VERSION ""

NS_ :

BS_:

BU_: SBZA_R_LS SBZA_L_LS VIS2_LS SDM_LS PEPS_LS UPA_LS PTM_LS MSM_LS HFP_LS EOCM_F_LS ECC_LS DCAC_LS CGM_LS BSM_LS BCM_LS AOS_LS

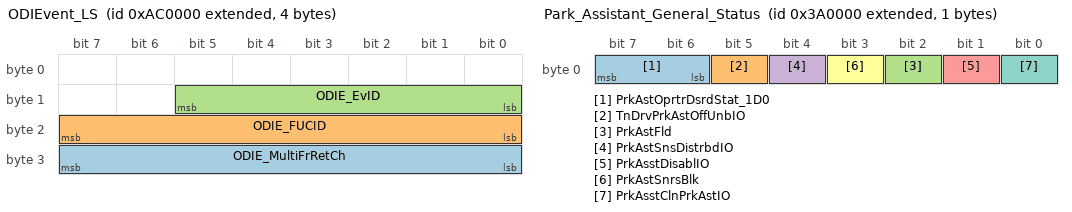
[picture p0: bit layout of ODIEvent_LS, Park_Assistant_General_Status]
BO_ 2158755840 ODIEvent_LS: 4 BCM_LS
 SG_ ODIE_MultiFrRetCh : 31|8@0+ (1,0) [0|255] ""  CGM_LS
 SG_ ODIE_FUCID : 23|8@0+ (1,0) [0|255] ""  CGM_LS
 SG_ ODIE_EvID : 13|6@0+ (1,0) [0|63] ""  CGM_LS

BO_ 2151284736 Park_Assistant_General_Status: 1 EOCM_F_LS
 SG_ PrkAstOprtrDsrdStat_1D0 : 7|2@0+ (1,0) [0|3] ""  SBZA_R_LS,SBZA_L_LS,CGM_LS
 SG_ TnDrvPrkAstOffUnbIO : 5|1@0+ (1,0) [0|1] ""  CGM_LS
 SG_ PrkAstFld : 2|1@0+ (1,0) [0|1] ""  CGM_LS
 SG_ PrkAstSnsDistrbdIO : 4|1@0+ (1,0) [0|1] ""  CGM_LS
 SG_ PrkAsstDisablIO : 1|1@0+ (1,0) [0|1] ""  CGM_LS
 SG_ PrkAstSnrsBlk : 3|1@0+ (1,0) [0|1] ""  CGM_LS
 SG_ PrkAsstClnPrkAstIO : 0|1@0+ (1,0) [0|1] ""  CGM_LS

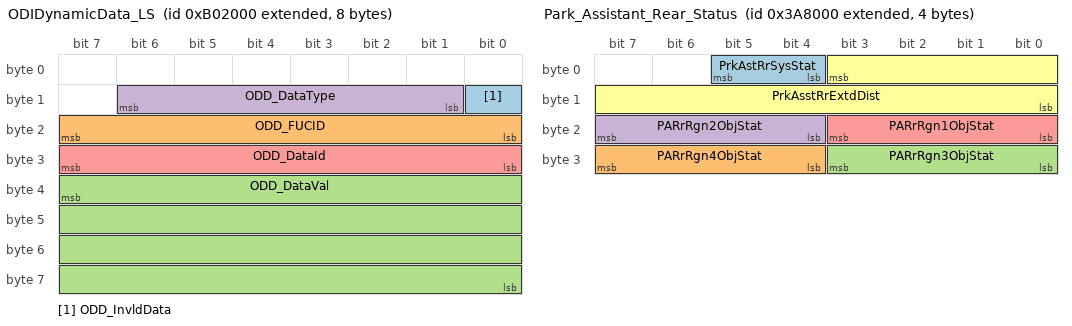
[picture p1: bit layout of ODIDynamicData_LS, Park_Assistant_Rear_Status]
BO_ 2159026176 ODIDynamicData_LS: 8 BCM_LS
 SG_ ODD_InvldData : 8|1@0+ (1,0) [0|1] ""  CGM_LS
 SG_ ODD_FUCID : 23|8@0+ (1,0) [0|255] ""  CGM_LS
 SG_ ODD_DataVal : 39|32@0+ (1,0) [0|4294967295] ""  CGM_LS
 SG_ ODD_DataType : 14|6@0+ (1,0) [0|63] ""  CGM_LS
 SG_ ODD_DataId : 31|8@0+ (1,0) [0|255] ""  CGM_LS

BO_ 2158936064 ODIEnumDynamicData_LS: 8 BCM_LS
 SG_ ODIEDD_Data18Value : 50|3@0+ (1,0) [0|7] ""  CGM_LS
 SG_ ODIEDD_Data17Value : 53|3@0+ (1,0) [0|7] ""  CGM_LS
 SG_ ODIEDD_Data16Value : 40|3@0+ (1,0) [0|7] ""  CGM_LS
 SG_ ODIEDD_Data15Value : 43|3@0+ (1,0) [0|7] ""  CGM_LS
 SG_ ODIEDD_Data14Value : 46|3@0+ (1,0) [0|7] ""  CGM_LS
 SG_ ODIEDD_Data13Value : 33|3@0+ (1,0) [0|7] ""  CGM_LS
 SG_ ODIEDD_Data12Value : 36|3@0+ (1,0) [0|7] ""  CGM_LS
 SG_ ODIEDD_Data11Value : 39|3@0+ (1,0) [0|7] ""  CGM_LS
 SG_ ODIEDD_Data10Value : 26|3@0+ (1,0) [0|7] ""  CGM_LS
 SG_ ODIEDD_Data9Value : 29|3@0+ (1,0) [0|7] ""  CGM_LS
 SG_ ODIEDD_Data8Value : 16|3@0+ (1,0) [0|7] ""  CGM_LS
 SG_ ODIEDD_Data7Value : 19|3@0+ (1,0) [0|7] ""  CGM_LS
 SG_ ODIEDD_Data6Value : 22|3@0+ (1,0) [0|7] ""  CGM_LS
 SG_ ODIEDD_Data5Value : 9|3@0+ (1,0) [0|7] ""  CGM_LS
 SG_ ODIEDD_Data4Value : 12|3@0+ (1,0) [0|7] ""  CGM_LS
 SG_ ODIEDD_Data3Value : 15|3@0+ (1,0) [0|7] ""  CGM_LS
 SG_ ODIEDD_Data2Value : 2|3@0+ (1,0) [0|7] ""  CGM_LS
 SG_ ODIEDD_Data1Value : 5|3@0+ (1,0) [0|7] ""  CGM_LS
 SG_ ODIEDD_FUCID : 63|8@0+ (1,0) [0|255] ""  CGM_LS

BO_ 2151317504 Park_Assistant_Rear_Status: 4 EOCM_F_LS
 SG_ PrkAstRrSysStat : 5|2@0+ (1,0) [0|3] ""  SBZA_R_LS,SBZA_L_LS,CGM_LS
 SG_ PARrRgn4ObjStat : 31|4@0+ (1,0) [0|15] ""  SBZA_R_LS,SBZA_L_LS,CGM_LS
 SG_ PARrRgn3ObjStat : 27|4@0+ (1,0) [0|15] ""  SBZA_R_LS,SBZA_L_LS,CGM_LS
 SG_ PARrRgn2ObjStat : 23|4@0+ (1,0) [0|15] ""  SBZA_R_LS,SBZA_L_LS,CGM_LS
 SG_ PARrRgn1ObjStat : 19|4@0+ (1,0) [0|15] ""  SBZA_R_LS,SBZA_L_LS,CGM_LS
 SG_ PrkAsstRrExtdDist : 3|12@0+ (0.01,0) [0|40.95] "m"  SBZA_R_LS,SBZA_L_LS,CGM_LS

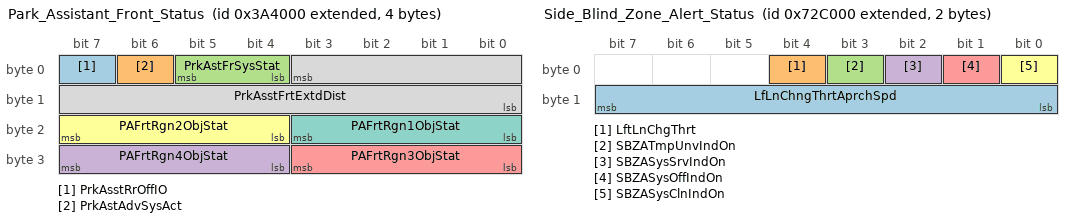
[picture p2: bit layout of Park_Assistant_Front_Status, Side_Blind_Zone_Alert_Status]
BO_ 2151301120 Park_Assistant_Front_Status: 4 UPA_LS
 SG_ PrkAsstRrOffIO : 7|1@0+ (1,0) [0|1] ""  CGM_LS
 SG_ PrkAstAdvSysAct : 6|1@0+ (1,0) [0|1] ""  EOCM_F_LS,CGM_LS,BCM_LS
 SG_ PrkAstFrSysStat : 5|2@0+ (1,0) [0|3] ""  CGM_LS
 SG_ PAFrtRgn4ObjStat : 31|4@0+ (1,0) [0|15] ""  CGM_LS
 SG_ PAFrtRgn3ObjStat : 27|4@0+ (1,0) [0|15] ""  CGM_LS
 SG_ PAFrtRgn2ObjStat : 23|4@0+ (1,0) [0|15] ""  CGM_LS
 SG_ PAFrtRgn1ObjStat : 19|4@0+ (1,0) [0|15] ""  CGM_LS
 SG_ PrkAsstFrtExtdDist : 3|12@0+ (0.01,0) [0|40.95] "m"  CGM_LS

BO_ 2155003904 Side_Blind_Zone_Alert_Status: 2 UPA_LS
 SG_ LfLnChngThrtAprchSpd : 15|8@0- (1,0) [-128|127] "km/h"  CGM_LS,BCM_LS
 SG_ LftLnChgThrt : 4|1@0+ (1,0) [0|1] ""  VIS2_LS,EOCM_F_LS,CGM_LS,BCM_LS
 SG_ SBZATmpUnvIndOn : 3|1@0+ (1,0) [0|1] ""  SBZA_R_LS,CGM_LS
 SG_ SBZASysSrvIndOn : 2|1@0+ (1,0) [0|1] ""  SBZA_R_LS,CGM_LS
 SG_ SBZASysOffIndOn : 1|1@0+ (1,0) [0|1] ""  SBZA_R_LS,CGM_LS
 SG_ SBZASysClnIndOn : 0|1@0+ (1,0) [0|1] ""  SBZA_R_LS,CGM_LS

BO_ 1369 UUDT_Resp_From_UPA_APA_LS: 8 UPA_LS
 SG_ DgnInf_LS559 : 7|64@0+ (1,0) [0|1.84467440737096E+019] ""  CGM_LS

BO_ 1625 USDT_Resp_From_UPA_APA_LS: 8 UPA_LS
 SG_ DgnInf : 7|64@0+ (1,0) [0|1.84467440737096E+019] ""  CGM_LS

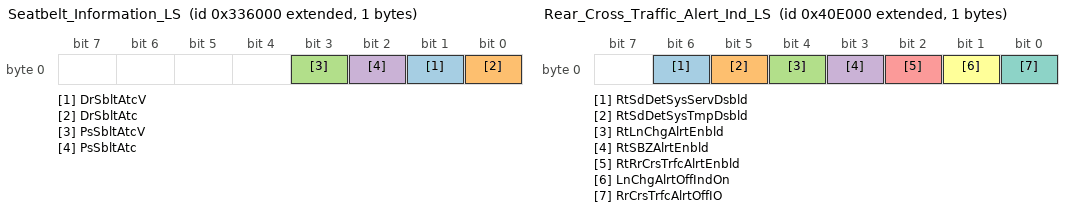
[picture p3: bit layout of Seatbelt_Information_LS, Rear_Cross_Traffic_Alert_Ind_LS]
BO_ 2150850560 Seatbelt_Information_LS: 1 SDM_LS
 SG_ DrSbltAtcV : 1|1@0+ (1,0) [0|1] ""  EOCM_F_LS,CGM_LS,BCM_LS
 SG_ DrSbltAtc : 0|1@0+ (1,0) [0|1] ""  EOCM_F_LS,CGM_LS,BCM_LS
 SG_ PsSbltAtcV : 3|1@0+ (1,0) [0|1] ""  ECC_LS,CGM_LS,BCM_LS,AOS_LS
 SG_ PsSbltAtc : 2|1@0+ (1,0) [0|1] ""  ECC_LS,CGM_LS,BCM_LS,AOS_LS

BO_ 2151735296 Rear_Cross_Traffic_Alert_Ind_LS: 1 SBZA_L_LS
 SG_ RtSdDetSysServDsbld : 6|1@0+ (1,0) [0|1] ""  SBZA_R_LS
 SG_ RtSdDetSysTmpDsbld : 5|1@0+ (1,0) [0|1] ""  SBZA_R_LS
 SG_ RtLnChgAlrtEnbld : 4|1@0+ (1,0) [0|1] ""  SBZA_R_LS
 SG_ RtSBZAlrtEnbld : 3|1@0+ (1,0) [0|1] ""  SBZA_R_LS
 SG_ RtRrCrsTrfcAlrtEnbld : 2|1@0+ (1,0) [0|1] ""  SBZA_R_LS
 SG_ LnChgAlrtOffIndOn : 1|1@0+ (1,0) [0|1] ""  SBZA_R_LS
 SG_ RrCrsTrfcAlrtOffIO : 0|1@0+ (1,0) [0|1] ""  SBZA_R_LS

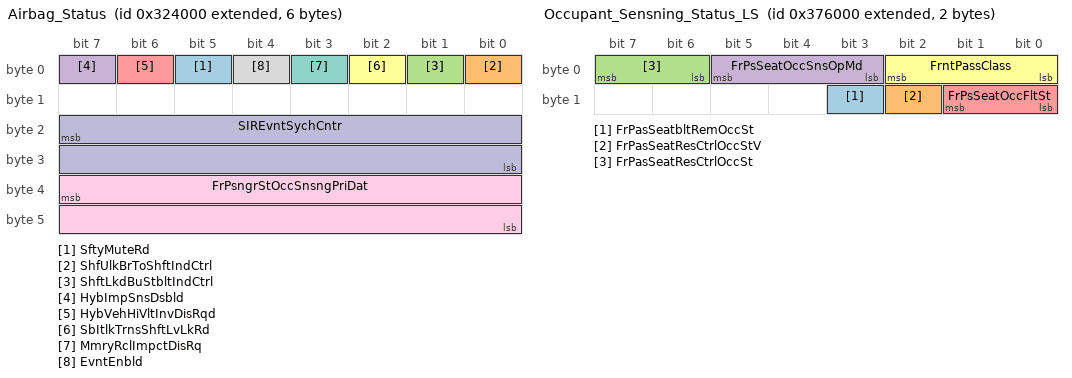
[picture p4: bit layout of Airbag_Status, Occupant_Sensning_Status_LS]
BO_ 2150776832 Airbag_Status: 6 SDM_LS
 SG_ SftyMuteRd : 5|1@0+ (1,0) [0|1] ""  CGM_LS
 SG_ ShfUlkBrToShftIndCtrl : 0|1@0+ (1,0) [0|1] ""  CGM_LS
 SG_ ShftLkdBuStbltIndCtrl : 1|1@0+ (1,0) [0|1] ""  CGM_LS
 SG_ HybImpSnsDsbld : 7|1@0+ (1,0) [0|1] ""  CGM_LS,BSM_LS,BCM_LS
 SG_ HybVehHiVltInvDisRqd : 6|1@0+ (1,0) [0|1] ""  CGM_LS,BSM_LS,BCM_LS
 SG_ SbItlkTrnsShftLvLkRd : 2|1@0+ (1,0) [0|1] ""  CGM_LS,BCM_LS
 SG_ MmryRclImpctDisRq : 3|1@0+ (1,0) [0|1] ""  PTM_LS,MSM_LS,CGM_LS,BSM_LS,BCM_LS
 SG_ EvntEnbld : 4|1@0+ (1,0) [0|1] ""  CGM_LS,AOS_LS
 SG_ FrPsngrStOccSnsngPriDat : 39|16@0+ (1,0) [0|39321] ""  CGM_LS,AOS_LS
 SG_ SIREvntSychCntr : 23|16@0+ (1,0) [0|65535] ""  EOCM_F_LS,CGM_LS,AOS_LS

BO_ 2150760448 Airbag_Impact_Data: 8 SDM_LS
 SG_ NotSndRwRtSeatStat : 13|2@0+ (1,0) [0|3] ""  CGM_LS
 SG_ NotSndRwMdlSeatStat : 11|2@0+ (1,0) [0|3] ""  CGM_LS
 SG_ NotSndRwLtSeatStat : 15|2@0+ (1,0) [0|3] ""  CGM_LS
 SG_ NotPsSeatStat : 5|2@0+ (1,0) [0|3] ""  CGM_LS
 SG_ NotDrvSeatStat : 7|2@0+ (1,0) [0|3] ""  CGM_LS
 SG_ NotSecRowRtSeaOccStat : 9|2@0+ (1,0) [0|3] ""  CGM_LS
 SG_ NotSecRowLeSeaOccStat : 25|2@0+ (1,0) [0|3] ""  CGM_LS
 SG_ NotSecRowCtSeaOccStat : 27|2@0+ (1,0) [0|3] ""  CGM_LS
 SG_ NotiFrntPasSeatOccSta : 34|3@0+ (1,0) [0|7] ""  CGM_LS
 SG_ NEDLSRtSdArbgDld : 41|1@0+ (1,0) [0|1] ""  CGM_LS
 SG_ NEDLSLtSdArbgDld : 42|1@0+ (1,0) [0|1] ""  CGM_LS
 SG_ NEDLSSdCrtnArbgDpld : 40|1@0+ (1,0) [0|1] ""  CGM_LS
 SG_ NEDLSPaFrSt2De : 43|1@0+ (1,0) [0|1] ""  CGM_LS
 SG_ NEDLSPaFrSt1De : 44|1@0+ (1,0) [0|1] ""  CGM_LS
 SG_ NEDLSDrFrSt2De : 45|1@0+ (1,0) [0|1] ""  CGM_LS
 SG_ NEDLSDrFrSt1De : 46|1@0+ (1,0) [0|1] ""  CGM_LS
 SG_ NotEventStat : 17|2@0+ (1,0) [0|3] ""  EOCM_F_LS,ECC_LS,CGM_LS,BCM_LS
 SG_ SIRDpl : 1|1@0+ (1,0) [0|1] ""  PTM_LS,PEPS_LS,VIS2_LS,EOCM_F_LS,ECC_LS,CGM_LS,BSM_LS,BCM_LS
 SG_ NotiEventCount : 63|8@0+ (1,0) [0|255] ""  EOCM_F_LS,CGM_LS,AOS_LS
 SG_ NESSRoSevSt : 48|1@0+ (1,0) [0|1] ""  EOCM_F_LS,ECC_LS,CGM_LS,BSM_LS,BCM_LS,AOS_LS
 SG_ NESSRiSiSevSt : 49|1@0+ (1,0) [0|1] ""  EOCM_F_LS,ECC_LS,CGM_LS,BSM_LS,BCM_LS,AOS_LS
 SG_ NESSReImpSevSt : 50|1@0+ (1,0) [0|1] ""  EOCM_F_LS,ECC_LS,CGM_LS,BSM_LS,BCM_LS,AOS_LS
 SG_ NESSLeSiSevSt : 51|1@0+ (1,0) [0|1] ""  EOCM_F_LS,ECC_LS,CGM_LS,BSM_LS,BCM_LS,AOS_LS
 SG_ NESSFrImpSt2SevSt : 52|1@0+ (1,0) [0|1] ""  EOCM_F_LS,ECC_LS,CGM_LS,BSM_LS,BCM_LS,AOS_LS
 SG_ NESSFrImpSt1SevSt : 53|1@0+ (1,0) [0|1] ""  EOCM_F_LS,ECC_LS,CGM_LS,BSM_LS,BCM_LS,AOS_LS
 SG_ NESSFrImpPreSevSt : 54|1@0+ (1,0) [0|1] ""  EOCM_F_LS,ECC_LS,CGM_LS,BSM_LS,BCM_LS,AOS_LS

BO_ 581 USDT_Req_to_AOS_LS: 8 CGM_LS
 SG_ DgnInf : 7|64@0+ (1,0) [0|1.84467440737096E+019] ""  AOS_LS

BO_ 2151112704 Occupant_Sensning_Status_LS: 2 AOS_LS
 SG_ FrPasSeatbltRemOccSt : 11|1@0+ (1,0) [0|1] ""  SDM_LS,CGM_LS,BCM_LS
 SG_ FrPasSeatResCtrlOccStV : 10|1@0+ (1,0) [0|1] ""  SDM_LS,ECC_LS,CGM_LS
 SG_ FrPasSeatResCtrlOccSt : 7|2@0+ (1,0) [0|3] ""  SDM_LS,ECC_LS,CGM_LS
 SG_ FrPsSeatOccSnsOpMd : 5|3@0+ (1,0) [0|7] "N/A"  SDM_LS,CGM_LS
 SG_ FrPsSeatOccFltSt : 9|2@0+ (1,0) [0|3] "N/A"  SDM_LS,MSM_LS,CGM_LS
 SG_ FrntPassClass : 2|3@0+ (1,0) [0|7] ""  SDM_LS,MSM_LS,CGM_LS

BO_ 1349 UUDT_Resp_From_AOS_LS: 8 AOS_LS
 SG_ DgnInf_LS545 : 7|64@0+ (1,0) [0|1.84467440737096E+019] ""  CGM_LS

BO_ 1605 USDT_Resp_From_AOS_LS: 8 AOS_LS
 SG_ DgnInf : 7|64@0+ (1,0) [0|1.84467440737096E+019] ""  CGM_LS

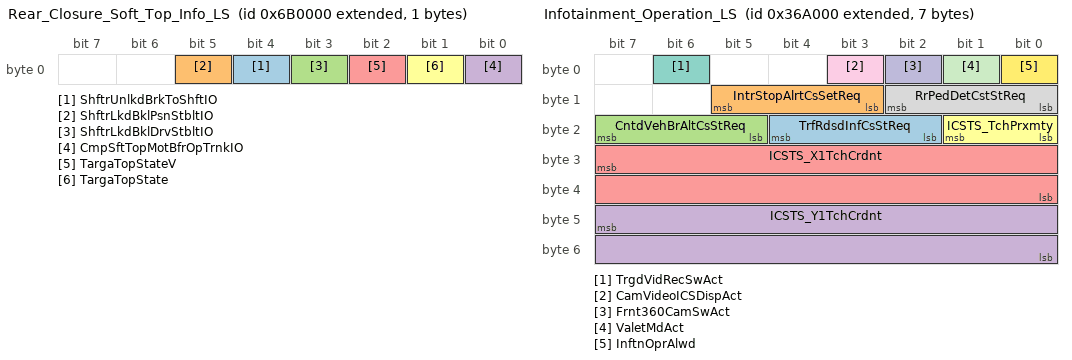
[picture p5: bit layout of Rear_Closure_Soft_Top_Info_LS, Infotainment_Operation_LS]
BO_ 2154496000 Rear_Closure_Soft_Top_Info_LS: 1 BCM_LS
 SG_ ShftrUnlkdBrkToShftIO : 4|1@0+ (1,0) [0|1] ""  CGM_LS
 SG_ ShftrLkdBklPsnStbltIO : 5|1@0+ (1,0) [0|1] ""  CGM_LS
 SG_ ShftrLkdBklDrvStbltIO : 3|1@0+ (1,0) [0|1] ""  CGM_LS
 SG_ CmpSftTopMotBfrOpTrnkIO : 0|1@0+ (1,0) [0|1] ""  CGM_LS
 SG_ TargaTopStateV : 2|1@0+ (1,0) [0|1] ""  CGM_LS
 SG_ TargaTopState : 1|1@0+ (1,0) [0|1] ""  CGM_LS

BO_ 2154471424 Rear_Closure_Ajar_Switch_Status: 1 BCM_LS
 SG_ RrClsrSnwLdIO : 1|1@0+ (1,0) [0|1] ""  CGM_LS
 SG_ RrClosAjarSwAct : 0|1@0+ (1,0) [0|1] ""  PEPS_LS,ECC_LS,CGM_LS,BCM_LS

BO_ 2151063552 Infotainment_Operation_LS: 7 CGM_LS
 SG_ TrfRdsdInfCsStReq : 20|3@0+ (1,0) [0|7] "" Vector__XXX
 SG_ IntrStopAlrtCsSetReq : 13|3@0+ (1,0) [0|7] "" Vector__XXX
 SG_ CntdVehBrAltCsStReq : 23|3@0+ (1,0) [0|7] "" Vector__XXX
 SG_ ICSTS_Y1TchCrdnt : 47|16@0+ (0.001526,0) [0|100] "" Vector__XXX
 SG_ ICSTS_X1TchCrdnt : 31|16@0+ (0.001526,0) [0|100] "" Vector__XXX
 SG_ ICSTS_TchPrxmty : 17|2@0+ (1,0) [0|3] "" Vector__XXX
 SG_ TrgdVidRecSwAct : 6|1@0+ (1,0) [0|1] "" Vector__XXX
 SG_ RrPedDetCstStReq : 10|3@0+ (1,0) [0|7] "" Vector__XXX
 SG_ CamVideoICSDispAct : 3|1@0+ (1,0) [0|1] "" Vector__XXX
 SG_ Frnt360CamSwAct : 2|1@0+ (1,0) [0|1] "" Vector__XXX
 SG_ ValetMdAct : 1|1@0+ (1,0) [0|1] ""  PTM_LS,BCM_LS
 SG_ InftnOprAlwd : 0|1@0+ (1,0) [0|1] ""  PTM_LS,BCM_LS

BO_ 1574 VNMF_LS_626_ICS: 8 CGM_LS
 SG_ VectraSpcNWMgtD : 7|64@0+ (1,0) [0|1.84467440737096E+019] ""  SBZA_R_LS,SBZA_L_LS,UPA_LS,PTM_LS,VIS2_LS,PEPS_LS,SDM_LS,MSM_LS,HFP_LS,EOCM_F_LS,ECC_LS,DCAC_LS,CGM_LS,BSM_LS,BCM_LS,AOS_LS

BO_ 1571 VNMF_LS_623_AGC: 8 DCAC_LS
 SG_ VectraSpcNWMgtD : 7|64@0+ (1,0) [0|1.84467440737096E+019] ""  SBZA_R_LS,SBZA_L_LS,UPA_LS,PTM_LS,VIS2_LS,PEPS_LS,SDM_LS,MSM_LS,HFP_LS,EOCM_F_LS,ECC_LS,CGM_LS,BSM_LS,BCM_LS,AOS_LS

BO_ 2155167744 Power_Mode_Info_LS: 3 BCM_LS
 SG_ ClsEngCmprtmtToStrtVehIO : 23|1@0+ (1,0) [0|1] ""  CGM_LS
 SG_ PrsCltchPrsStrtAgnIO : 22|1@0+ (1,0) [0|1] ""  CGM_LS
 SG_ PrsStrtAgnIO : 21|1@0+ (1,0) [0|1] ""  CGM_LS
 SG_ AutoShtdwnDsblIO : 11|1@0+ (1,0) [0|1] ""  CGM_LS
 SG_ ShftToNtrlIO : 1|1@0+ (1,0) [0|1] ""  CGM_LS
 SG_ AppPrkBrkIO : 12|1@0+ (1,0) [0|1] ""  CGM_LS
 SG_ NRmtDtctdRstrtAllwd : 20|1@0+ (1,0) [0|1] ""  CGM_LS
 SG_ NRmtDtdPsCluRstIO : 13|1@0+ (1,0) [0|1] ""  CGM_LS
 SG_ SecPwrMdPshBtnAtv : 3|1@0+ (1,0) [0|1] ""  PEPS_LS,CGM_LS
 SG_ TSLgMdPwrCtOWAtv : 19|1@0+ (1,0) [0|1] ""  CGM_LS
 SG_ PrsBtnAgnTTrnEngOffIO : 18|1@0+ (1,0) [0|1] ""  CGM_LS
 SG_ NRmtDtdPsBrkRstIO : 17|1@0+ (1,0) [0|1] ""  CGM_LS
 SG_ NoReDetInOn : 16|1@0+ (1,0) [0|1] ""  CGM_LS
 SG_ ApplyCltPdlIO : 15|1@0+ (1,0) [0|1] ""  CGM_LS
 SG_ TransModInactIO : 5|1@0+ (1,0) [0|1] ""  CGM_LS
 SG_ TransModActIO : 4|1@0+ (1,0) [0|1] ""  CGM_LS
 SG_ ApplyBrkPdlIO : 14|1@0+ (1,0) [0|1] ""  CGM_LS
 SG_ Ky_IdDevPr : 2|1@0+ (1,0) [0|1] ""  MSM_LS,CGM_LS
 SG_ KylsStrtUseTxPckIO : 6|1@0+ (1,0) [0|1] ""  CGM_LS
 SG_ ShftPrkIO : 0|1@0+ (1,0) [0|1] ""  CGM_LS
 SG_ VehMovState : 10|3@0+ (1,0) [0|7] ""  SBZA_R_LS,SBZA_L_LS,UPA_LS,VIS2_LS,PEPS_LS,MSM_LS,EOCM_F_LS,CGM_LS
 SG_ TrStLgMdAtv : 7|1@0+ (1,0) [0|1] ""  SBZA_R_LS,SBZA_L_LS,UPA_LS,PTM_LS,VIS2_LS,PEPS_LS,SDM_LS,MSM_LS,HFP_LS,ECC_LS,DCAC_LS,CGM_LS,AOS_LS

BO_ 1568 VNMF_LS_620_VICM: 8 BSM_LS
 SG_ VectraSpcNWMgtD : 7|64@0+ (1,0) [0|1.84467440737096E+019] ""  SBZA_R_LS,SBZA_L_LS,UPA_LS,PTM_LS,VIS2_LS,PEPS_LS,SDM_LS,MSM_LS,HFP_LS,EOCM_F_LS,DCAC_LS,ECC_LS,CGM_LS,BCM_LS,AOS_LS

BO_ 1570 VNMF_LS_622_PEPS_PBSM: 8 PEPS_LS
 SG_ VectraSpcNWMgtD : 7|64@0+ (1,0) [0|1.84467440737096E+019] ""  SBZA_R_LS,SBZA_L_LS,UPA_LS,PTM_LS,VIS2_LS,SDM_LS,MSM_LS,HFP_LS,EOCM_F_LS,DCAC_LS,ECC_LS,BSM_LS,CGM_LS,BCM_LS,AOS_LS

BO_ 1579 VNMF_LS_62B_FCM: 8 EOCM_F_LS
 SG_ VectraSpcNWMgtD : 7|64@0+ (1,0) [0|1.84467440737096E+019] ""  SBZA_R_LS,SBZA_L_LS,UPA_LS,PTM_LS,VIS2_LS,PEPS_LS,SDM_LS,MSM_LS,HFP_LS,DCAC_LS,ECC_LS,BSM_LS,CGM_LS,BCM_LS,AOS_LS

BO_ 1599 VNMF_LS_63F_HBSM: 8 CGM_LS
 SG_ VectraSpcNWMgtD : 7|64@0+ (1,0) [0|1.84467440737096E+019] ""  SBZA_R_LS,SBZA_L_LS,UPA_LS,PTM_LS,VIS2_LS,PEPS_LS,SDM_LS,MSM_LS,HFP_LS,EOCM_F_LS,DCAC_LS,ECC_LS,BSM_LS,CGM_LS,BCM_LS,AOS_LS

BO_ 1585 VNMF_LS_631_ECC_HVAC: 8 ECC_LS
 SG_ VectraSpcNWMgtD : 7|64@0+ (1,0) [0|1.84467440737096E+019] ""  SBZA_R_LS,SBZA_L_LS,UPA_LS,PTM_LS,VIS2_LS,PEPS_LS,SDM_LS,MSM_LS,HFP_LS,EOCM_F_LS,DCAC_LS,BSM_LS,CGM_LS,BCM_LS,AOS_LS

BO_ 1572 VNMF_LS_624_RadioHead_CHM: 8 CGM_LS
 SG_ VectraSpcNWMgtD : 7|64@0+ (1,0) [0|1.84467440737096E+019] ""  SBZA_R_LS,SBZA_L_LS,UPA_LS,PTM_LS,VIS2_LS,PEPS_LS,SDM_LS,MSM_LS,HFP_LS,EOCM_F_LS,DCAC_LS,ECC_LS,BSM_LS,CGM_LS,BCM_LS,AOS_LS

BO_ 1597 VNMF_LS_63D_DSM_HVSM_F: 8 MSM_LS
 SG_ VectraSpcNWMgtD : 7|64@0+ (1,0) [0|1.84467440737096E+019] ""  SBZA_R_LS,SBZA_L_LS,UPA_LS,PTM_LS,VIS2_LS,PEPS_LS,SDM_LS,HFP_LS,EOCM_F_LS,DCAC_LS,ECC_LS,BSM_LS,CGM_LS,BCM_LS,AOS_LS

BO_ 1576 VNMF_LS_628_PDIM: 8 CGM_LS
 SG_ VectraSpcNWMgtD : 7|64@0+ (1,0) [0|1.84467440737096E+019] ""  SBZA_R_LS,SBZA_L_LS,UPA_LS,PTM_LS,VIS2_LS,PEPS_LS,SDM_LS,MSM_LS,EOCM_F_LS,DCAC_LS,ECC_LS,BSM_LS,CGM_LS,BCM_LS,AOS_LS

BO_ 1593 VNMF_LS_639_APA_UPA: 8 UPA_LS
 SG_ VectraSpcNWMgtD : 7|64@0+ (1,0) [0|1.84467440737096E+019] ""  SBZA_R_LS,SBZA_L_LS,PTM_LS,VIS2_LS,PEPS_LS,SDM_LS,MSM_LS,HFP_LS,EOCM_F_LS,DCAC_LS,ECC_LS,BSM_LS,CGM_LS,BCM_LS,AOS_LS

BO_ 1589 VNMF_LS_635_VIS2: 8 VIS2_LS
 SG_ VectraSpcNWMgtD : 7|64@0+ (1,0) [0|1.84467440737096E+019] ""  SBZA_R_LS,SBZA_L_LS,UPA_LS,PTM_LS,PEPS_LS,SDM_LS,MSM_LS,HFP_LS,EOCM_F_LS,DCAC_LS,ECC_LS,BSM_LS,CGM_LS,BCM_LS,AOS_LS

BO_ 257 USDT_Req_to_All_LS_ECUs: 8 CGM_LS
 SG_ DgnInf : 7|64@0+ (1,0) [0|1.84467440737096E+019] ""  SBZA_R_LS,SBZA_L_LS,UPA_LS,PTM_LS,VIS2_LS,PEPS_LS,SDM_LS,MSM_LS,HFP_LS,EOCM_F_LS,DCAC_LS,ECC_LS,BSM_LS,BCM_LS,AOS_LS

BO_ 1587 VNMF_LS_633_TIM: 8 CGM_LS
 SG_ VectraSpcNWMgtD : 7|64@0+ (1,0) [0|1.84467440737096E+019] ""  SBZA_R_LS,SBZA_L_LS,UPA_LS,PTM_LS,VIS2_LS,PEPS_LS,SDM_LS,MSM_LS,HFP_LS,EOCM_F_LS,DCAC_LS,ECC_LS,BSM_LS,CGM_LS,BCM_LS,AOS_LS

BO_ 1575 VNMF_LS_627_SDM: 8 SDM_LS
 SG_ VectraSpcNWMgtD : 7|64@0+ (1,0) [0|1.84467440737096E+019] ""  SBZA_R_LS,SBZA_L_LS,UPA_LS,PTM_LS,VIS2_LS,PEPS_LS,MSM_LS,HFP_LS,EOCM_F_LS,DCAC_LS,ECC_LS,CGM_LS,BSM_LS,BCM_LS,AOS_LS

BO_ 1581 VNMF_LS_62D_UHP_ONS: 8 CGM_LS
 SG_ VectraSpcNWMgtD : 7|64@0+ (1,0) [0|1.84467440737096E+019] ""  SBZA_R_LS,SBZA_L_LS,UPA_LS,PTM_LS,VIS2_LS,PEPS_LS,SDM_LS,MSM_LS,HFP_LS,EOCM_F_LS,DCAC_LS,ECC_LS,CGM_LS,BSM_LS,BCM_LS,AOS_LS

BO_ 1580 VNMF_LS_62C_IPC: 8 CGM_LS
 SG_ VectraSpcNWMgtD : 7|64@0+ (1,0) [0|1.84467440737096E+019] ""  SBZA_R_LS,SBZA_L_LS,UPA_LS,PTM_LS,VIS2_LS,PEPS_LS,SDM_LS,MSM_LS,HFP_LS,EOCM_F_LS,DCAC_LS,ECC_LS,CGM_LS,BSM_LS,BCM_LS,AOS_LS

BO_ 1584 VNMF_LS_630_HUD: 8 CGM_LS
 SG_ VectraSpcNWMgtD : 7|64@0+ (1,0) [0|1.84467440737096E+019] ""  SBZA_R_LS,SBZA_L_LS,UPA_LS,PTM_LS,PEPS_LS,VIS2_LS,SDM_LS,MSM_LS,HFP_LS,EOCM_F_LS,DCAC_LS,ECC_LS,CGM_LS,BSM_LS,BCM_LS,AOS_LS

BO_ 1569 VNMF_LS_621_BCM: 8 BCM_LS
 SG_ VectraSpcNWMgtD : 7|64@0+ (1,0) [0|1.84467440737096E+019] ""  SBZA_R_LS,SBZA_L_LS,UPA_LS,PTM_LS,PEPS_LS,VIS2_LS,SDM_LS,MSM_LS,HFP_LS,EOCM_F_LS,DCAC_LS,ECC_LS,CGM_LS,BSM_LS,AOS_LS

BO_ 1573 VNMF_LS_625_AOS: 8 AOS_LS
 SG_ VectraSpcNWMgtD : 7|64@0+ (1,0) [0|1.84467440737096E+019] ""  SBZA_R_LS,SBZA_L_LS,UPA_LS,PTM_LS,PEPS_LS,VIS2_LS,SDM_LS,MSM_LS,HFP_LS,EOCM_F_LS,DCAC_LS,ECC_LS,CGM_LS,BSM_LS,BCM_LS

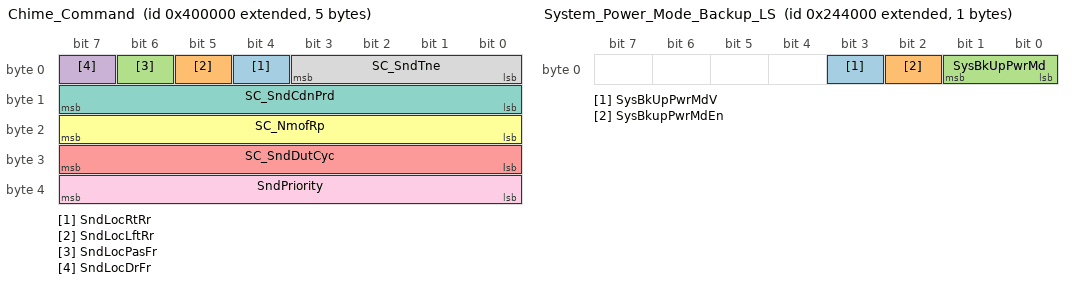
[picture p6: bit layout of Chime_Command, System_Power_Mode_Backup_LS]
BO_ 2151677952 Chime_Command: 5 SBZA_L_LS
 SG_ SndLocRtRr : 4|1@0+ (1,0) [0|1] ""  CGM_LS
 SG_ SndLocLftRr : 5|1@0+ (1,0) [0|1] ""  CGM_LS
 SG_ SndLocPasFr : 6|1@0+ (1,0) [0|1] ""  CGM_LS
 SG_ SndLocDrFr : 7|1@0+ (1,0) [0|1] ""  CGM_LS
 SG_ SC_SndDutCyc : 31|8@0+ (0.392157,0) [0|100.000035] "%"  CGM_LS
 SG_ SC_NmofRp : 23|8@0+ (1,0) [0|255] "reps"  CGM_LS
 SG_ SC_SndCdnPrd : 15|8@0+ (10,0) [0|2550] "ms"  CGM_LS
 SG_ SC_SndTne : 3|4@0+ (1,0) [0|15] ""  CGM_LS
 SG_ SndPriority : 39|8@0+ (1,0) [0|255] ""  CGM_LS

BO_ 2149859328 System_Power_Mode_Backup_LS: 1 CGM_LS
 SG_ SysBkUpPwrMdV : 3|1@0+ (1,0) [0|1] ""  SBZA_R_LS,SBZA_L_LS,UPA_LS,PTM_LS,PEPS_LS,VIS2_LS,SDM_LS,MSM_LS,HFP_LS,DCAC_LS,ECC_LS,BSM_LS,BCM_LS,AOS_LS
 SG_ SysBkupPwrMdEn : 2|1@0+ (1,0) [0|1] ""  SBZA_R_LS,UPA_LS,PTM_LS,PEPS_LS,VIS2_LS,SDM_LS,MSM_LS,HFP_LS,SBZA_L_LS,DCAC_LS,ECC_LS,BSM_LS,BCM_LS,AOS_LS
 SG_ SysBkUpPwrMd : 1|2@0+ (1,0) [0|3] ""  SBZA_R_LS,UPA_LS,PTM_LS,PEPS_LS,VIS2_LS,SDM_LS,MSM_LS,HFP_LS,SBZA_L_LS,DCAC_LS,ECC_LS,BSM_LS,BCM_LS,AOS_LS

BO_ 2150604800 Right_Rear_Door_Status: 1 BCM_LS
 SG_ RRDoorAjarSwAct : 0|1@0+ (1,0) [0|1] ""  PTM_LS,PEPS_LS,SDM_LS,ECC_LS,CGM_LS,BCM_LS

BO_ 2150588416 Passenger_Door_Status_LS: 1 BCM_LS
 SG_ PDAjrSwAtv : 0|1@0+ (1,0) [0|1] ""  PTM_LS,PEPS_LS,SDM_LS,ECC_LS,CGM_LS,AOS_LS

BO_ 2150596608 Left_Rear_Door_Status: 1 BCM_LS
 SG_ RLDoorAjarSwAct : 0|1@0+ (1,0) [0|1] ""  PEPS_LS,SDM_LS,ECC_LS,CGM_LS,BCM_LS,PTM_LS

BO_ 2150416384 Engine_Information_2_LS: 8 BCM_LS
 SG_ PTWrmgWtToShftIO : 5|1@0+ (1,0) [0|1] ""  CGM_LS
 SG_ EngTrqActExtRngV : 21|1@0+ (1,0) [0|1] ""  SDM_LS,CGM_LS
 SG_ VehTopSpdLmtMdAct : 13|1@0+ (1,0) [0|1] ""  CGM_LS
 SG_ EngTrqActExtRng : 51|12@0+ (0.5,-848) [-848|1199.5] "Nm"  SDM_LS,CGM_LS
 SG_ EngIdlAtv : 11|1@0+ (1,0) [0|1] ""  CGM_LS
 SG_ EngSpdStat : 53|2@0+ (1,0) [0|3] ""  SDM_LS,CGM_LS
 SG_ VaccBoostFailure : 2|1@0+ (1,0) [0|1] ""  CGM_LS
 SG_ RmVhStrtEngRng : 54|1@0+ (1,0) [0|1] ""  ECC_LS,CGM_LS
 SG_ EngCoolFanSpd : 31|8@0+ (0.392157,0) [0|100.000035] "%"  ECC_LS,CGM_LS
 SG_ GenFld : 3|1@0+ (1,0) [0|1] ""  CGM_LS
 SG_ EngSpdLmtnMdAct : 4|1@0+ (1,0) [0|1] ""  CGM_LS
 SG_ EngNEmsnsRelMalfAct : 6|1@0+ (1,0) [0|1] ""  CGM_LS
 SG_ EngCstFlCutAct : 7|1@0+ (1,0) [0|1] ""  ECC_LS,CGM_LS
 SG_ EngBstPrsIndV : 0|1@0+ (1,0) [0|1] ""  CGM_LS
 SG_ EngBstPrsInd : 39|8@0+ (0.392157,0) [0|100.000035] "%"  CGM_LS
 SG_ TrnCrpMdAtv : 55|1@0+ (1,0) [0|1] ""  CGM_LS
 SG_ VehTopSpdLmtArbVal : 47|8@0+ (2,0) [0|510] "km / h"  CGM_LS
 SG_ TrnsVDA : 23|1@0+ (1,0) [0|1] ""  SBZA_R_LS,UPA_LS,PEPS_LS,SDM_LS,ECC_LS,SBZA_L_LS,CGM_LS,PTM_LS
 SG_ TransEstGear : 19|4@0+ (1,0) [0|15] ""  UPA_LS,SDM_LS,CGM_LS,PTM_LS
 SG_ TransEstGearV : 20|1@0+ (1,0) [0|1] ""  UPA_LS,SDM_LS,CGM_LS,PTM_LS
 SG_ EngVDA : 22|1@0+ (1,0) [0|1] ""  SBZA_R_LS,UPA_LS,SDM_LS,PEPS_LS,ECC_LS,SBZA_L_LS,CGM_LS,PTM_LS
 SG_ EngRunAtv : 8|1@0+ (1,0) [0|1] ""  SBZA_R_LS,UPA_LS,SDM_LS,MSM_LS,VIS2_LS,HFP_LS,DCAC_LS,ECC_LS,SBZA_L_LS,CGM_LS,AOS_LS
 SG_ EngCylDeactMd : 15|2@0+ (1,0) [0|3] ""  CGM_LS

BO_ 2150408192 Engine_Information_1_LS: 8 BCM_LS
 SG_ ElcRngSelDrvAct : 5|1@0+ (1,0) [0|1] ""  CGM_LS
 SG_ TmpDrvrShftCtlAct : 6|1@0+ (1,0) [0|1] ""  CGM_LS
 SG_ AdptPsngrSeatStng : 63|3@0+ (1,0) [0|7] ""  CGM_LS
 SG_ EngRunng : 14|1@0+ (1,0) [0|1] ""  DCAC_LS,ECC_LS,CGM_LS
 SG_ Eng12vStrtrMtrCmmdOn : 13|1@0+ (1,0) [0|1] ""  DCAC_LS,CGM_LS
 SG_ AccPdlOvrrdAtv : 7|1@0+ (1,0) [0|1] ""  CGM_LS
 SG_ TopTrvlCltchSwActV : 60|1@0+ (1,0) [0|1] ""  CGM_LS
 SG_ TopTrvlCltchSwAct : 59|1@0+ (1,0) [0|1] ""  CGM_LS
 SG_ CltStartSwAtvV : 58|1@0+ (1,0) [0|1] ""  CGM_LS
 SG_ CltStartSwAtv : 57|1@0+ (1,0) [0|1] ""  CGM_LS
 SG_ CrsCntEnbld : 56|1@0+ (1,0) [0|1] ""  VIS2_LS,CGM_LS
 SG_ AccActPosV : 4|1@0+ (1,0) [0|1] ""  SDM_LS,CGM_LS
 SG_ TrnsSftMdStat : 2|3@0+ (1,0) [0|7] ""  CGM_LS
 SG_ AutoTransComndGear : 55|4@0+ (1,0) [0|15] ""  CGM_LS
 SG_ TrnShftPtrnActStat : 10|3@0+ (1,0) [0|7] ""  CGM_LS
 SG_ AccActPos : 47|8@0+ (0.392157,0) [0|100.000035] "%"  SDM_LS,CGM_LS
 SG_ ThrPosV : 3|1@0+ (1,0) [0|1] ""  SDM_LS,CGM_LS
 SG_ TransTUDMdStat : 12|2@0+ (1,0) [0|3] ""  CGM_LS
 SG_ ThrPos : 39|8@0+ (0.392157,0) [0|100.000035] "%"  SDM_LS,CGM_LS
 SG_ TrnsShftLvrPosV : 15|1@0+ (1,0) [0|1] ""  SBZA_R_LS,UPA_LS,SDM_LS,SBZA_L_LS,CGM_LS,PTM_LS
 SG_ TrnsShftLvrPos : 51|4@0+ (1,0) [0|15] ""  SBZA_R_LS,UPA_LS,SDM_LS,CGM_LS,SBZA_L_LS,PTM_LS
 SG_ EngSpd : 23|16@0+ (0.25,0) [0|16383.75] "rpm"  SDM_LS,DCAC_LS,ECC_LS,CGM_LS

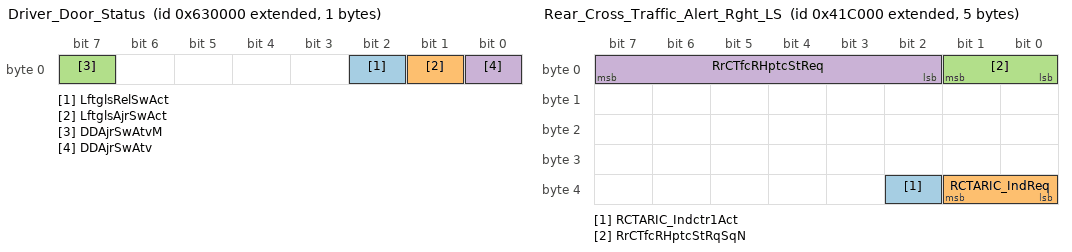
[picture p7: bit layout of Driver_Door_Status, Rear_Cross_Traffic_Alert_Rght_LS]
BO_ 2153971712 Driver_Door_Status: 1 BCM_LS
 SG_ LftglsRelSwAct : 2|1@0+ (1,0) [0|1] ""  PEPS_LS,CGM_LS
 SG_ LftglsAjrSwAct : 1|1@0+ (1,0) [0|1] ""  CGM_LS,PTM_LS
 SG_ DDAjrSwAtvM : 7|1@0+ (1,0) [0|1] ""  MSM_LS,VIS2_LS,CGM_LS,PTM_LS
 SG_ DDAjrSwAtv : 0|1@0+ (1,0) [0|1] ""  SDM_LS,PEPS_LS,MSM_LS,VIS2_LS,EOCM_F_LS,ECC_LS,CGM_LS,BSM_LS,PTM_LS

BO_ 2151792640 Rear_Cross_Traffic_Alert_Rght_LS: 5 SBZA_L_LS
 SG_ RCTARIC_Indctr1Act : 34|1@0+ (1,0) [0|1] ""  CGM_LS
 SG_ RCTARIC_IndReq : 33|2@0+ (1,0) [0|3] ""  CGM_LS
 SG_ RrCTfcRHptcStRqSqN : 1|2@0+ (1,0) [0|3] ""  CGM_LS,MSM_LS
 SG_ RrCTfcRHptcStReq : 7|6@0+ (1,0) [0|63] ""  CGM_LS,MSM_LS

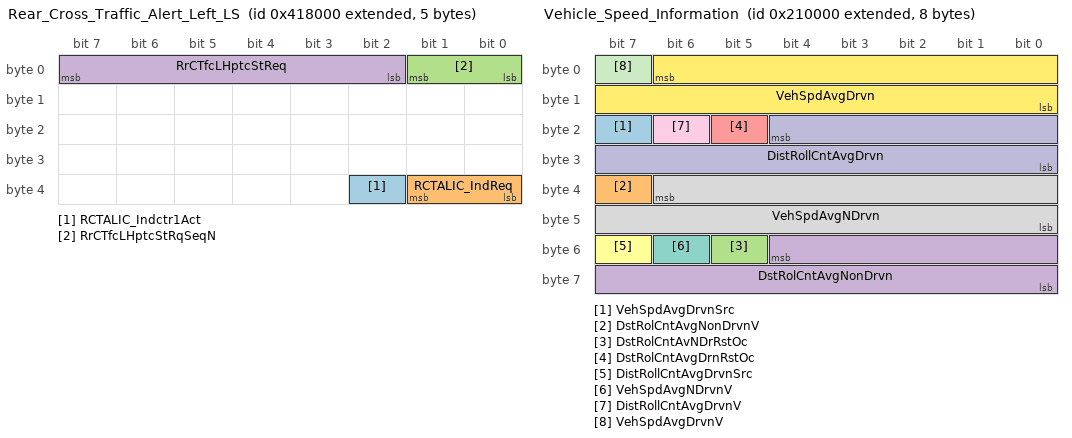
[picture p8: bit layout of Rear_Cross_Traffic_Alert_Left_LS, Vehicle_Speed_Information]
BO_ 2151776256 Rear_Cross_Traffic_Alert_Left_LS: 5 SBZA_L_LS
 SG_ RCTALIC_Indctr1Act : 34|1@0+ (1,0) [0|1] ""  CGM_LS
 SG_ RCTALIC_IndReq : 33|2@0+ (1,0) [0|3] ""  CGM_LS
 SG_ RrCTfcLHptcStRqSeqN : 1|2@0+ (1,0) [0|3] ""  CGM_LS,MSM_LS
 SG_ RrCTfcLHptcStReq : 7|6@0+ (1,0) [0|63] ""  CGM_LS,MSM_LS

BO_ 2149646336 Vehicle_Speed_Information: 8 BCM_LS
 SG_ VehSpdAvgDrvnSrc : 23|1@0+ (1,0) [0|1] ""  CGM_LS
 SG_ DstRolCntAvgNonDrvnV : 39|1@0+ (1,0) [0|1] ""  CGM_LS
 SG_ DstRolCntAvNDrRstOc : 53|1@0+ (1,0) [0|1] ""  CGM_LS
 SG_ DstRolCntAvgNonDrvn : 52|13@0+ (0.125,0) [0|1023.875] "m"  CGM_LS
 SG_ DstRolCntAvgDrnRstOc : 21|1@0+ (1,0) [0|1] ""  CGM_LS
 SG_ DistRollCntAvgDrvnSrc : 55|1@0+ (1,0) [0|1] ""  CGM_LS
 SG_ VehSpdAvgNDrvnV : 54|1@0+ (1,0) [0|1] ""  UPA_LS,SDM_LS,EOCM_F_LS,ECC_LS,CGM_LS
 SG_ VehSpdAvgNDrvn : 38|15@0+ (0.015625,0) [0|511.984375] "km / h"  SBZA_R_LS,UPA_LS,SDM_LS,EOCM_F_LS,ECC_LS,CGM_LS,SBZA_L_LS
 SG_ DistRollCntAvgDrvnV : 22|1@0+ (1,0) [0|1] ""  SBZA_R_LS,SDM_LS,CGM_LS,SBZA_L_LS
 SG_ DistRollCntAvgDrvn : 20|13@0+ (0.125,0) [0|1023.875] "m"  SBZA_R_LS,SDM_LS,CGM_LS,SBZA_L_LS
 SG_ VehSpdAvgDrvnV : 7|1@0+ (1,0) [0|1] ""  SBZA_R_LS,UPA_LS,SDM_LS,PEPS_LS,MSM_LS,EOCM_F_LS,ECC_LS,CGM_LS,SBZA_L_LS,VIS2_LS,AOS_LS,PTM_LS
 SG_ VehSpdAvgDrvn : 6|15@0+ (0.015625,0) [0|511.984375] "km / h"  SBZA_R_LS,UPA_LS,SDM_LS,PEPS_LS,MSM_LS,HFP_LS,EOCM_F_LS,ECC_LS,CGM_LS,SBZA_L_LS,BSM_LS,VIS2_LS,AOS_LS,PTM_LS

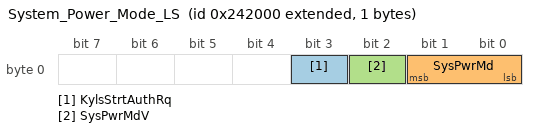
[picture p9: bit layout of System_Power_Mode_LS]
BO_ 2149851136 System_Power_Mode_LS: 1 BCM_LS
 SG_ KylsStrtAuthRq : 3|1@0+ (1,0) [0|1] ""  PEPS_LS,CGM_LS
 SG_ SysPwrMd : 1|2@0+ (1,0) [0|3] ""  SBZA_R_LS,UPA_LS,SDM_LS,PEPS_LS,MSM_LS,HFP_LS,ECC_LS,DCAC_LS,CGM_LS,SBZA_L_LS,VIS2_LS,AOS_LS,PTM_LS
 SG_ SysPwrMdV : 2|1@0+ (1,0) [0|1] ""  SBZA_R_LS,UPA_LS,SDM_LS,PEPS_LS,MSM_LS,HFP_LS,ECC_LS,DCAC_LS,CGM_LS,SBZA_L_LS,AOS_LS,VIS2_LS,PTM_LS

BO_ 2151718912 Chime_Active: 1 CGM_LS
 SG_ ChmVolSt : 2|2@0+ (1,0) [0|3] "" Vector__XXX
 SG_ ChmAct : 0|1@0+ (1,0) [0|1] ""  UPA_LS,PTM_LS,SDM_LS,EOCM_F_LS,BSM_LS,BCM_LS

BO_ 2153775104 DTC_Triggered: 7 AOS_LS
 SG_ DTCI_DTCFaultType : 55|8@0+ (1,0) [0|255] ""  CGM_LS
 SG_ DTCI_CodeSupported : 40|1@0+ (1,0) [0|1] ""  CGM_LS
 SG_ DTCI_CurrentStatus : 41|1@0+ (1,0) [0|1] ""  CGM_LS
 SG_ DTCI_TstNPsdCdClrdSt : 42|1@0+ (1,0) [0|1] ""  CGM_LS
 SG_ DTCI_TstFldCdClrdStat : 43|1@0+ (1,0) [0|1] ""  CGM_LS
 SG_ DTCI_HistStat : 44|1@0+ (1,0) [0|1] ""  CGM_LS
 SG_ DTCI_TstNPsdPwrUpSt : 45|1@0+ (1,0) [0|1] ""  CGM_LS
 SG_ DTCI_TstFldPwrUpSt : 46|1@0+ (1,0) [0|1] ""  CGM_LS
 SG_ DTCI_WrnIndRqdSt : 47|1@0+ (1,0) [0|1] ""  CGM_LS
 SG_ DTCI_DTCFailType : 39|8@0+ (1,0) [0|255] ""  CGM_LS
 SG_ DTCI_DTCNumber : 23|16@0+ (1,0) [0|65535] ""  CGM_LS
 SG_ DTCI_DTCSource : 15|8@0+ (1,0) [0|255] ""  CGM_LS
 SG_ DTCI_DTCTriggered : 0|1@0+ (1,0) [0|1] ""  CGM_LS
 SG_ DTCIUnused7 : 7|1@0+ (1,0) [0|1] ""  CGM_LS
 SG_ DTCIUnused6 : 6|1@0+ (1,0) [0|1] ""  CGM_LS
 SG_ DTCIUnused5 : 5|1@0+ (1,0) [0|1] ""  CGM_LS
 SG_ DTCIUnused4 : 4|1@0+ (1,0) [0|1] ""  CGM_LS
 SG_ DTCIUnused3 : 3|1@0+ (1,0) [0|1] ""  CGM_LS
 SG_ DTCIUnused2 : 2|1@0+ (1,0) [0|1] ""  CGM_LS
 SG_ DTCIUnused1 : 1|1@0+ (1,0) [0|1] ""  CGM_LS

BO_ 1364 UUDT_Resp_From_AMP_LS: 8 CGM_LS
 SG_ DgnInf_LS554 : 7|64@0+ (1,0) [0|1.84467440737096E+019] ""  CGM_LS

BO_ 1588 VNMF_LS_634_AMP: 8 CGM_LS
 SG_ VectraSpcNWMgtD : 7|64@0+ (1,0) [0|1.84467440737096E+019] ""  SBZA_R_LS,SBZA_L_LS,UPA_LS,PTM_LS,PEPS_LS,VIS2_LS,SDM_LS,MSM_LS,HFP_LS,EOCM_F_LS,DCAC_LS,ECC_LS,CGM_LS,BSM_LS,BCM_LS,AOS_LS

BO_ 1594 VNMF_LS_63A_SBZA_L: 8 SBZA_L_LS
 SG_ VectraSpcNWMgtD : 7|64@0+ (1,0) [0|1.84467440737096E+019] ""  SBZA_R_LS

BO_ 1370 UUDT_Resp_From_SBZA_L_LS: 8 SBZA_L_LS
 SG_ DgnInf_LS55A : 7|64@0+ (1,0) [0|1.84467440737096E+019] ""  CGM_LS

BO_ 872 Temp_Diag_CAN_Resp_LS_368: 8 Vector__XXX
 SG_ DgnInf : 7|64@0+ (1,0) [0|1.84467440737096E+019] ""  CGM_LS

BO_ 1626 USDT_Resp_From_SBZA_L_LS: 8 SBZA_L_LS
 SG_ DgnInf : 7|64@0+ (1,0) [0|1.84467440737096E+019] ""  CGM_LS

BO_ 1583 VNMF_LS_62F_PTM_STC: 8 PTM_LS
 SG_ VectraSpcNWMgtD : 7|64@0+ (1,0) [0|1.84467440737096E+019] ""  SBZA_R_LS,SBZA_L_LS,UPA_LS

BO_ 1615 USDT_Resp_From_PTM_STC_LS: 8 PTM_LS
 SG_ DgnInf : 7|64@0+ (1,0) [0|1.84467440737096E+019] ""  CGM_LS

BO_ 1359 UUDT_Resp_From_PTM_STC_LS: 8 PTM_LS
 SG_ DgnInf_LS54F : 7|64@0+ (1,0) [0|1.84467440737096E+019] ""  CGM_LS

BO_TX_BU_ 2158755840 : VIS2_LS,ECC_LS,BCM_LS;
BO_TX_BU_ 2151284736 : UPA_LS,EOCM_F_LS;
BO_TX_BU_ 2159026176 : VIS2_LS,ECC_LS,BCM_LS;
BO_TX_BU_ 2158936064 : SBZA_L_LS,UPA_LS,MSM_LS,EOCM_F_LS,ECC_LS,BCM_LS;
BO_TX_BU_ 2151317504 : UPA_LS,EOCM_F_LS;
BO_TX_BU_ 2155003904 : SBZA_L_LS,UPA_LS;
BO_TX_BU_ 2154471424 : PTM_LS,BCM_LS;
BO_TX_BU_ 1576 : HFP_LS,CGM_LS;
BO_TX_BU_ 2151677952 : SBZA_R_LS,UPA_LS,PTM_LS,VIS2_LS,SDM_LS,MSM_LS,EOCM_F_LS,BSM_LS,BCM_LS,SBZA_L_LS;
BO_TX_BU_ 2151792640 : SBZA_R_LS,SBZA_L_LS;
BO_TX_BU_ 2153775104 : SBZA_R_LS,SBZA_L_LS,UPA_LS,PTM_LS,VIS2_LS,SDM_LS,PEPS_LS,MSM_LS,HFP_LS,ECC_LS,DCAC_LS,BCM_LS,AOS_LS;
CM_ SG_ 2158755840 ODIE_FUCID "ODI - Primary ID of Functional Unit in FU Database";
CM_ SG_ 2158755840 ODIE_EvID "EventID within FUClass";
CM_ SG_ 2151284736 PrkAstSnsDistrbdIO "This signal turns on a warning that tells the driver that the Parking Assist is receiving ultrasonic input that essentially makes it blind.  The system is still enabled, there is no failure in the system, but it can't perform the function.";
CM_ SG_ 2159026176 ODD_InvldData "ODI";
CM_ SG_ 2159026176 ODD_FUCID "ODI - Primary ID of Functional Unit in FU Database";
CM_ SG_ 2159026176 ODD_DataVal "ODI";
CM_ SG_ 2159026176 ODD_DataType "ODI";
CM_ SG_ 2159026176 ODD_DataId "ODI-Data Id for the dynamic list";
CM_ SG_ 2158936064 ODIEDD_Data18Value "ODI";
CM_ SG_ 2158936064 ODIEDD_Data17Value "ODI";
CM_ SG_ 2158936064 ODIEDD_Data16Value "ODI";
CM_ SG_ 2158936064 ODIEDD_Data15Value "ODI";
CM_ SG_ 2158936064 ODIEDD_Data14Value "ODI";
CM_ SG_ 2158936064 ODIEDD_Data13Value "ODI";
CM_ SG_ 2158936064 ODIEDD_Data12Value "ODI";
CM_ SG_ 2158936064 ODIEDD_Data11Value "ODI";
CM_ SG_ 2158936064 ODIEDD_Data10Value "ODI";
CM_ SG_ 2158936064 ODIEDD_Data9Value "ODI";
CM_ SG_ 2158936064 ODIEDD_Data8Value "ODI";
CM_ SG_ 2158936064 ODIEDD_Data7Value "ODI";
CM_ SG_ 2158936064 ODIEDD_Data6Value "ODI";
CM_ SG_ 2158936064 ODIEDD_Data5Value "ODI";
CM_ SG_ 2158936064 ODIEDD_Data4Value "ODI";
CM_ SG_ 2158936064 ODIEDD_Data3Value "ODI";
CM_ SG_ 2158936064 ODIEDD_Data2Value "ODI";
CM_ SG_ 2158936064 ODIEDD_Data1Value "ODI";
CM_ SG_ 2158936064 ODIEDD_FUCID "ODI - Primary ID of Functional Unit in FU Database";
CM_ SG_ 2151317504 PARrRgn4ObjStat "Regions are segments across the width of the vehicle (X coordinate).  Zones are distances from the vehicle (Y coordinate).";
CM_ SG_ 2151317504 PARrRgn3ObjStat "Regions are segments across the width of the vehicle (X coordinate).  Zones are distances from the vehicle (Y coordinate).";
CM_ SG_ 2151317504 PARrRgn2ObjStat "Regions are segments across the width of the vehicle (X coordinate).  Zones are distances from the vehicle (Y coordinate).";
CM_ SG_ 2151317504 PARrRgn1ObjStat "Regions are segments across the width of the vehicle (X coordinate).  Zones are distances from the vehicle (Y coordinate).";
CM_ SG_ 2151301120 PAFrtRgn4ObjStat "Regions are segments across the width of the vehicle (X coordinate).  Zones are distances from the vehicle (Y coordinate).";
CM_ SG_ 2151301120 PAFrtRgn3ObjStat "Regions are segments across the width of the vehicle (X coordinate).  Zones are distances from the vehicle (Y coordinate).";
CM_ SG_ 2151301120 PAFrtRgn2ObjStat "Regions are segments across the width of the vehicle (X coordinate).  Zones are distances from the vehicle (Y coordinate).";
CM_ SG_ 2151301120 PAFrtRgn1ObjStat "Regions are segments across the width of the vehicle (X coordinate).  Zones are distances from the vehicle (Y coordinate).";
CM_ SG_ 2151112704 FrPsSeatOccSnsOpMd "TBD";
CM_ SG_ 2151112704 FrPsSeatOccFltSt "TBD";
CM_ SG_ 2155167744 NRmtDtdPsBrkRstIO "Used to display notification to the driver that they do not have the fob in the vehicle when they pressed the off button.  Gives the driver a chance to obtain the fob before shutting off the car.";
CM_ SG_ 2150416384 EngRunAtv "Indication from powertrain that the engine is running (Has RPM > 0)";
CM_ SG_ 2150408192 TrnShftPtrnActStat "(PT = Powertrain)";
CM_ SG_ 2153775104 DTCI_DTCFaultType "Based on Powertrain definition.  Not expected to be supported by all devices.";
CM_ SG_ 2153775104 DTCI_DTCFailType "Assigned per GMW3110, Appendix E";
CM_ SG_ 2153775104 DTCI_DTCSource "This shall be equal to the Diagnostic Address of the transmittting device.";
BA_DEF_ SG_  "VNSigDiagnostic" ENUM  "No","Yes","DLCLS","DLCHS","DLCCE","DLCFO";
BA_DEF_ SG_  "VNSigUnused_4" ENUM  "No","Yes","DLCLS","DLCHS","DLCCE","DLCFO";
BA_DEF_ SG_  "VNSigIntermediate" ENUM  "No","Yes","DLCLS","DLCHS","DLCCE","DLCFO";
BA_DEF_ SG_  "VNSigParkedVehicle" ENUM  "No","Yes","DLCLS","DLCHS","DLCCE","DLCFO";
BA_DEF_ SG_  "VNSigRemoteDiagnostics" ENUM  "No","Yes","DLCLS","DLCHS","DLCCE","DLCFO";
BA_DEF_ SG_  "GenSigSendOnInit" ENUM  "Not Initialized","Application","Handler","DLCLS","DLCHS","DLCCE","DLCFO";
BA_DEF_ SG_  "GenSigSendType" ENUM  "not used","not used","not used","not used","not used","not used","not used","NoSigSendType","not used","not used","OnAnyChange","OnChangeIfActive","OnDelta","DLCLS","DLCHS","DLCCE","DLCFO";
BA_DEF_ SG_  "GenSigInactiveValue" INT 0 0;
BA_DEF_ SG_  "GenSigDeltaValue" INT 0 0;
BA_DEF_ SG_  "VNSigAllNodes" ENUM  "No","Yes","DLCLS","DLCHS","DLCCE","DLCFO";
BA_DEF_ SG_  "SignalType" STRING ;
BA_DEF_ SG_  "PacketOrder" INT 0 65535;
BA_DEF_ SG_  "SignalLongName" STRING ;
BA_DEF_ SG_  "GenSigStartValue" INT 0 65535;
BA_DEF_ SG_  "TxSignalSendOnInit" ENUM  "Not Initialized","Application","Handler";
BA_DEF_ BO_  "GenMsgILSupport" ENUM  "No","Yes","DLCLS","DLCHS","DLCCE","DLCFO";
BA_DEF_ BO_  "TpApplType" STRING ;
BA_DEF_ BO_  "Prio" INT 0 7;
BA_DEF_ BO_  "MessageSubnet" ENUM  "LS","MS","HS","CE","PE","HV","FO","S1","HE","LE","HE2","DLCLS","DLCHS","DLCCE","DLCFO","vector_leerstring";
BA_DEF_ BO_  "DiagState" ENUM  "No","Yes";
BA_DEF_ BO_  "GenMsgIlSupport" ENUM  "No","Yes";
BA_DEF_ BO_  "GenMsgStartDelayTime" INT 0 100000;
BA_DEF_ BO_  "GenMsgDelayTime" INT 0 100000;
BA_DEF_ BO_  "GenMsgCycleTime" INT 0 100000;
BA_DEF_ BO_  "GenMsgSendType" ENUM  "cyclicX","spontanX","cyclicIfActiveX","spontanWithDelay","cyclicAndSpontanX","cyclicAndSpontanWithDelay","spontanWithRepitition","cyclicIfActiveAndSpontanWD";
BA_DEF_ BO_  "DiagResponse" ENUM  "No","Yes";
BA_DEF_ BO_  "DiagRequest" ENUM  "No","Yes";
BA_DEF_ BO_  "NmMessage" ENUM  "No","Yes";
BA_DEF_REL_ BU_SG_REL_  "GenSigSuprvResp" ENUM  "None","Notify App","Substitute Default","DLCLS","DLCHS","DLCCE","DLCFO";
BA_DEF_REL_ BU_SG_REL_  "GenSigSuprvRespSubValue" INT 0 65535;
BA_DEF_REL_ BU_SG_REL_  "GenSigRxStartValue" STRING ;
BA_DEF_REL_ BU_SG_REL_  "GenSigVDAFailResp" ENUM  "No","Yes","DLCLS","DLCHS","DLCCE","DLCFO";
BA_DEF_REL_ BU_SG_REL_  "GenSigVDAFailComment" STRING ;
BA_DEF_REL_ BU_SG_REL_  "GenSigVBitRespComment" STRING ;
BA_DEF_REL_ BU_SG_REL_  "GenSigVBitResp" ENUM  "No","Yes","DLCLS","DLCHS","DLCCE","DLCFO";
BA_DEF_REL_ BU_SG_REL_  "GenSigSuprvRespComment" STRING ;
BA_DEF_REL_ BU_SG_REL_  "GenSigTimeoutTime" INT 0 5000;
BA_DEF_DEF_  "VNSigDiagnostic" "No";
BA_DEF_DEF_  "VNSigUnused_4" "No";
BA_DEF_DEF_  "VNSigIntermediate" "No";
BA_DEF_DEF_  "VNSigParkedVehicle" "No";
BA_DEF_DEF_  "VNSigRemoteDiagnostics" "No";
BA_DEF_DEF_  "GenSigSendOnInit" "Not Initialized";
BA_DEF_DEF_  "GenSigSendType" "NoSigSendType";
BA_DEF_DEF_  "GenSigInactiveValue" 0;
BA_DEF_DEF_  "GenSigDeltaValue" 0;
BA_DEF_DEF_  "VNSigAllNodes" "No";
BA_DEF_DEF_  "SignalType" "";
BA_DEF_DEF_  "PacketOrder" 0;
BA_DEF_DEF_  "SignalLongName" "";
BA_DEF_DEF_  "GenSigStartValue" 0;
BA_DEF_DEF_  "TxSignalSendOnInit" "Not Initialized";
BA_DEF_DEF_  "GenMsgILSupport" "Yes";
BA_DEF_DEF_  "TpApplType" "";
BA_DEF_DEF_  "Prio" 0;
BA_DEF_DEF_  "MessageSubnet" "LS";
BA_DEF_DEF_  "DiagState" "No";
BA_DEF_DEF_  "GenMsgIlSupport" "Yes";
BA_DEF_DEF_  "GenMsgStartDelayTime" 0;
BA_DEF_DEF_  "GenMsgDelayTime" 0;
BA_DEF_DEF_  "GenMsgCycleTime" 0;
BA_DEF_DEF_  "GenMsgSendType" "spontanX";
BA_DEF_DEF_  "DiagResponse" "No";
BA_DEF_DEF_  "DiagRequest" "No";
BA_DEF_DEF_  "NmMessage" "No";
BA_DEF_DEF_REL_ "GenSigSuprvResp" "None";
BA_DEF_DEF_REL_ "GenSigSuprvRespSubValue" 0;
BA_DEF_DEF_REL_ "GenSigRxStartValue" "";
BA_DEF_DEF_REL_ "GenSigVDAFailResp" "No";
BA_DEF_DEF_REL_ "GenSigVDAFailComment" "";
BA_DEF_DEF_REL_ "GenSigVBitRespComment" "";
BA_DEF_DEF_REL_ "GenSigVBitResp" "No";
BA_DEF_DEF_REL_ "GenSigSuprvRespComment" "";
BA_DEF_DEF_REL_ "GenSigTimeoutTime" 0;
BA_ "Prio" BO_ 2158755840 4;
BA_ "GenMsgDelayTime" BO_ 2158755840 100;
BA_ "Prio" BO_ 2151284736 4;
BA_ "GenMsgDelayTime" BO_ 2151284736 100;
BA_ "Prio" BO_ 2159026176 4;
BA_ "GenMsgDelayTime" BO_ 2159026176 10;
BA_ "Prio" BO_ 2158936064 4;
BA_ "GenMsgDelayTime" BO_ 2158936064 100;
BA_ "Prio" BO_ 2151317504 4;
BA_ "GenMsgDelayTime" BO_ 2151317504 100;
BA_ "Prio" BO_ 2151301120 4;
BA_ "GenMsgDelayTime" BO_ 2151301120 100;
BA_ "Prio" BO_ 2155003904 4;
BA_ "GenMsgDelayTime" BO_ 2155003904 100;
BA_ "GenMsgILSupport" BO_ 1369 0;
BA_ "TpApplType" BO_ 1369 "DiagUUDTResponse";
BA_ "DiagResponse" BO_ 1625 1;
BA_ "Prio" BO_ 2150850560 4;
BA_ "GenMsgDelayTime" BO_ 2150850560 100;
BA_ "Prio" BO_ 2151735296 4;
BA_ "GenMsgDelayTime" BO_ 2151735296 100;
BA_ "Prio" BO_ 2150776832 4;
BA_ "GenMsgDelayTime" BO_ 2150776832 10;
BA_ "GenMsgCycleTime" BO_ 2150776832 2000;
BA_ "GenMsgSendType" BO_ 2150776832 0;
BA_ "Prio" BO_ 2150760448 4;
BA_ "GenMsgDelayTime" BO_ 2150760448 10;
BA_ "DiagRequest" BO_ 581 1;
BA_ "Prio" BO_ 2151112704 4;
BA_ "GenMsgDelayTime" BO_ 2151112704 100;
BA_ "GenMsgILSupport" BO_ 1349 0;
BA_ "TpApplType" BO_ 1349 "DiagUUDTResponse";
BA_ "DiagResponse" BO_ 1605 1;
BA_ "Prio" BO_ 2154496000 4;
BA_ "GenMsgDelayTime" BO_ 2154496000 100;
BA_ "Prio" BO_ 2154471424 3;
BA_ "GenMsgDelayTime" BO_ 2154471424 100;
BA_ "Prio" BO_ 2151063552 4;
BA_ "GenMsgDelayTime" BO_ 2151063552 100;
BA_ "GenMsgCycleTime" BO_ 1574 3000;
BA_ "GenMsgSendType" BO_ 1574 0;
BA_ "NmMessage" BO_ 1574 1;
BA_ "GenMsgCycleTime" BO_ 1571 3000;
BA_ "GenMsgSendType" BO_ 1571 0;
BA_ "NmMessage" BO_ 1571 1;
BA_ "Prio" BO_ 2155167744 4;
BA_ "GenMsgDelayTime" BO_ 2155167744 100;
BA_ "GenMsgCycleTime" BO_ 1568 3000;
BA_ "GenMsgSendType" BO_ 1568 0;
BA_ "NmMessage" BO_ 1568 1;
BA_ "GenMsgCycleTime" BO_ 1570 3000;
BA_ "GenMsgSendType" BO_ 1570 0;
BA_ "NmMessage" BO_ 1570 1;
BA_ "GenMsgCycleTime" BO_ 1579 3000;
BA_ "GenMsgSendType" BO_ 1579 0;
BA_ "NmMessage" BO_ 1579 1;
BA_ "GenMsgCycleTime" BO_ 1599 3000;
BA_ "GenMsgSendType" BO_ 1599 0;
BA_ "NmMessage" BO_ 1599 1;
BA_ "GenMsgCycleTime" BO_ 1585 3000;
BA_ "GenMsgSendType" BO_ 1585 0;
BA_ "NmMessage" BO_ 1585 1;
BA_ "GenMsgCycleTime" BO_ 1572 3000;
BA_ "GenMsgSendType" BO_ 1572 0;
BA_ "NmMessage" BO_ 1572 1;
BA_ "GenMsgCycleTime" BO_ 1597 3000;
BA_ "GenMsgSendType" BO_ 1597 0;
BA_ "NmMessage" BO_ 1597 1;
BA_ "GenMsgCycleTime" BO_ 1576 3000;
BA_ "GenMsgSendType" BO_ 1576 0;
BA_ "NmMessage" BO_ 1576 1;
BA_ "GenMsgCycleTime" BO_ 1593 3000;
BA_ "GenMsgSendType" BO_ 1593 0;
BA_ "NmMessage" BO_ 1593 1;
BA_ "GenMsgCycleTime" BO_ 1589 3000;
BA_ "GenMsgSendType" BO_ 1589 0;
BA_ "NmMessage" BO_ 1589 1;
BA_ "GenMsgILSupport" BO_ 257 0;
BA_ "DiagState" BO_ 257 1;
BA_ "DiagRequest" BO_ 257 1;
BA_ "GenMsgCycleTime" BO_ 1587 3000;
BA_ "GenMsgSendType" BO_ 1587 0;
BA_ "NmMessage" BO_ 1587 1;
BA_ "GenMsgCycleTime" BO_ 1575 3000;
BA_ "GenMsgSendType" BO_ 1575 0;
BA_ "NmMessage" BO_ 1575 1;
BA_ "GenMsgCycleTime" BO_ 1581 3000;
BA_ "GenMsgSendType" BO_ 1581 0;
BA_ "NmMessage" BO_ 1581 1;
BA_ "GenMsgCycleTime" BO_ 1580 3000;
BA_ "GenMsgSendType" BO_ 1580 0;
BA_ "NmMessage" BO_ 1580 1;
BA_ "GenMsgCycleTime" BO_ 1584 3000;
BA_ "GenMsgSendType" BO_ 1584 0;
BA_ "NmMessage" BO_ 1584 1;
BA_ "GenMsgCycleTime" BO_ 1569 1000;
BA_ "GenMsgSendType" BO_ 1569 0;
BA_ "NmMessage" BO_ 1569 1;
BA_ "GenMsgCycleTime" BO_ 1573 3000;
BA_ "GenMsgSendType" BO_ 1573 0;
BA_ "NmMessage" BO_ 1573 1;
BA_ "Prio" BO_ 2151677952 4;
BA_ "GenMsgDelayTime" BO_ 2151677952 100;
BA_ "Prio" BO_ 2149859328 4;
BA_ "GenMsgDelayTime" BO_ 2149859328 100;
BA_ "GenMsgCycleTime" BO_ 2149859328 5000;
BA_ "GenMsgSendType" BO_ 2149859328 0;
BA_ "Prio" BO_ 2150604800 3;
BA_ "GenMsgDelayTime" BO_ 2150604800 100;
BA_ "Prio" BO_ 2150588416 3;
BA_ "GenMsgDelayTime" BO_ 2150588416 100;
BA_ "Prio" BO_ 2150596608 3;
BA_ "GenMsgDelayTime" BO_ 2150596608 100;
BA_ "Prio" BO_ 2150416384 4;
BA_ "GenMsgStartDelayTime" BO_ 2150416384 140;
BA_ "GenMsgCycleTime" BO_ 2150416384 250;
BA_ "GenMsgSendType" BO_ 2150416384 0;
BA_ "Prio" BO_ 2150408192 4;
BA_ "GenMsgStartDelayTime" BO_ 2150408192 180;
BA_ "GenMsgCycleTime" BO_ 2150408192 100;
BA_ "GenMsgSendType" BO_ 2150408192 0;
BA_ "Prio" BO_ 2153971712 3;
BA_ "GenMsgDelayTime" BO_ 2153971712 100;
BA_ "Prio" BO_ 2151792640 4;
BA_ "GenMsgDelayTime" BO_ 2151792640 100;
BA_ "Prio" BO_ 2151776256 4;
BA_ "GenMsgDelayTime" BO_ 2151776256 100;
BA_ "Prio" BO_ 2149646336 4;
BA_ "GenMsgStartDelayTime" BO_ 2149646336 110;
BA_ "GenMsgCycleTime" BO_ 2149646336 100;
BA_ "GenMsgSendType" BO_ 2149646336 0;
BA_ "Prio" BO_ 2149851136 4;
BA_ "GenMsgStartDelayTime" BO_ 2149851136 120;
BA_ "GenMsgDelayTime" BO_ 2149851136 30;
BA_ "GenMsgCycleTime" BO_ 2149851136 5000;
BA_ "GenMsgSendType" BO_ 2149851136 0;
BA_ "Prio" BO_ 2151718912 4;
BA_ "GenMsgDelayTime" BO_ 2151718912 10;
BA_ "Prio" BO_ 2153775104 4;
BA_ "GenMsgDelayTime" BO_ 2153775104 1000;
BA_ "GenMsgILSupport" BO_ 1364 0;
BA_ "TpApplType" BO_ 1364 "DiagUUDTResponse";
BA_ "GenMsgCycleTime" BO_ 1588 3000;
BA_ "GenMsgSendType" BO_ 1588 0;
BA_ "NmMessage" BO_ 1588 1;
BA_ "GenMsgCycleTime" BO_ 1594 3000;
BA_ "GenMsgSendType" BO_ 1594 0;
BA_ "NmMessage" BO_ 1594 1;
BA_ "GenMsgILSupport" BO_ 1370 0;
BA_ "TpApplType" BO_ 1370 "DiagUUDTResponse";
BA_ "DiagResponse" BO_ 872 1;
BA_ "DiagResponse" BO_ 1626 1;
BA_ "GenMsgCycleTime" BO_ 1583 3000;
BA_ "GenMsgSendType" BO_ 1583 0;
BA_ "NmMessage" BO_ 1583 1;
BA_ "DiagResponse" BO_ 1615 1;
BA_ "GenMsgILSupport" BO_ 1359 0;
BA_ "TpApplType" BO_ 1359 "DiagUUDTResponse";
BA_ "GenSigSendType" SG_ 2158755840 ODIE_MultiFrRetCh 12;
BA_ "GenSigDeltaValue" SG_ 2158755840 ODIE_MultiFrRetCh 1;
BA_ "VNSigAllNodes" SG_ 2158755840 ODIE_MultiFrRetCh 1;
BA_ "SignalType" SG_ 2158755840 ODIE_MultiFrRetCh "UNM";
BA_ "PacketOrder" SG_ 2158755840 ODIE_MultiFrRetCh 3;
BA_ "SignalLongName" SG_ 2158755840 ODIE_MultiFrRetCh "Open Display Interface Event Packet : MultiFrameReturnChannel";
BA_ "GenSigSendType" SG_ 2158755840 ODIE_FUCID 12;
BA_ "GenSigDeltaValue" SG_ 2158755840 ODIE_FUCID 1;
BA_ "VNSigAllNodes" SG_ 2158755840 ODIE_FUCID 1;
BA_ "SignalType" SG_ 2158755840 ODIE_FUCID "UNM";
BA_ "PacketOrder" SG_ 2158755840 ODIE_FUCID 2;
BA_ "SignalLongName" SG_ 2158755840 ODIE_FUCID "Open Display Interface Event Packet : Functional Unit Class ID";
BA_ "GenSigSendType" SG_ 2158755840 ODIE_EvID 12;
BA_ "GenSigDeltaValue" SG_ 2158755840 ODIE_EvID 1;
BA_ "VNSigAllNodes" SG_ 2158755840 ODIE_EvID 1;
BA_ "SignalType" SG_ 2158755840 ODIE_EvID "UNM";
BA_ "PacketOrder" SG_ 2158755840 ODIE_EvID 1;
BA_ "SignalLongName" SG_ 2158755840 ODIE_EvID "Open Display Interface Event Packet : Event ID";
BA_ "GenSigSendOnInit" SG_ 2151284736 PrkAstOprtrDsrdStat_1D0 2;
BA_ "GenSigSendType" SG_ 2151284736 PrkAstOprtrDsrdStat_1D0 10;
BA_ "VNSigAllNodes" SG_ 2151284736 PrkAstOprtrDsrdStat_1D0 1;
BA_ "SignalType" SG_ 2151284736 PrkAstOprtrDsrdStat_1D0 "ENM";
BA_ "SignalLongName" SG_ 2151284736 PrkAstOprtrDsrdStat_1D0 "Park Assistance Operator Desired Status";
BA_ "GenSigSendType" SG_ 2151284736 TnDrvPrkAstOffUnbIO 10;
BA_ "VNSigAllNodes" SG_ 2151284736 TnDrvPrkAstOffUnbIO 1;
BA_ "SignalType" SG_ 2151284736 TnDrvPrkAstOffUnbIO "BLN";
BA_ "SignalLongName" SG_ 2151284736 TnDrvPrkAstOffUnbIO "Teen Driver Park Assist Off Unavailable Indication On";
BA_ "GenSigSendType" SG_ 2151284736 PrkAstFld 10;
BA_ "VNSigAllNodes" SG_ 2151284736 PrkAstFld 1;
BA_ "SignalType" SG_ 2151284736 PrkAstFld "BLN";
BA_ "SignalLongName" SG_ 2151284736 PrkAstFld "Parking Assistance Failed";
BA_ "GenSigSendType" SG_ 2151284736 PrkAstSnsDistrbdIO 10;
BA_ "VNSigAllNodes" SG_ 2151284736 PrkAstSnsDistrbdIO 1;
BA_ "SignalType" SG_ 2151284736 PrkAstSnsDistrbdIO "BLN";
BA_ "SignalLongName" SG_ 2151284736 PrkAstSnsDistrbdIO "Parking Assistance Sensors Disturbed Indication On";
BA_ "GenSigSendOnInit" SG_ 2151284736 PrkAsstDisablIO 2;
BA_ "GenSigSendType" SG_ 2151284736 PrkAsstDisablIO 10;
BA_ "VNSigAllNodes" SG_ 2151284736 PrkAsstDisablIO 1;
BA_ "SignalType" SG_ 2151284736 PrkAsstDisablIO "BLN";
BA_ "SignalLongName" SG_ 2151284736 PrkAsstDisablIO "Parking Assistance Disabled Indication On";
BA_ "GenSigSendType" SG_ 2151284736 PrkAstSnrsBlk 10;
BA_ "VNSigAllNodes" SG_ 2151284736 PrkAstSnrsBlk 1;
BA_ "SignalType" SG_ 2151284736 PrkAstSnrsBlk "BLN";
BA_ "SignalLongName" SG_ 2151284736 PrkAstSnrsBlk "Parking Assistance Sensors Blocked";
BA_ "GenSigSendType" SG_ 2151284736 PrkAsstClnPrkAstIO 10;
BA_ "VNSigAllNodes" SG_ 2151284736 PrkAsstClnPrkAstIO 1;
BA_ "SignalType" SG_ 2151284736 PrkAsstClnPrkAstIO "BLN";
BA_ "SignalLongName" SG_ 2151284736 PrkAsstClnPrkAstIO "Parking Assistance Clean Parking Assist Indication On";
BA_ "GenSigSendType" SG_ 2159026176 ODD_InvldData 10;
BA_ "VNSigAllNodes" SG_ 2159026176 ODD_InvldData 1;
BA_ "SignalType" SG_ 2159026176 ODD_InvldData "BLN";
BA_ "PacketOrder" SG_ 2159026176 ODD_InvldData 2;
BA_ "SignalLongName" SG_ 2159026176 ODD_InvldData "Open Display Interface Dynamic Data : Invalid Data";
BA_ "GenSigSendType" SG_ 2159026176 ODD_FUCID 12;
BA_ "GenSigDeltaValue" SG_ 2159026176 ODD_FUCID 1;
BA_ "VNSigAllNodes" SG_ 2159026176 ODD_FUCID 1;
BA_ "SignalType" SG_ 2159026176 ODD_FUCID "UNM";
BA_ "PacketOrder" SG_ 2159026176 ODD_FUCID 3;
BA_ "SignalLongName" SG_ 2159026176 ODD_FUCID "Open Display Interface Dynamic Data : Functional Unit Class ID";
BA_ "GenSigSendType" SG_ 2159026176 ODD_DataVal 12;
BA_ "GenSigDeltaValue" SG_ 2159026176 ODD_DataVal 1;
BA_ "VNSigAllNodes" SG_ 2159026176 ODD_DataVal 1;
BA_ "SignalType" SG_ 2159026176 ODD_DataVal "UNM";
BA_ "PacketOrder" SG_ 2159026176 ODD_DataVal 5;
BA_ "SignalLongName" SG_ 2159026176 ODD_DataVal "Open Display Interface Dynamic Data : Data Value";
BA_ "GenSigSendType" SG_ 2159026176 ODD_DataType 10;
BA_ "GenSigDeltaValue" SG_ 2159026176 ODD_DataType 1;
BA_ "VNSigAllNodes" SG_ 2159026176 ODD_DataType 1;
BA_ "SignalType" SG_ 2159026176 ODD_DataType "ENM";
BA_ "PacketOrder" SG_ 2159026176 ODD_DataType 1;
BA_ "SignalLongName" SG_ 2159026176 ODD_DataType "Open Display Interface Dynamic Data : Data Type";
BA_ "GenSigSendType" SG_ 2159026176 ODD_DataId 12;
BA_ "GenSigDeltaValue" SG_ 2159026176 ODD_DataId 1;
BA_ "VNSigAllNodes" SG_ 2159026176 ODD_DataId 1;
BA_ "SignalType" SG_ 2159026176 ODD_DataId "UNM";
BA_ "PacketOrder" SG_ 2159026176 ODD_DataId 4;
BA_ "SignalLongName" SG_ 2159026176 ODD_DataId "Open Display Interface Dynamic Data : Data ID";
BA_ "GenSigSendOnInit" SG_ 2158936064 ODIEDD_Data18Value 1;
BA_ "GenSigSendType" SG_ 2158936064 ODIEDD_Data18Value 12;
BA_ "GenSigDeltaValue" SG_ 2158936064 ODIEDD_Data18Value 1;
BA_ "VNSigAllNodes" SG_ 2158936064 ODIEDD_Data18Value 1;
BA_ "SignalType" SG_ 2158936064 ODIEDD_Data18Value "UNM";
BA_ "PacketOrder" SG_ 2158936064 ODIEDD_Data18Value 18;
BA_ "SignalLongName" SG_ 2158936064 ODIEDD_Data18Value "Open Display Interface Enum Dynamic Data : Data ID 18";
BA_ "GenSigSendOnInit" SG_ 2158936064 ODIEDD_Data17Value 1;
BA_ "GenSigSendType" SG_ 2158936064 ODIEDD_Data17Value 12;
BA_ "GenSigDeltaValue" SG_ 2158936064 ODIEDD_Data17Value 1;
BA_ "VNSigAllNodes" SG_ 2158936064 ODIEDD_Data17Value 1;
BA_ "SignalType" SG_ 2158936064 ODIEDD_Data17Value "UNM";
BA_ "PacketOrder" SG_ 2158936064 ODIEDD_Data17Value 17;
BA_ "SignalLongName" SG_ 2158936064 ODIEDD_Data17Value "Open Display Interface Enum Dynamic Data : Data ID 17";
BA_ "GenSigSendOnInit" SG_ 2158936064 ODIEDD_Data16Value 1;
BA_ "GenSigSendType" SG_ 2158936064 ODIEDD_Data16Value 12;
BA_ "GenSigDeltaValue" SG_ 2158936064 ODIEDD_Data16Value 1;
BA_ "VNSigAllNodes" SG_ 2158936064 ODIEDD_Data16Value 1;
BA_ "SignalType" SG_ 2158936064 ODIEDD_Data16Value "UNM";
BA_ "PacketOrder" SG_ 2158936064 ODIEDD_Data16Value 16;
BA_ "SignalLongName" SG_ 2158936064 ODIEDD_Data16Value "Open Display Interface Enum Dynamic Data : Data ID 16";
BA_ "GenSigSendOnInit" SG_ 2158936064 ODIEDD_Data15Value 1;
BA_ "GenSigSendType" SG_ 2158936064 ODIEDD_Data15Value 12;
BA_ "GenSigDeltaValue" SG_ 2158936064 ODIEDD_Data15Value 1;
BA_ "VNSigAllNodes" SG_ 2158936064 ODIEDD_Data15Value 1;
BA_ "SignalType" SG_ 2158936064 ODIEDD_Data15Value "UNM";
BA_ "PacketOrder" SG_ 2158936064 ODIEDD_Data15Value 15;
BA_ "SignalLongName" SG_ 2158936064 ODIEDD_Data15Value "Open Display Interface Enum Dynamic Data : Data ID 15";
BA_ "GenSigSendOnInit" SG_ 2158936064 ODIEDD_Data14Value 1;
BA_ "GenSigSendType" SG_ 2158936064 ODIEDD_Data14Value 12;
BA_ "GenSigDeltaValue" SG_ 2158936064 ODIEDD_Data14Value 1;
BA_ "VNSigAllNodes" SG_ 2158936064 ODIEDD_Data14Value 1;
BA_ "SignalType" SG_ 2158936064 ODIEDD_Data14Value "UNM";
BA_ "PacketOrder" SG_ 2158936064 ODIEDD_Data14Value 14;
BA_ "SignalLongName" SG_ 2158936064 ODIEDD_Data14Value "Open Display Interface Enum Dynamic Data : Data ID 14";
BA_ "GenSigSendOnInit" SG_ 2158936064 ODIEDD_Data13Value 1;
BA_ "GenSigSendType" SG_ 2158936064 ODIEDD_Data13Value 12;
BA_ "GenSigDeltaValue" SG_ 2158936064 ODIEDD_Data13Value 1;
BA_ "VNSigAllNodes" SG_ 2158936064 ODIEDD_Data13Value 1;
BA_ "SignalType" SG_ 2158936064 ODIEDD_Data13Value "UNM";
BA_ "PacketOrder" SG_ 2158936064 ODIEDD_Data13Value 13;
BA_ "SignalLongName" SG_ 2158936064 ODIEDD_Data13Value "Open Display Interface Enum Dynamic Data : Data ID 13";
BA_ "GenSigSendOnInit" SG_ 2158936064 ODIEDD_Data12Value 1;
BA_ "GenSigSendType" SG_ 2158936064 ODIEDD_Data12Value 12;
BA_ "GenSigDeltaValue" SG_ 2158936064 ODIEDD_Data12Value 1;
BA_ "VNSigAllNodes" SG_ 2158936064 ODIEDD_Data12Value 1;
BA_ "SignalType" SG_ 2158936064 ODIEDD_Data12Value "UNM";
BA_ "PacketOrder" SG_ 2158936064 ODIEDD_Data12Value 12;
BA_ "SignalLongName" SG_ 2158936064 ODIEDD_Data12Value "Open Display Interface Enum Dynamic Data : Data ID 12";
BA_ "GenSigSendOnInit" SG_ 2158936064 ODIEDD_Data11Value 1;
BA_ "GenSigSendType" SG_ 2158936064 ODIEDD_Data11Value 12;
BA_ "GenSigDeltaValue" SG_ 2158936064 ODIEDD_Data11Value 1;
BA_ "VNSigAllNodes" SG_ 2158936064 ODIEDD_Data11Value 1;
BA_ "SignalType" SG_ 2158936064 ODIEDD_Data11Value "UNM";
BA_ "PacketOrder" SG_ 2158936064 ODIEDD_Data11Value 11;
BA_ "SignalLongName" SG_ 2158936064 ODIEDD_Data11Value "Open Display Interface Enum Dynamic Data : Data ID 11";
BA_ "GenSigSendOnInit" SG_ 2158936064 ODIEDD_Data10Value 1;
BA_ "GenSigSendType" SG_ 2158936064 ODIEDD_Data10Value 12;
BA_ "GenSigDeltaValue" SG_ 2158936064 ODIEDD_Data10Value 1;
BA_ "VNSigAllNodes" SG_ 2158936064 ODIEDD_Data10Value 1;
BA_ "SignalType" SG_ 2158936064 ODIEDD_Data10Value "UNM";
BA_ "PacketOrder" SG_ 2158936064 ODIEDD_Data10Value 10;
BA_ "SignalLongName" SG_ 2158936064 ODIEDD_Data10Value "Open Display Interface Enum Dynamic Data : Data ID 10";
BA_ "GenSigSendOnInit" SG_ 2158936064 ODIEDD_Data9Value 1;
BA_ "GenSigSendType" SG_ 2158936064 ODIEDD_Data9Value 12;
BA_ "GenSigDeltaValue" SG_ 2158936064 ODIEDD_Data9Value 1;
BA_ "VNSigAllNodes" SG_ 2158936064 ODIEDD_Data9Value 1;
BA_ "SignalType" SG_ 2158936064 ODIEDD_Data9Value "UNM";
BA_ "PacketOrder" SG_ 2158936064 ODIEDD_Data9Value 9;
BA_ "SignalLongName" SG_ 2158936064 ODIEDD_Data9Value "Open Display Interface Enum Dynamic Data : Data ID 9";
BA_ "GenSigSendOnInit" SG_ 2158936064 ODIEDD_Data8Value 1;
BA_ "GenSigSendType" SG_ 2158936064 ODIEDD_Data8Value 12;
BA_ "GenSigDeltaValue" SG_ 2158936064 ODIEDD_Data8Value 1;
BA_ "VNSigAllNodes" SG_ 2158936064 ODIEDD_Data8Value 1;
BA_ "SignalType" SG_ 2158936064 ODIEDD_Data8Value "UNM";
BA_ "PacketOrder" SG_ 2158936064 ODIEDD_Data8Value 8;
BA_ "SignalLongName" SG_ 2158936064 ODIEDD_Data8Value "Open Display Interface Enum Dynamic Data : Data ID 8";
BA_ "GenSigSendOnInit" SG_ 2158936064 ODIEDD_Data7Value 1;
BA_ "GenSigSendType" SG_ 2158936064 ODIEDD_Data7Value 12;
BA_ "GenSigDeltaValue" SG_ 2158936064 ODIEDD_Data7Value 1;
BA_ "VNSigAllNodes" SG_ 2158936064 ODIEDD_Data7Value 1;
BA_ "SignalType" SG_ 2158936064 ODIEDD_Data7Value "UNM";
BA_ "PacketOrder" SG_ 2158936064 ODIEDD_Data7Value 7;
BA_ "SignalLongName" SG_ 2158936064 ODIEDD_Data7Value "Open Display Interface Enum Dynamic Data : Data ID 7";
BA_ "GenSigSendOnInit" SG_ 2158936064 ODIEDD_Data6Value 1;
BA_ "GenSigSendType" SG_ 2158936064 ODIEDD_Data6Value 12;
BA_ "GenSigDeltaValue" SG_ 2158936064 ODIEDD_Data6Value 1;
BA_ "VNSigAllNodes" SG_ 2158936064 ODIEDD_Data6Value 1;
BA_ "SignalType" SG_ 2158936064 ODIEDD_Data6Value "UNM";
BA_ "PacketOrder" SG_ 2158936064 ODIEDD_Data6Value 6;
BA_ "SignalLongName" SG_ 2158936064 ODIEDD_Data6Value "Open Display Interface Enum Dynamic Data : Data ID 6";
BA_ "GenSigSendOnInit" SG_ 2158936064 ODIEDD_Data5Value 1;
BA_ "GenSigSendType" SG_ 2158936064 ODIEDD_Data5Value 12;
BA_ "GenSigDeltaValue" SG_ 2158936064 ODIEDD_Data5Value 1;
BA_ "VNSigAllNodes" SG_ 2158936064 ODIEDD_Data5Value 1;
BA_ "SignalType" SG_ 2158936064 ODIEDD_Data5Value "UNM";
BA_ "PacketOrder" SG_ 2158936064 ODIEDD_Data5Value 5;
BA_ "SignalLongName" SG_ 2158936064 ODIEDD_Data5Value "Open Display Interface Enum Dynamic Data : Data ID 5";
BA_ "GenSigSendOnInit" SG_ 2158936064 ODIEDD_Data4Value 1;
BA_ "GenSigSendType" SG_ 2158936064 ODIEDD_Data4Value 12;
BA_ "GenSigDeltaValue" SG_ 2158936064 ODIEDD_Data4Value 1;
BA_ "VNSigAllNodes" SG_ 2158936064 ODIEDD_Data4Value 1;
BA_ "SignalType" SG_ 2158936064 ODIEDD_Data4Value "UNM";
BA_ "PacketOrder" SG_ 2158936064 ODIEDD_Data4Value 4;
BA_ "SignalLongName" SG_ 2158936064 ODIEDD_Data4Value "Open Display Interface Enum Dynamic Data : Data ID 4";
BA_ "GenSigSendOnInit" SG_ 2158936064 ODIEDD_Data3Value 1;
BA_ "GenSigSendType" SG_ 2158936064 ODIEDD_Data3Value 12;
BA_ "GenSigDeltaValue" SG_ 2158936064 ODIEDD_Data3Value 1;
BA_ "VNSigAllNodes" SG_ 2158936064 ODIEDD_Data3Value 1;
BA_ "SignalType" SG_ 2158936064 ODIEDD_Data3Value "UNM";
BA_ "PacketOrder" SG_ 2158936064 ODIEDD_Data3Value 3;
BA_ "SignalLongName" SG_ 2158936064 ODIEDD_Data3Value "Open Display Interface Enum Dynamic Data : Data ID 3";
BA_ "GenSigSendOnInit" SG_ 2158936064 ODIEDD_Data2Value 1;
BA_ "GenSigSendType" SG_ 2158936064 ODIEDD_Data2Value 12;
BA_ "GenSigDeltaValue" SG_ 2158936064 ODIEDD_Data2Value 1;
BA_ "VNSigAllNodes" SG_ 2158936064 ODIEDD_Data2Value 1;
BA_ "SignalType" SG_ 2158936064 ODIEDD_Data2Value "UNM";
BA_ "PacketOrder" SG_ 2158936064 ODIEDD_Data2Value 2;
BA_ "SignalLongName" SG_ 2158936064 ODIEDD_Data2Value "Open Display Interface Enum Dynamic Data : Data ID 2";
BA_ "GenSigSendOnInit" SG_ 2158936064 ODIEDD_Data1Value 1;
BA_ "GenSigSendType" SG_ 2158936064 ODIEDD_Data1Value 12;
BA_ "GenSigDeltaValue" SG_ 2158936064 ODIEDD_Data1Value 1;
BA_ "VNSigAllNodes" SG_ 2158936064 ODIEDD_Data1Value 1;
BA_ "SignalType" SG_ 2158936064 ODIEDD_Data1Value "UNM";
BA_ "PacketOrder" SG_ 2158936064 ODIEDD_Data1Value 1;
BA_ "SignalLongName" SG_ 2158936064 ODIEDD_Data1Value "Open Display Interface Enum Dynamic Data : Data ID 1";
BA_ "GenSigSendOnInit" SG_ 2158936064 ODIEDD_FUCID 1;
BA_ "GenSigSendType" SG_ 2158936064 ODIEDD_FUCID 12;
BA_ "GenSigDeltaValue" SG_ 2158936064 ODIEDD_FUCID 1;
BA_ "VNSigAllNodes" SG_ 2158936064 ODIEDD_FUCID 1;
BA_ "SignalType" SG_ 2158936064 ODIEDD_FUCID "UNM";
BA_ "PacketOrder" SG_ 2158936064 ODIEDD_FUCID 19;
BA_ "SignalLongName" SG_ 2158936064 ODIEDD_FUCID "Open Display Interface Enum Dynamic Data : Functional Unit Class ID";
BA_ "GenSigSendType" SG_ 2151317504 PrkAstRrSysStat 10;
BA_ "VNSigAllNodes" SG_ 2151317504 PrkAstRrSysStat 1;
BA_ "SignalType" SG_ 2151317504 PrkAstRrSysStat "ENM";
BA_ "SignalLongName" SG_ 2151317504 PrkAstRrSysStat "Parking Assistance Rear System Status";
BA_ "GenSigSendType" SG_ 2151317504 PARrRgn4ObjStat 10;
BA_ "VNSigAllNodes" SG_ 2151317504 PARrRgn4ObjStat 1;
BA_ "SignalType" SG_ 2151317504 PARrRgn4ObjStat "ENM";
BA_ "SignalLongName" SG_ 2151317504 PARrRgn4ObjStat "Parking Assistance Rear Region 4 Object Status";
BA_ "GenSigSendType" SG_ 2151317504 PARrRgn3ObjStat 10;
BA_ "VNSigAllNodes" SG_ 2151317504 PARrRgn3ObjStat 1;
BA_ "SignalType" SG_ 2151317504 PARrRgn3ObjStat "ENM";
BA_ "SignalLongName" SG_ 2151317504 PARrRgn3ObjStat "Parking Assistance Rear Region 3 Object Status";
BA_ "GenSigSendType" SG_ 2151317504 PARrRgn2ObjStat 10;
BA_ "VNSigAllNodes" SG_ 2151317504 PARrRgn2ObjStat 1;
BA_ "SignalType" SG_ 2151317504 PARrRgn2ObjStat "ENM";
BA_ "SignalLongName" SG_ 2151317504 PARrRgn2ObjStat "Parking Assistance Rear Region 2 Object Status";
BA_ "GenSigSendType" SG_ 2151317504 PARrRgn1ObjStat 10;
BA_ "VNSigAllNodes" SG_ 2151317504 PARrRgn1ObjStat 1;
BA_ "SignalType" SG_ 2151317504 PARrRgn1ObjStat "ENM";
BA_ "SignalLongName" SG_ 2151317504 PARrRgn1ObjStat "Parking Assistance Rear Region 1 Object Status";
BA_ "GenSigSendType" SG_ 2151317504 PrkAsstRrExtdDist 12;
BA_ "GenSigDeltaValue" SG_ 2151317504 PrkAsstRrExtdDist 1;
BA_ "VNSigAllNodes" SG_ 2151317504 PrkAsstRrExtdDist 1;
BA_ "SignalType" SG_ 2151317504 PrkAsstRrExtdDist "UNM";
BA_ "SignalLongName" SG_ 2151317504 PrkAsstRrExtdDist "Parking Assistance Rear Extended Distance";
BA_ "GenSigSendType" SG_ 2151301120 PrkAsstRrOffIO 10;
BA_ "VNSigAllNodes" SG_ 2151301120 PrkAsstRrOffIO 1;
BA_ "SignalType" SG_ 2151301120 PrkAsstRrOffIO "BLN";
BA_ "SignalLongName" SG_ 2151301120 PrkAsstRrOffIO "Parking Assistance Rear Off Indication On";
BA_ "GenSigSendType" SG_ 2151301120 PrkAstAdvSysAct 10;
BA_ "VNSigAllNodes" SG_ 2151301120 PrkAstAdvSysAct 1;
BA_ "SignalType" SG_ 2151301120 PrkAstAdvSysAct "BLN";
BA_ "SignalLongName" SG_ 2151301120 PrkAstAdvSysAct "Parking Assistance Advanced  System Active";
BA_ "GenSigSendOnInit" SG_ 2151301120 PrkAstFrSysStat 2;
BA_ "GenSigSendType" SG_ 2151301120 PrkAstFrSysStat 10;
BA_ "VNSigAllNodes" SG_ 2151301120 PrkAstFrSysStat 1;
BA_ "SignalType" SG_ 2151301120 PrkAstFrSysStat "ENM";
BA_ "SignalLongName" SG_ 2151301120 PrkAstFrSysStat "Parking Assistance Front System Status";
BA_ "GenSigSendType" SG_ 2151301120 PAFrtRgn4ObjStat 10;
BA_ "VNSigAllNodes" SG_ 2151301120 PAFrtRgn4ObjStat 1;
BA_ "SignalType" SG_ 2151301120 PAFrtRgn4ObjStat "ENM";
BA_ "SignalLongName" SG_ 2151301120 PAFrtRgn4ObjStat "Parking Assistance Front Region 4 Object Status";
BA_ "GenSigSendType" SG_ 2151301120 PAFrtRgn3ObjStat 10;
BA_ "VNSigAllNodes" SG_ 2151301120 PAFrtRgn3ObjStat 1;
BA_ "SignalType" SG_ 2151301120 PAFrtRgn3ObjStat "ENM";
BA_ "SignalLongName" SG_ 2151301120 PAFrtRgn3ObjStat "Parking Assistance Front Region 3 Object Status";
BA_ "GenSigSendType" SG_ 2151301120 PAFrtRgn2ObjStat 10;
BA_ "VNSigAllNodes" SG_ 2151301120 PAFrtRgn2ObjStat 1;
BA_ "SignalType" SG_ 2151301120 PAFrtRgn2ObjStat "ENM";
BA_ "SignalLongName" SG_ 2151301120 PAFrtRgn2ObjStat "Parking Assistance Front Region 2 Object Status";
BA_ "GenSigSendType" SG_ 2151301120 PAFrtRgn1ObjStat 10;
BA_ "VNSigAllNodes" SG_ 2151301120 PAFrtRgn1ObjStat 1;
BA_ "SignalType" SG_ 2151301120 PAFrtRgn1ObjStat "ENM";
BA_ "SignalLongName" SG_ 2151301120 PAFrtRgn1ObjStat "Parking Assistance Front Region 1 Object Status";
BA_ "GenSigSendType" SG_ 2151301120 PrkAsstFrtExtdDist 12;
BA_ "GenSigDeltaValue" SG_ 2151301120 PrkAsstFrtExtdDist 1;
BA_ "VNSigAllNodes" SG_ 2151301120 PrkAsstFrtExtdDist 1;
BA_ "SignalType" SG_ 2151301120 PrkAsstFrtExtdDist "UNM";
BA_ "SignalLongName" SG_ 2151301120 PrkAsstFrtExtdDist "Parking Assistance Front Extended Distance";
BA_ "GenSigSendType" SG_ 2155003904 LfLnChngThrtAprchSpd 12;
BA_ "GenSigDeltaValue" SG_ 2155003904 LfLnChngThrtAprchSpd 1;
BA_ "VNSigAllNodes" SG_ 2155003904 LfLnChngThrtAprchSpd 1;
BA_ "SignalType" SG_ 2155003904 LfLnChngThrtAprchSpd "SNM";
BA_ "SignalLongName" SG_ 2155003904 LfLnChngThrtAprchSpd "Left Lane Change Threat Approach Speed";
BA_ "GenSigSendOnInit" SG_ 2155003904 LftLnChgThrt 2;
BA_ "GenSigSendType" SG_ 2155003904 LftLnChgThrt 10;
BA_ "VNSigAllNodes" SG_ 2155003904 LftLnChgThrt 1;
BA_ "SignalType" SG_ 2155003904 LftLnChgThrt "BLN";
BA_ "SignalLongName" SG_ 2155003904 LftLnChgThrt "Left Lane Change Threat";
BA_ "GenSigSendType" SG_ 2155003904 SBZATmpUnvIndOn 10;
BA_ "VNSigAllNodes" SG_ 2155003904 SBZATmpUnvIndOn 1;
BA_ "SignalType" SG_ 2155003904 SBZATmpUnvIndOn "BLN";
BA_ "SignalLongName" SG_ 2155003904 SBZATmpUnvIndOn "Side Blind Zone Alert Temporarily Unavailable Indication On";
BA_ "GenSigSendOnInit" SG_ 2155003904 SBZASysSrvIndOn 2;
BA_ "GenSigSendType" SG_ 2155003904 SBZASysSrvIndOn 10;
BA_ "VNSigAllNodes" SG_ 2155003904 SBZASysSrvIndOn 1;
BA_ "SignalType" SG_ 2155003904 SBZASysSrvIndOn "BLN";
BA_ "SignalLongName" SG_ 2155003904 SBZASysSrvIndOn "Side Blind Zone Alert System Service Indication On";
BA_ "GenSigSendType" SG_ 2155003904 SBZASysOffIndOn 10;
BA_ "VNSigAllNodes" SG_ 2155003904 SBZASysOffIndOn 1;
BA_ "SignalType" SG_ 2155003904 SBZASysOffIndOn "BLN";
BA_ "SignalLongName" SG_ 2155003904 SBZASysOffIndOn "Side Blind Zone Alert System Off Indication On";
BA_ "GenSigSendType" SG_ 2155003904 SBZASysClnIndOn 10;
BA_ "VNSigAllNodes" SG_ 2155003904 SBZASysClnIndOn 1;
BA_ "SignalType" SG_ 2155003904 SBZASysClnIndOn "BLN";
BA_ "SignalLongName" SG_ 2155003904 SBZASysClnIndOn "Side Blind Zone Alert System Clean Indication On";
BA_ "VNSigDiagnostic" SG_ 1369 DgnInf_LS559 1;
BA_ "VNSigAllNodes" SG_ 1369 DgnInf_LS559 1;
BA_ "SignalType" SG_ 1369 DgnInf_LS559 "UNM";
BA_ "SignalLongName" SG_ 1369 DgnInf_LS559 "Diagnostic Information LS559";
BA_ "VNSigDiagnostic" SG_ 1625 DgnInf 1;
BA_ "GenSigSendType" SG_ 1625 DgnInf 12;
BA_ "GenSigDeltaValue" SG_ 1625 DgnInf 1;
BA_ "VNSigAllNodes" SG_ 1625 DgnInf 1;
BA_ "SignalType" SG_ 1625 DgnInf "UNM";
BA_ "SignalLongName" SG_ 1625 DgnInf "Diagnostic Information";
BA_ "GenSigSendType" SG_ 2150850560 DrSbltAtcV 10;
BA_ "VNSigAllNodes" SG_ 2150850560 DrSbltAtcV 1;
BA_ "SignalType" SG_ 2150850560 DrSbltAtcV "ENM";
BA_ "SignalLongName" SG_ 2150850560 DrSbltAtcV "Driver Seatbelt Attached Validity";
BA_ "GenSigSendType" SG_ 2150850560 DrSbltAtc 10;
BA_ "VNSigAllNodes" SG_ 2150850560 DrSbltAtc 1;
BA_ "SignalType" SG_ 2150850560 DrSbltAtc "BLN";
BA_ "SignalLongName" SG_ 2150850560 DrSbltAtc "Driver Seatbelt Attached";
BA_ "GenSigSendOnInit" SG_ 2150850560 PsSbltAtcV 2;
BA_ "GenSigSendType" SG_ 2150850560 PsSbltAtcV 10;
BA_ "VNSigAllNodes" SG_ 2150850560 PsSbltAtcV 1;
BA_ "SignalType" SG_ 2150850560 PsSbltAtcV "ENM";
BA_ "SignalLongName" SG_ 2150850560 PsSbltAtcV "Passenger Seatbelt Attached Validity";
BA_ "GenSigSendOnInit" SG_ 2150850560 PsSbltAtc 2;
BA_ "GenSigSendType" SG_ 2150850560 PsSbltAtc 10;
BA_ "VNSigAllNodes" SG_ 2150850560 PsSbltAtc 1;
BA_ "SignalType" SG_ 2150850560 PsSbltAtc "BLN";
BA_ "SignalLongName" SG_ 2150850560 PsSbltAtc "Passenger Seatbelt Attached";
BA_ "GenSigSendType" SG_ 2151735296 RtSdDetSysServDsbld 10;
BA_ "VNSigAllNodes" SG_ 2151735296 RtSdDetSysServDsbld 1;
BA_ "SignalType" SG_ 2151735296 RtSdDetSysServDsbld "BLN";
BA_ "SignalLongName" SG_ 2151735296 RtSdDetSysServDsbld "Right Side Detection System Service Disabled";
BA_ "GenSigSendType" SG_ 2151735296 RtSdDetSysTmpDsbld 10;
BA_ "VNSigAllNodes" SG_ 2151735296 RtSdDetSysTmpDsbld 1;
BA_ "SignalType" SG_ 2151735296 RtSdDetSysTmpDsbld "BLN";
BA_ "SignalLongName" SG_ 2151735296 RtSdDetSysTmpDsbld "Right Side Detection System Temp Disabled";
BA_ "GenSigSendType" SG_ 2151735296 RtLnChgAlrtEnbld 10;
BA_ "VNSigAllNodes" SG_ 2151735296 RtLnChgAlrtEnbld 1;
BA_ "SignalType" SG_ 2151735296 RtLnChgAlrtEnbld "BLN";
BA_ "SignalLongName" SG_ 2151735296 RtLnChgAlrtEnbld "Right Lane Change Alert Enabled";
BA_ "GenSigSendType" SG_ 2151735296 RtSBZAlrtEnbld 10;
BA_ "VNSigAllNodes" SG_ 2151735296 RtSBZAlrtEnbld 1;
BA_ "SignalType" SG_ 2151735296 RtSBZAlrtEnbld "BLN";
BA_ "SignalLongName" SG_ 2151735296 RtSBZAlrtEnbld "Right Side Blind Zone Alert Enabled";
BA_ "GenSigSendType" SG_ 2151735296 RtRrCrsTrfcAlrtEnbld 10;
BA_ "VNSigAllNodes" SG_ 2151735296 RtRrCrsTrfcAlrtEnbld 1;
BA_ "SignalType" SG_ 2151735296 RtRrCrsTrfcAlrtEnbld "BLN";
BA_ "SignalLongName" SG_ 2151735296 RtRrCrsTrfcAlrtEnbld "Right Rear Cross Traffic Alert Enabled";
BA_ "GenSigSendType" SG_ 2151735296 LnChgAlrtOffIndOn 10;
BA_ "VNSigAllNodes" SG_ 2151735296 LnChgAlrtOffIndOn 1;
BA_ "SignalType" SG_ 2151735296 LnChgAlrtOffIndOn "BLN";
BA_ "SignalLongName" SG_ 2151735296 LnChgAlrtOffIndOn "Lane Change Alert Off Indication On";
BA_ "GenSigSendType" SG_ 2151735296 RrCrsTrfcAlrtOffIO 10;
BA_ "VNSigAllNodes" SG_ 2151735296 RrCrsTrfcAlrtOffIO 1;
BA_ "SignalType" SG_ 2151735296 RrCrsTrfcAlrtOffIO "BLN";
BA_ "SignalLongName" SG_ 2151735296 RrCrsTrfcAlrtOffIO "Rear Cross Traffic Alert Off Indication On";
BA_ "GenSigSendOnInit" SG_ 2150776832 SftyMuteRd 1;
BA_ "GenSigSendType" SG_ 2150776832 SftyMuteRd 10;
BA_ "VNSigAllNodes" SG_ 2150776832 SftyMuteRd 1;
BA_ "SignalType" SG_ 2150776832 SftyMuteRd "BLN";
BA_ "SignalLongName" SG_ 2150776832 SftyMuteRd "Safety Mute Requested";
BA_ "GenSigSendType" SG_ 2150776832 ShfUlkBrToShftIndCtrl 10;
BA_ "VNSigAllNodes" SG_ 2150776832 ShfUlkBrToShftIndCtrl 1;
BA_ "SignalType" SG_ 2150776832 ShfUlkBrToShftIndCtrl "BLN";
BA_ "SignalLongName" SG_ 2150776832 ShfUlkBrToShftIndCtrl "Shifter Unlocked Brake To Shift Indication Control";
BA_ "GenSigSendType" SG_ 2150776832 ShftLkdBuStbltIndCtrl 10;
BA_ "VNSigAllNodes" SG_ 2150776832 ShftLkdBuStbltIndCtrl 1;
BA_ "SignalType" SG_ 2150776832 ShftLkdBuStbltIndCtrl "BLN";
BA_ "SignalLongName" SG_ 2150776832 ShftLkdBuStbltIndCtrl "Shifter Locked Buckle Seatbelts Indication Control";
BA_ "GenSigSendType" SG_ 2150776832 HybImpSnsDsbld 10;
BA_ "VNSigAllNodes" SG_ 2150776832 HybImpSnsDsbld 1;
BA_ "SignalType" SG_ 2150776832 HybImpSnsDsbld "BLN";
BA_ "SignalLongName" SG_ 2150776832 HybImpSnsDsbld "Hybrid Impact Sensing Disabled";
BA_ "GenSigSendType" SG_ 2150776832 HybVehHiVltInvDisRqd 10;
BA_ "VNSigAllNodes" SG_ 2150776832 HybVehHiVltInvDisRqd 1;
BA_ "SignalType" SG_ 2150776832 HybVehHiVltInvDisRqd "BLN";
BA_ "SignalLongName" SG_ 2150776832 HybVehHiVltInvDisRqd "Hybrid Vehicle High Voltage Inverter Disable Requested";
BA_ "GenSigSendType" SG_ 2150776832 SbItlkTrnsShftLvLkRd 10;
BA_ "VNSigAllNodes" SG_ 2150776832 SbItlkTrnsShftLvLkRd 1;
BA_ "SignalType" SG_ 2150776832 SbItlkTrnsShftLvLkRd "BLN";
BA_ "SignalLongName" SG_ 2150776832 SbItlkTrnsShftLvLkRd "Seatbelt Interlock Transmission Shift Lever Lock Requested";
BA_ "GenSigSendOnInit" SG_ 2150776832 MmryRclImpctDisRq 1;
BA_ "GenSigSendType" SG_ 2150776832 MmryRclImpctDisRq 10;
BA_ "VNSigAllNodes" SG_ 2150776832 MmryRclImpctDisRq 1;
BA_ "SignalType" SG_ 2150776832 MmryRclImpctDisRq "ENM";
BA_ "SignalLongName" SG_ 2150776832 MmryRclImpctDisRq "Memory Recall Impact Disable Request";
BA_ "GenSigSendType" SG_ 2150776832 EvntEnbld 10;
BA_ "VNSigAllNodes" SG_ 2150776832 EvntEnbld 1;
BA_ "SignalType" SG_ 2150776832 EvntEnbld "BLN";
BA_ "SignalLongName" SG_ 2150776832 EvntEnbld "Event Enabled";
BA_ "GenSigSendType" SG_ 2150776832 FrPsngrStOccSnsngPriDat 10;
BA_ "VNSigAllNodes" SG_ 2150776832 FrPsngrStOccSnsngPriDat 1;
BA_ "SignalType" SG_ 2150776832 FrPsngrStOccSnsngPriDat "BCD";
BA_ "SignalLongName" SG_ 2150776832 FrPsngrStOccSnsngPriDat "Front Passenger Seat Occupancy Sensing Primary Data";
BA_ "GenSigSendOnInit" SG_ 2150776832 SIREvntSychCntr 1;
BA_ "GenSigSendType" SG_ 2150776832 SIREvntSychCntr 12;
BA_ "GenSigDeltaValue" SG_ 2150776832 SIREvntSychCntr 1;
BA_ "VNSigAllNodes" SG_ 2150776832 SIREvntSychCntr 1;
BA_ "SignalType" SG_ 2150776832 SIREvntSychCntr "UNM";
BA_ "SignalLongName" SG_ 2150776832 SIREvntSychCntr "Supplemental Inflatable Restraint Event Synchronization Counter";
BA_ "GenSigSendType" SG_ 2150760448 NotSndRwRtSeatStat 10;
BA_ "VNSigAllNodes" SG_ 2150760448 NotSndRwRtSeatStat 1;
BA_ "SignalType" SG_ 2150760448 NotSndRwRtSeatStat "ENM";
BA_ "SignalLongName" SG_ 2150760448 NotSndRwRtSeatStat "Notification Second Row Right Seatbelt Status";
BA_ "GenSigSendType" SG_ 2150760448 NotSndRwMdlSeatStat 10;
BA_ "VNSigAllNodes" SG_ 2150760448 NotSndRwMdlSeatStat 1;
BA_ "SignalType" SG_ 2150760448 NotSndRwMdlSeatStat "ENM";
BA_ "SignalLongName" SG_ 2150760448 NotSndRwMdlSeatStat "Notification Second Row Middle Seatbelt Status";
BA_ "GenSigSendType" SG_ 2150760448 NotSndRwLtSeatStat 10;
BA_ "VNSigAllNodes" SG_ 2150760448 NotSndRwLtSeatStat 1;
BA_ "SignalType" SG_ 2150760448 NotSndRwLtSeatStat "ENM";
BA_ "SignalLongName" SG_ 2150760448 NotSndRwLtSeatStat "Notification Second Row Left Seatbelt Status";
BA_ "GenSigSendType" SG_ 2150760448 NotPsSeatStat 10;
BA_ "VNSigAllNodes" SG_ 2150760448 NotPsSeatStat 1;
BA_ "SignalType" SG_ 2150760448 NotPsSeatStat "ENM";
BA_ "SignalLongName" SG_ 2150760448 NotPsSeatStat "Notification Passenger Seatbelt Status";
BA_ "GenSigSendType" SG_ 2150760448 NotDrvSeatStat 10;
BA_ "VNSigAllNodes" SG_ 2150760448 NotDrvSeatStat 1;
BA_ "SignalType" SG_ 2150760448 NotDrvSeatStat "ENM";
BA_ "SignalLongName" SG_ 2150760448 NotDrvSeatStat "Notification Driver Seatbelt Status";
BA_ "GenSigSendType" SG_ 2150760448 NotSecRowRtSeaOccStat 10;
BA_ "VNSigAllNodes" SG_ 2150760448 NotSecRowRtSeaOccStat 1;
BA_ "SignalType" SG_ 2150760448 NotSecRowRtSeaOccStat "ENM";
BA_ "SignalLongName" SG_ 2150760448 NotSecRowRtSeaOccStat "Notification Second Row Right Seat Occupancy Status";
BA_ "GenSigSendType" SG_ 2150760448 NotSecRowLeSeaOccStat 10;
BA_ "VNSigAllNodes" SG_ 2150760448 NotSecRowLeSeaOccStat 1;
BA_ "SignalType" SG_ 2150760448 NotSecRowLeSeaOccStat "ENM";
BA_ "SignalLongName" SG_ 2150760448 NotSecRowLeSeaOccStat "Notification Second Row Left Seat Occupancy Status";
BA_ "GenSigSendType" SG_ 2150760448 NotSecRowCtSeaOccStat 10;
BA_ "VNSigAllNodes" SG_ 2150760448 NotSecRowCtSeaOccStat 1;
BA_ "SignalType" SG_ 2150760448 NotSecRowCtSeaOccStat "ENM";
BA_ "SignalLongName" SG_ 2150760448 NotSecRowCtSeaOccStat "Notification Second Row Center Seat Occupancy Status";
BA_ "GenSigSendType" SG_ 2150760448 NotiFrntPasSeatOccSta 10;
BA_ "VNSigAllNodes" SG_ 2150760448 NotiFrntPasSeatOccSta 1;
BA_ "SignalType" SG_ 2150760448 NotiFrntPasSeatOccSta "ENM";
BA_ "SignalLongName" SG_ 2150760448 NotiFrntPasSeatOccSta "Notification Front Passenger Seat Occupancy Status";
BA_ "GenSigSendType" SG_ 2150760448 NEDLSRtSdArbgDld 10;
BA_ "VNSigAllNodes" SG_ 2150760448 NEDLSRtSdArbgDld 1;
BA_ "SignalType" SG_ 2150760448 NEDLSRtSdArbgDld "BLN";
BA_ "PacketOrder" SG_ 2150760448 NEDLSRtSdArbgDld 6;
BA_ "SignalLongName" SG_ 2150760448 NEDLSRtSdArbgDld "Notification Event Deployed Loop Status : Right Side Airbag Deployed";
BA_ "GenSigSendType" SG_ 2150760448 NEDLSLtSdArbgDld 10;
BA_ "VNSigAllNodes" SG_ 2150760448 NEDLSLtSdArbgDld 1;
BA_ "SignalType" SG_ 2150760448 NEDLSLtSdArbgDld "BLN";
BA_ "PacketOrder" SG_ 2150760448 NEDLSLtSdArbgDld 5;
BA_ "SignalLongName" SG_ 2150760448 NEDLSLtSdArbgDld "Notification Event Deployed Loop Status : Left Side Airbag Deployed";
BA_ "GenSigSendType" SG_ 2150760448 NEDLSSdCrtnArbgDpld 10;
BA_ "VNSigAllNodes" SG_ 2150760448 NEDLSSdCrtnArbgDpld 1;
BA_ "SignalType" SG_ 2150760448 NEDLSSdCrtnArbgDpld "BLN";
BA_ "PacketOrder" SG_ 2150760448 NEDLSSdCrtnArbgDpld 7;
BA_ "SignalLongName" SG_ 2150760448 NEDLSSdCrtnArbgDpld "Notification Event Deployed Loop Status : Side Curtain Airbag Deployed";
BA_ "GenSigSendType" SG_ 2150760448 NEDLSPaFrSt2De 10;
BA_ "VNSigAllNodes" SG_ 2150760448 NEDLSPaFrSt2De 1;
BA_ "SignalType" SG_ 2150760448 NEDLSPaFrSt2De "BLN";
BA_ "PacketOrder" SG_ 2150760448 NEDLSPaFrSt2De 4;
BA_ "SignalLongName" SG_ 2150760448 NEDLSPaFrSt2De "Notification Event Deployed Loop Status : Passenger Front Stage 2 Deployed";
BA_ "GenSigSendType" SG_ 2150760448 NEDLSPaFrSt1De 10;
BA_ "VNSigAllNodes" SG_ 2150760448 NEDLSPaFrSt1De 1;
BA_ "SignalType" SG_ 2150760448 NEDLSPaFrSt1De "BLN";
BA_ "PacketOrder" SG_ 2150760448 NEDLSPaFrSt1De 3;
BA_ "SignalLongName" SG_ 2150760448 NEDLSPaFrSt1De "Notification Event Deployed Loop Status : Passenger Front Stage 1 Deployed";
BA_ "GenSigSendType" SG_ 2150760448 NEDLSDrFrSt2De 10;
BA_ "VNSigAllNodes" SG_ 2150760448 NEDLSDrFrSt2De 1;
BA_ "SignalType" SG_ 2150760448 NEDLSDrFrSt2De "BLN";
BA_ "PacketOrder" SG_ 2150760448 NEDLSDrFrSt2De 2;
BA_ "SignalLongName" SG_ 2150760448 NEDLSDrFrSt2De "Notification Event Deployed Loop Status : Driver Front Stage 2 Deployed";
BA_ "GenSigSendType" SG_ 2150760448 NEDLSDrFrSt1De 10;
BA_ "VNSigAllNodes" SG_ 2150760448 NEDLSDrFrSt1De 1;
BA_ "SignalType" SG_ 2150760448 NEDLSDrFrSt1De "BLN";
BA_ "PacketOrder" SG_ 2150760448 NEDLSDrFrSt1De 1;
BA_ "SignalLongName" SG_ 2150760448 NEDLSDrFrSt1De "Notification Event Deployed Loop Status : Driver Front Stage 1 Deployed";
BA_ "GenSigSendType" SG_ 2150760448 NotEventStat 10;
BA_ "VNSigAllNodes" SG_ 2150760448 NotEventStat 1;
BA_ "SignalType" SG_ 2150760448 NotEventStat "ENM";
BA_ "SignalLongName" SG_ 2150760448 NotEventStat "Notification Event Status";
BA_ "GenSigSendOnInit" SG_ 2150760448 SIRDpl 2;
BA_ "GenSigSendType" SG_ 2150760448 SIRDpl 10;
BA_ "VNSigAllNodes" SG_ 2150760448 SIRDpl 1;
BA_ "SignalType" SG_ 2150760448 SIRDpl "BLN";
BA_ "SignalLongName" SG_ 2150760448 SIRDpl "Airbag Deployed";
BA_ "GenSigSendType" SG_ 2150760448 NotiEventCount 12;
BA_ "GenSigDeltaValue" SG_ 2150760448 NotiEventCount 1;
BA_ "VNSigAllNodes" SG_ 2150760448 NotiEventCount 1;
BA_ "SignalType" SG_ 2150760448 NotiEventCount "UNM";
BA_ "SignalLongName" SG_ 2150760448 NotiEventCount "Notification Event Counter";
BA_ "GenSigSendType" SG_ 2150760448 NESSRoSevSt 10;
BA_ "VNSigAllNodes" SG_ 2150760448 NESSRoSevSt 1;
BA_ "SignalType" SG_ 2150760448 NESSRoSevSt "BLN";
BA_ "PacketOrder" SG_ 2150760448 NESSRoSevSt 7;
BA_ "SignalLongName" SG_ 2150760448 NESSRoSevSt "Notification Event Severity Status : Rollover Severity Achieved";
BA_ "GenSigSendType" SG_ 2150760448 NESSRiSiSevSt 10;
BA_ "VNSigAllNodes" SG_ 2150760448 NESSRiSiSevSt 1;
BA_ "SignalType" SG_ 2150760448 NESSRiSiSevSt "BLN";
BA_ "PacketOrder" SG_ 2150760448 NESSRiSiSevSt 6;
BA_ "SignalLongName" SG_ 2150760448 NESSRiSiSevSt "Notification Event Severity Status : Right Side Severity Achieved";
BA_ "GenSigSendType" SG_ 2150760448 NESSReImpSevSt 10;
BA_ "VNSigAllNodes" SG_ 2150760448 NESSReImpSevSt 1;
BA_ "SignalType" SG_ 2150760448 NESSReImpSevSt "BLN";
BA_ "PacketOrder" SG_ 2150760448 NESSReImpSevSt 5;
BA_ "SignalLongName" SG_ 2150760448 NESSReImpSevSt "Notification Event Severity Status : Rear Impact Severity Achieved";
BA_ "GenSigSendType" SG_ 2150760448 NESSLeSiSevSt 10;
BA_ "VNSigAllNodes" SG_ 2150760448 NESSLeSiSevSt 1;
BA_ "SignalType" SG_ 2150760448 NESSLeSiSevSt "BLN";
BA_ "PacketOrder" SG_ 2150760448 NESSLeSiSevSt 4;
BA_ "SignalLongName" SG_ 2150760448 NESSLeSiSevSt "Notification Event Severity Status : Left Side Severity Achieved";
BA_ "GenSigSendType" SG_ 2150760448 NESSFrImpSt2SevSt 10;
BA_ "VNSigAllNodes" SG_ 2150760448 NESSFrImpSt2SevSt 1;
BA_ "SignalType" SG_ 2150760448 NESSFrImpSt2SevSt "BLN";
BA_ "PacketOrder" SG_ 2150760448 NESSFrImpSt2SevSt 3;
BA_ "SignalLongName" SG_ 2150760448 NESSFrImpSt2SevSt "Notification Event Severity Status : Frontal Impact Stage 2 Severity Achieved";
BA_ "GenSigSendType" SG_ 2150760448 NESSFrImpSt1SevSt 10;
BA_ "VNSigAllNodes" SG_ 2150760448 NESSFrImpSt1SevSt 1;
BA_ "SignalType" SG_ 2150760448 NESSFrImpSt1SevSt "BLN";
BA_ "PacketOrder" SG_ 2150760448 NESSFrImpSt1SevSt 2;
BA_ "SignalLongName" SG_ 2150760448 NESSFrImpSt1SevSt "Notification Event Severity Status : Frontal Impact Stage 1 Severity Achieved";
BA_ "GenSigSendType" SG_ 2150760448 NESSFrImpPreSevSt 10;
BA_ "VNSigAllNodes" SG_ 2150760448 NESSFrImpPreSevSt 1;
BA_ "SignalType" SG_ 2150760448 NESSFrImpPreSevSt "BLN";
BA_ "PacketOrder" SG_ 2150760448 NESSFrImpPreSevSt 1;
BA_ "SignalLongName" SG_ 2150760448 NESSFrImpPreSevSt "Notification Event Severity Status : Frontal Impact Pretensioner Severity Achieved";
BA_ "VNSigDiagnostic" SG_ 581 DgnInf 1;
BA_ "GenSigSendType" SG_ 581 DgnInf 12;
BA_ "GenSigDeltaValue" SG_ 581 DgnInf 1;
BA_ "VNSigAllNodes" SG_ 581 DgnInf 1;
BA_ "SignalType" SG_ 581 DgnInf "UNM";
BA_ "SignalLongName" SG_ 581 DgnInf "Diagnostic Information";
BA_ "GenSigSendOnInit" SG_ 2151112704 FrPasSeatbltRemOccSt 2;
BA_ "GenSigSendType" SG_ 2151112704 FrPasSeatbltRemOccSt 10;
BA_ "VNSigAllNodes" SG_ 2151112704 FrPasSeatbltRemOccSt 1;
BA_ "SignalType" SG_ 2151112704 FrPasSeatbltRemOccSt "ENM";
BA_ "SignalLongName" SG_ 2151112704 FrPasSeatbltRemOccSt "Front Passenger Seatbelt Reminder Occupancy Status";
BA_ "GenSigSendOnInit" SG_ 2151112704 FrPasSeatResCtrlOccStV 2;
BA_ "GenSigSendType" SG_ 2151112704 FrPasSeatResCtrlOccStV 10;
BA_ "VNSigAllNodes" SG_ 2151112704 FrPasSeatResCtrlOccStV 1;
BA_ "SignalType" SG_ 2151112704 FrPasSeatResCtrlOccStV "ENM";
BA_ "SignalLongName" SG_ 2151112704 FrPasSeatResCtrlOccStV "Front Passenger Seat Restraint Control Occupancy Status Validity";
BA_ "GenSigSendOnInit" SG_ 2151112704 FrPasSeatResCtrlOccSt 2;
BA_ "GenSigSendType" SG_ 2151112704 FrPasSeatResCtrlOccSt 10;
BA_ "VNSigAllNodes" SG_ 2151112704 FrPasSeatResCtrlOccSt 1;
BA_ "SignalType" SG_ 2151112704 FrPasSeatResCtrlOccSt "ENM";
BA_ "SignalLongName" SG_ 2151112704 FrPasSeatResCtrlOccSt "Front Passenger Seat Restraint Control Occupancy Status";
BA_ "GenSigSendOnInit" SG_ 2151112704 FrPsSeatOccSnsOpMd 2;
BA_ "GenSigSendType" SG_ 2151112704 FrPsSeatOccSnsOpMd 10;
BA_ "VNSigAllNodes" SG_ 2151112704 FrPsSeatOccSnsOpMd 1;
BA_ "SignalType" SG_ 2151112704 FrPsSeatOccSnsOpMd "ENM";
BA_ "SignalLongName" SG_ 2151112704 FrPsSeatOccSnsOpMd "Front Passenger Seat Occupancy Sensing Operating Mode";
BA_ "GenSigSendOnInit" SG_ 2151112704 FrPsSeatOccFltSt 2;
BA_ "GenSigSendType" SG_ 2151112704 FrPsSeatOccFltSt 10;
BA_ "VNSigAllNodes" SG_ 2151112704 FrPsSeatOccFltSt 1;
BA_ "SignalType" SG_ 2151112704 FrPsSeatOccFltSt "ENM";
BA_ "SignalLongName" SG_ 2151112704 FrPsSeatOccFltSt "Front Passenger Seat Occupancy Fault Status";
BA_ "GenSigSendOnInit" SG_ 2151112704 FrntPassClass 2;
BA_ "GenSigSendType" SG_ 2151112704 FrntPassClass 10;
BA_ "VNSigAllNodes" SG_ 2151112704 FrntPassClass 1;
BA_ "SignalType" SG_ 2151112704 FrntPassClass "ENM";
BA_ "SignalLongName" SG_ 2151112704 FrntPassClass "Front Passenger Classification";
BA_ "VNSigDiagnostic" SG_ 1349 DgnInf_LS545 1;
BA_ "VNSigAllNodes" SG_ 1349 DgnInf_LS545 1;
BA_ "SignalType" SG_ 1349 DgnInf_LS545 "UNM";
BA_ "SignalLongName" SG_ 1349 DgnInf_LS545 "Diagnostic Information LS545";
BA_ "VNSigDiagnostic" SG_ 1605 DgnInf 1;
BA_ "GenSigSendType" SG_ 1605 DgnInf 12;
BA_ "GenSigDeltaValue" SG_ 1605 DgnInf 1;
BA_ "VNSigAllNodes" SG_ 1605 DgnInf 1;
BA_ "SignalType" SG_ 1605 DgnInf "UNM";
BA_ "SignalLongName" SG_ 1605 DgnInf "Diagnostic Information";
BA_ "GenSigSendOnInit" SG_ 2154496000 ShftrUnlkdBrkToShftIO 2;
BA_ "GenSigSendType" SG_ 2154496000 ShftrUnlkdBrkToShftIO 10;
BA_ "VNSigAllNodes" SG_ 2154496000 ShftrUnlkdBrkToShftIO 1;
BA_ "SignalType" SG_ 2154496000 ShftrUnlkdBrkToShftIO "BLN";
BA_ "SignalLongName" SG_ 2154496000 ShftrUnlkdBrkToShftIO "Shifter Unlocked Brake To Shift Indication On";
BA_ "GenSigSendOnInit" SG_ 2154496000 ShftrLkdBklPsnStbltIO 2;
BA_ "GenSigSendType" SG_ 2154496000 ShftrLkdBklPsnStbltIO 10;
BA_ "VNSigAllNodes" SG_ 2154496000 ShftrLkdBklPsnStbltIO 1;
BA_ "SignalType" SG_ 2154496000 ShftrLkdBklPsnStbltIO "BLN";
BA_ "SignalLongName" SG_ 2154496000 ShftrLkdBklPsnStbltIO "Shifter Locked Buckle Passenger Seatbelt Indication On";
BA_ "GenSigSendOnInit" SG_ 2154496000 ShftrLkdBklDrvStbltIO 2;
BA_ "GenSigSendType" SG_ 2154496000 ShftrLkdBklDrvStbltIO 10;
BA_ "VNSigAllNodes" SG_ 2154496000 ShftrLkdBklDrvStbltIO 1;
BA_ "SignalType" SG_ 2154496000 ShftrLkdBklDrvStbltIO "BLN";
BA_ "SignalLongName" SG_ 2154496000 ShftrLkdBklDrvStbltIO "Shifter Locked Buckle Driver Seatbelt Indication On";
BA_ "GenSigSendOnInit" SG_ 2154496000 CmpSftTopMotBfrOpTrnkIO 2;
BA_ "GenSigSendType" SG_ 2154496000 CmpSftTopMotBfrOpTrnkIO 10;
BA_ "VNSigAllNodes" SG_ 2154496000 CmpSftTopMotBfrOpTrnkIO 1;
BA_ "SignalType" SG_ 2154496000 CmpSftTopMotBfrOpTrnkIO "BLN";
BA_ "SignalLongName" SG_ 2154496000 CmpSftTopMotBfrOpTrnkIO "Complete Soft Top Motion Before Open Trunk Indication On";
BA_ "GenSigSendOnInit" SG_ 2154496000 TargaTopStateV 2;
BA_ "GenSigSendType" SG_ 2154496000 TargaTopStateV 10;
BA_ "VNSigAllNodes" SG_ 2154496000 TargaTopStateV 1;
BA_ "SignalType" SG_ 2154496000 TargaTopStateV "ENM";
BA_ "SignalLongName" SG_ 2154496000 TargaTopStateV "Targa Top State Validity";
BA_ "GenSigSendOnInit" SG_ 2154496000 TargaTopState 2;
BA_ "GenSigSendType" SG_ 2154496000 TargaTopState 10;
BA_ "VNSigAllNodes" SG_ 2154496000 TargaTopState 1;
BA_ "SignalType" SG_ 2154496000 TargaTopState "ENM";
BA_ "SignalLongName" SG_ 2154496000 TargaTopState "Targa Top State";
BA_ "GenSigSendType" SG_ 2154471424 RrClsrSnwLdIO 10;
BA_ "VNSigAllNodes" SG_ 2154471424 RrClsrSnwLdIO 1;
BA_ "SignalType" SG_ 2154471424 RrClsrSnwLdIO "BLN";
BA_ "SignalLongName" SG_ 2154471424 RrClsrSnwLdIO "Rear Closure Snow Load Indication On";
BA_ "GenSigSendOnInit" SG_ 2154471424 RrClosAjarSwAct 1;
BA_ "GenSigSendType" SG_ 2154471424 RrClosAjarSwAct 10;
BA_ "VNSigAllNodes" SG_ 2154471424 RrClosAjarSwAct 1;
BA_ "SignalType" SG_ 2154471424 RrClosAjarSwAct "BLN";
BA_ "SignalLongName" SG_ 2154471424 RrClosAjarSwAct "Rear Closure Ajar Switch Active";
BA_ "GenSigSendType" SG_ 2151063552 TrfRdsdInfCsStReq 10;
BA_ "VNSigAllNodes" SG_ 2151063552 TrfRdsdInfCsStReq 1;
BA_ "SignalType" SG_ 2151063552 TrfRdsdInfCsStReq "ENM";
BA_ "SignalLongName" SG_ 2151063552 TrfRdsdInfCsStReq "Traffic and Roadside Information Customization Setting Request";
BA_ "GenSigSendType" SG_ 2151063552 IntrStopAlrtCsSetReq 10;
BA_ "VNSigAllNodes" SG_ 2151063552 IntrStopAlrtCsSetReq 1;
BA_ "SignalType" SG_ 2151063552 IntrStopAlrtCsSetReq "ENM";
BA_ "SignalLongName" SG_ 2151063552 IntrStopAlrtCsSetReq "Intersection Stop Alert Customization Setting Request";
BA_ "GenSigSendType" SG_ 2151063552 CntdVehBrAltCsStReq 10;
BA_ "VNSigAllNodes" SG_ 2151063552 CntdVehBrAltCsStReq 1;
BA_ "SignalType" SG_ 2151063552 CntdVehBrAltCsStReq "ENM";
BA_ "SignalLongName" SG_ 2151063552 CntdVehBrAltCsStReq "Connected Vehicle Braking Alerts Customization Setting Request";
BA_ "GenSigSendType" SG_ 2151063552 ICSTS_Y1TchCrdnt 12;
BA_ "GenSigDeltaValue" SG_ 2151063552 ICSTS_Y1TchCrdnt 1;
BA_ "VNSigAllNodes" SG_ 2151063552 ICSTS_Y1TchCrdnt 1;
BA_ "SignalType" SG_ 2151063552 ICSTS_Y1TchCrdnt "UNM";
BA_ "PacketOrder" SG_ 2151063552 ICSTS_Y1TchCrdnt 3;
BA_ "SignalLongName" SG_ 2151063552 ICSTS_Y1TchCrdnt "Integrated Center Stack Touch Status : Y1 Touch Coordinate";
BA_ "GenSigSendType" SG_ 2151063552 ICSTS_X1TchCrdnt 12;
BA_ "GenSigDeltaValue" SG_ 2151063552 ICSTS_X1TchCrdnt 1;
BA_ "VNSigAllNodes" SG_ 2151063552 ICSTS_X1TchCrdnt 1;
BA_ "SignalType" SG_ 2151063552 ICSTS_X1TchCrdnt "UNM";
BA_ "PacketOrder" SG_ 2151063552 ICSTS_X1TchCrdnt 2;
BA_ "SignalLongName" SG_ 2151063552 ICSTS_X1TchCrdnt "Integrated Center Stack Touch Status : X1 Touch Coordinate";
BA_ "GenSigSendType" SG_ 2151063552 ICSTS_TchPrxmty 10;
BA_ "VNSigAllNodes" SG_ 2151063552 ICSTS_TchPrxmty 1;
BA_ "SignalType" SG_ 2151063552 ICSTS_TchPrxmty "ENM";
BA_ "PacketOrder" SG_ 2151063552 ICSTS_TchPrxmty 1;
BA_ "SignalLongName" SG_ 2151063552 ICSTS_TchPrxmty "Integrated Center Stack Touch Status : Touch Proximity";
BA_ "GenSigSendType" SG_ 2151063552 TrgdVidRecSwAct 10;
BA_ "VNSigAllNodes" SG_ 2151063552 TrgdVidRecSwAct 1;
BA_ "SignalType" SG_ 2151063552 TrgdVidRecSwAct "BLN";
BA_ "SignalLongName" SG_ 2151063552 TrgdVidRecSwAct "Triggered Video Recorder Switch Active";
BA_ "GenSigSendType" SG_ 2151063552 RrPedDetCstStReq 10;
BA_ "VNSigAllNodes" SG_ 2151063552 RrPedDetCstStReq 1;
BA_ "SignalType" SG_ 2151063552 RrPedDetCstStReq "ENM";
BA_ "SignalLongName" SG_ 2151063552 RrPedDetCstStReq "Rear Pedestrian Detection Customization Setting Request";
BA_ "GenSigSendType" SG_ 2151063552 CamVideoICSDispAct 10;
BA_ "VNSigAllNodes" SG_ 2151063552 CamVideoICSDispAct 1;
BA_ "SignalType" SG_ 2151063552 CamVideoICSDispAct "BLN";
BA_ "SignalLongName" SG_ 2151063552 CamVideoICSDispAct "Camera Video ICS Display Active";
BA_ "GenSigSendType" SG_ 2151063552 Frnt360CamSwAct 10;
BA_ "VNSigAllNodes" SG_ 2151063552 Frnt360CamSwAct 1;
BA_ "SignalType" SG_ 2151063552 Frnt360CamSwAct "BLN";
BA_ "SignalLongName" SG_ 2151063552 Frnt360CamSwAct "Front 360 Camera Switch Active";
BA_ "GenSigSendType" SG_ 2151063552 ValetMdAct 10;
BA_ "VNSigAllNodes" SG_ 2151063552 ValetMdAct 1;
BA_ "SignalType" SG_ 2151063552 ValetMdAct "BLN";
BA_ "SignalLongName" SG_ 2151063552 ValetMdAct "Valet Mode Active";
BA_ "GenSigSendOnInit" SG_ 2151063552 InftnOprAlwd 1;
BA_ "GenSigSendType" SG_ 2151063552 InftnOprAlwd 10;
BA_ "VNSigAllNodes" SG_ 2151063552 InftnOprAlwd 1;
BA_ "SignalType" SG_ 2151063552 InftnOprAlwd "BLN";
BA_ "SignalLongName" SG_ 2151063552 InftnOprAlwd "Infotainment Operation Allowed";
BA_ "VNSigDiagnostic" SG_ 1574 VectraSpcNWMgtD 1;
BA_ "VNSigUnused_4" SG_ 1574 VectraSpcNWMgtD 1;
BA_ "VNSigIntermediate" SG_ 1574 VectraSpcNWMgtD 1;
BA_ "VNSigParkedVehicle" SG_ 1574 VectraSpcNWMgtD 1;
BA_ "VNSigRemoteDiagnostics" SG_ 1574 VectraSpcNWMgtD 1;
BA_ "VNSigAllNodes" SG_ 1574 VectraSpcNWMgtD 1;
BA_ "SignalType" SG_ 1574 VectraSpcNWMgtD "UNM";
BA_ "SignalLongName" SG_ 1574 VectraSpcNWMgtD "Vectra Specific Network Management Data";
BA_ "VNSigDiagnostic" SG_ 1571 VectraSpcNWMgtD 1;
BA_ "VNSigUnused_4" SG_ 1571 VectraSpcNWMgtD 1;
BA_ "VNSigIntermediate" SG_ 1571 VectraSpcNWMgtD 1;
BA_ "VNSigParkedVehicle" SG_ 1571 VectraSpcNWMgtD 1;
BA_ "VNSigRemoteDiagnostics" SG_ 1571 VectraSpcNWMgtD 1;
BA_ "VNSigAllNodes" SG_ 1571 VectraSpcNWMgtD 1;
BA_ "SignalType" SG_ 1571 VectraSpcNWMgtD "UNM";
BA_ "SignalLongName" SG_ 1571 VectraSpcNWMgtD "Vectra Specific Network Management Data";
BA_ "GenSigSendType" SG_ 2155167744 ClsEngCmprtmtToStrtVehIO 10;
BA_ "VNSigAllNodes" SG_ 2155167744 ClsEngCmprtmtToStrtVehIO 1;
BA_ "SignalType" SG_ 2155167744 ClsEngCmprtmtToStrtVehIO "BLN";
BA_ "SignalLongName" SG_ 2155167744 ClsEngCmprtmtToStrtVehIO "Close Engine Compartment To Start Vehicle Indication On";
BA_ "GenSigSendType" SG_ 2155167744 PrsCltchPrsStrtAgnIO 10;
BA_ "VNSigAllNodes" SG_ 2155167744 PrsCltchPrsStrtAgnIO 1;
BA_ "SignalType" SG_ 2155167744 PrsCltchPrsStrtAgnIO "BLN";
BA_ "SignalLongName" SG_ 2155167744 PrsCltchPrsStrtAgnIO "Press Clutch and Press Start Again Indication On";
BA_ "GenSigSendType" SG_ 2155167744 PrsStrtAgnIO 10;
BA_ "VNSigAllNodes" SG_ 2155167744 PrsStrtAgnIO 1;
BA_ "SignalType" SG_ 2155167744 PrsStrtAgnIO "BLN";
BA_ "SignalLongName" SG_ 2155167744 PrsStrtAgnIO "Press Start Again Indication On";
BA_ "GenSigSendType" SG_ 2155167744 AutoShtdwnDsblIO 10;
BA_ "VNSigAllNodes" SG_ 2155167744 AutoShtdwnDsblIO 1;
BA_ "SignalType" SG_ 2155167744 AutoShtdwnDsblIO "BLN";
BA_ "SignalLongName" SG_ 2155167744 AutoShtdwnDsblIO "Automatic Shutdown Disabled Indication On";
BA_ "GenSigSendType" SG_ 2155167744 ShftToNtrlIO 10;
BA_ "VNSigAllNodes" SG_ 2155167744 ShftToNtrlIO 1;
BA_ "SignalType" SG_ 2155167744 ShftToNtrlIO "BLN";
BA_ "SignalLongName" SG_ 2155167744 ShftToNtrlIO "Shift to Neutral Indication On";
BA_ "GenSigSendType" SG_ 2155167744 AppPrkBrkIO 10;
BA_ "VNSigAllNodes" SG_ 2155167744 AppPrkBrkIO 1;
BA_ "SignalType" SG_ 2155167744 AppPrkBrkIO "BLN";
BA_ "SignalLongName" SG_ 2155167744 AppPrkBrkIO "Apply Park Brake Indication On";
BA_ "GenSigSendType" SG_ 2155167744 NRmtDtctdRstrtAllwd 10;
BA_ "VNSigAllNodes" SG_ 2155167744 NRmtDtctdRstrtAllwd 1;
BA_ "SignalType" SG_ 2155167744 NRmtDtctdRstrtAllwd "BLN";
BA_ "SignalLongName" SG_ 2155167744 NRmtDtctdRstrtAllwd "No Remote Detected Restart Allowed";
BA_ "GenSigSendType" SG_ 2155167744 NRmtDtdPsCluRstIO 10;
BA_ "VNSigAllNodes" SG_ 2155167744 NRmtDtdPsCluRstIO 1;
BA_ "SignalType" SG_ 2155167744 NRmtDtdPsCluRstIO "BLN";
BA_ "SignalLongName" SG_ 2155167744 NRmtDtdPsCluRstIO "No Remote Detected Press Clutch to Restart Indicator On";
BA_ "GenSigSendType" SG_ 2155167744 SecPwrMdPshBtnAtv 10;
BA_ "VNSigAllNodes" SG_ 2155167744 SecPwrMdPshBtnAtv 1;
BA_ "SignalType" SG_ 2155167744 SecPwrMdPshBtnAtv "BLN";
BA_ "SignalLongName" SG_ 2155167744 SecPwrMdPshBtnAtv "Secondary Power Mode Pushbutton Active";
BA_ "GenSigSendType" SG_ 2155167744 TSLgMdPwrCtOWAtv 10;
BA_ "VNSigAllNodes" SG_ 2155167744 TSLgMdPwrCtOWAtv 1;
BA_ "SignalType" SG_ 2155167744 TSLgMdPwrCtOWAtv "BLN";
BA_ "SignalLongName" SG_ 2155167744 TSLgMdPwrCtOWAtv "Transport Storage Logistic Mode Power Cut Off Warning Active";
BA_ "GenSigSendType" SG_ 2155167744 PrsBtnAgnTTrnEngOffIO 10;
BA_ "VNSigAllNodes" SG_ 2155167744 PrsBtnAgnTTrnEngOffIO 1;
BA_ "SignalType" SG_ 2155167744 PrsBtnAgnTTrnEngOffIO "BLN";
BA_ "SignalLongName" SG_ 2155167744 PrsBtnAgnTTrnEngOffIO "Press Button Again to Turn Engine Off Indicator On";
BA_ "GenSigSendType" SG_ 2155167744 NRmtDtdPsBrkRstIO 10;
BA_ "VNSigAllNodes" SG_ 2155167744 NRmtDtdPsBrkRstIO 1;
BA_ "SignalType" SG_ 2155167744 NRmtDtdPsBrkRstIO "BLN";
BA_ "SignalLongName" SG_ 2155167744 NRmtDtdPsBrkRstIO "No Remote Detected Press Brake to Restart Indicator On";
BA_ "GenSigSendType" SG_ 2155167744 NoReDetInOn 10;
BA_ "VNSigAllNodes" SG_ 2155167744 NoReDetInOn 1;
BA_ "SignalType" SG_ 2155167744 NoReDetInOn "BLN";
BA_ "SignalLongName" SG_ 2155167744 NoReDetInOn "No Remote Detected Indication On";
BA_ "GenSigSendType" SG_ 2155167744 ApplyCltPdlIO 10;
BA_ "VNSigAllNodes" SG_ 2155167744 ApplyCltPdlIO 1;
BA_ "SignalType" SG_ 2155167744 ApplyCltPdlIO "BLN";
BA_ "SignalLongName" SG_ 2155167744 ApplyCltPdlIO "Apply Clutch Pedal Indication On";
BA_ "GenSigSendType" SG_ 2155167744 TransModInactIO 10;
BA_ "VNSigAllNodes" SG_ 2155167744 TransModInactIO 1;
BA_ "SignalType" SG_ 2155167744 TransModInactIO "BLN";
BA_ "SignalLongName" SG_ 2155167744 TransModInactIO "Transport Mode Inactive Indication On";
BA_ "GenSigSendType" SG_ 2155167744 TransModActIO 10;
BA_ "VNSigAllNodes" SG_ 2155167744 TransModActIO 1;
BA_ "SignalType" SG_ 2155167744 TransModActIO "BLN";
BA_ "SignalLongName" SG_ 2155167744 TransModActIO "Transport Mode Active Indication On";
BA_ "GenSigSendType" SG_ 2155167744 ApplyBrkPdlIO 10;
BA_ "VNSigAllNodes" SG_ 2155167744 ApplyBrkPdlIO 1;
BA_ "SignalType" SG_ 2155167744 ApplyBrkPdlIO "BLN";
BA_ "SignalLongName" SG_ 2155167744 ApplyBrkPdlIO "Apply Brake Pedal Indication On";
BA_ "VNSigIntermediate" SG_ 2155167744 Ky_IdDevPr 1;
BA_ "GenSigSendOnInit" SG_ 2155167744 Ky_IdDevPr 1;
BA_ "GenSigSendType" SG_ 2155167744 Ky_IdDevPr 10;
BA_ "VNSigAllNodes" SG_ 2155167744 Ky_IdDevPr 1;
BA_ "SignalType" SG_ 2155167744 Ky_IdDevPr "BLN";
BA_ "SignalLongName" SG_ 2155167744 Ky_IdDevPr "Key / Identification Device Present";
BA_ "GenSigSendType" SG_ 2155167744 KylsStrtUseTxPckIO 10;
BA_ "VNSigAllNodes" SG_ 2155167744 KylsStrtUseTxPckIO 1;
BA_ "SignalType" SG_ 2155167744 KylsStrtUseTxPckIO "BLN";
BA_ "SignalLongName" SG_ 2155167744 KylsStrtUseTxPckIO "Keyless Start Use Transmitter Pocket Indication On";
BA_ "GenSigSendType" SG_ 2155167744 ShftPrkIO 10;
BA_ "VNSigAllNodes" SG_ 2155167744 ShftPrkIO 1;
BA_ "SignalType" SG_ 2155167744 ShftPrkIO "BLN";
BA_ "SignalLongName" SG_ 2155167744 ShftPrkIO "Shift to Park Indication On";
BA_ "GenSigSendOnInit" SG_ 2155167744 VehMovState 1;
BA_ "GenSigSendType" SG_ 2155167744 VehMovState 10;
BA_ "VNSigAllNodes" SG_ 2155167744 VehMovState 1;
BA_ "SignalType" SG_ 2155167744 VehMovState "ENM";
BA_ "SignalLongName" SG_ 2155167744 VehMovState "Vehicle Movement State";
BA_ "GenSigSendOnInit" SG_ 2155167744 TrStLgMdAtv 1;
BA_ "GenSigSendType" SG_ 2155167744 TrStLgMdAtv 10;
BA_ "VNSigAllNodes" SG_ 2155167744 TrStLgMdAtv 1;
BA_ "SignalType" SG_ 2155167744 TrStLgMdAtv "BLN";
BA_ "SignalLongName" SG_ 2155167744 TrStLgMdAtv "Transport Storage Logistic Mode Active";
BA_ "VNSigDiagnostic" SG_ 1568 VectraSpcNWMgtD 1;
BA_ "VNSigUnused_4" SG_ 1568 VectraSpcNWMgtD 1;
BA_ "VNSigIntermediate" SG_ 1568 VectraSpcNWMgtD 1;
BA_ "VNSigParkedVehicle" SG_ 1568 VectraSpcNWMgtD 1;
BA_ "VNSigRemoteDiagnostics" SG_ 1568 VectraSpcNWMgtD 1;
BA_ "VNSigAllNodes" SG_ 1568 VectraSpcNWMgtD 1;
BA_ "SignalType" SG_ 1568 VectraSpcNWMgtD "UNM";
BA_ "SignalLongName" SG_ 1568 VectraSpcNWMgtD "Vectra Specific Network Management Data";
BA_ "VNSigDiagnostic" SG_ 1570 VectraSpcNWMgtD 1;
BA_ "VNSigUnused_4" SG_ 1570 VectraSpcNWMgtD 1;
BA_ "VNSigIntermediate" SG_ 1570 VectraSpcNWMgtD 1;
BA_ "VNSigParkedVehicle" SG_ 1570 VectraSpcNWMgtD 1;
BA_ "VNSigRemoteDiagnostics" SG_ 1570 VectraSpcNWMgtD 1;
BA_ "VNSigAllNodes" SG_ 1570 VectraSpcNWMgtD 1;
BA_ "SignalType" SG_ 1570 VectraSpcNWMgtD "UNM";
BA_ "SignalLongName" SG_ 1570 VectraSpcNWMgtD "Vectra Specific Network Management Data";
BA_ "VNSigDiagnostic" SG_ 1579 VectraSpcNWMgtD 1;
BA_ "VNSigUnused_4" SG_ 1579 VectraSpcNWMgtD 1;
BA_ "VNSigIntermediate" SG_ 1579 VectraSpcNWMgtD 1;
BA_ "VNSigParkedVehicle" SG_ 1579 VectraSpcNWMgtD 1;
BA_ "VNSigRemoteDiagnostics" SG_ 1579 VectraSpcNWMgtD 1;
BA_ "VNSigAllNodes" SG_ 1579 VectraSpcNWMgtD 1;
BA_ "SignalType" SG_ 1579 VectraSpcNWMgtD "UNM";
BA_ "SignalLongName" SG_ 1579 VectraSpcNWMgtD "Vectra Specific Network Management Data";
BA_ "VNSigDiagnostic" SG_ 1599 VectraSpcNWMgtD 1;
BA_ "VNSigUnused_4" SG_ 1599 VectraSpcNWMgtD 1;
BA_ "VNSigIntermediate" SG_ 1599 VectraSpcNWMgtD 1;
BA_ "VNSigParkedVehicle" SG_ 1599 VectraSpcNWMgtD 1;
BA_ "VNSigRemoteDiagnostics" SG_ 1599 VectraSpcNWMgtD 1;
BA_ "VNSigAllNodes" SG_ 1599 VectraSpcNWMgtD 1;
BA_ "SignalType" SG_ 1599 VectraSpcNWMgtD "UNM";
BA_ "SignalLongName" SG_ 1599 VectraSpcNWMgtD "Vectra Specific Network Management Data";
BA_ "VNSigDiagnostic" SG_ 1585 VectraSpcNWMgtD 1;
BA_ "VNSigUnused_4" SG_ 1585 VectraSpcNWMgtD 1;
BA_ "VNSigIntermediate" SG_ 1585 VectraSpcNWMgtD 1;
BA_ "VNSigParkedVehicle" SG_ 1585 VectraSpcNWMgtD 1;
BA_ "VNSigRemoteDiagnostics" SG_ 1585 VectraSpcNWMgtD 1;
BA_ "VNSigAllNodes" SG_ 1585 VectraSpcNWMgtD 1;
BA_ "SignalType" SG_ 1585 VectraSpcNWMgtD "UNM";
BA_ "SignalLongName" SG_ 1585 VectraSpcNWMgtD "Vectra Specific Network Management Data";
BA_ "VNSigDiagnostic" SG_ 1572 VectraSpcNWMgtD 1;
BA_ "VNSigUnused_4" SG_ 1572 VectraSpcNWMgtD 1;
BA_ "VNSigIntermediate" SG_ 1572 VectraSpcNWMgtD 1;
BA_ "VNSigParkedVehicle" SG_ 1572 VectraSpcNWMgtD 1;
BA_ "VNSigRemoteDiagnostics" SG_ 1572 VectraSpcNWMgtD 1;
BA_ "VNSigAllNodes" SG_ 1572 VectraSpcNWMgtD 1;
BA_ "SignalType" SG_ 1572 VectraSpcNWMgtD "UNM";
BA_ "SignalLongName" SG_ 1572 VectraSpcNWMgtD "Vectra Specific Network Management Data";
BA_ "VNSigDiagnostic" SG_ 1597 VectraSpcNWMgtD 1;
BA_ "VNSigUnused_4" SG_ 1597 VectraSpcNWMgtD 1;
BA_ "VNSigIntermediate" SG_ 1597 VectraSpcNWMgtD 1;
BA_ "VNSigParkedVehicle" SG_ 1597 VectraSpcNWMgtD 1;
BA_ "VNSigRemoteDiagnostics" SG_ 1597 VectraSpcNWMgtD 1;
BA_ "VNSigAllNodes" SG_ 1597 VectraSpcNWMgtD 1;
BA_ "SignalType" SG_ 1597 VectraSpcNWMgtD "UNM";
BA_ "SignalLongName" SG_ 1597 VectraSpcNWMgtD "Vectra Specific Network Management Data";
BA_ "VNSigDiagnostic" SG_ 1576 VectraSpcNWMgtD 1;
BA_ "VNSigUnused_4" SG_ 1576 VectraSpcNWMgtD 1;
BA_ "VNSigIntermediate" SG_ 1576 VectraSpcNWMgtD 1;
BA_ "VNSigParkedVehicle" SG_ 1576 VectraSpcNWMgtD 1;
BA_ "VNSigRemoteDiagnostics" SG_ 1576 VectraSpcNWMgtD 1;
BA_ "VNSigAllNodes" SG_ 1576 VectraSpcNWMgtD 1;
BA_ "SignalType" SG_ 1576 VectraSpcNWMgtD "UNM";
BA_ "SignalLongName" SG_ 1576 VectraSpcNWMgtD "Vectra Specific Network Management Data";
BA_ "VNSigDiagnostic" SG_ 1593 VectraSpcNWMgtD 1;
BA_ "VNSigUnused_4" SG_ 1593 VectraSpcNWMgtD 1;
BA_ "VNSigIntermediate" SG_ 1593 VectraSpcNWMgtD 1;
BA_ "VNSigParkedVehicle" SG_ 1593 VectraSpcNWMgtD 1;
BA_ "VNSigRemoteDiagnostics" SG_ 1593 VectraSpcNWMgtD 1;
BA_ "VNSigAllNodes" SG_ 1593 VectraSpcNWMgtD 1;
BA_ "SignalType" SG_ 1593 VectraSpcNWMgtD "UNM";
BA_ "SignalLongName" SG_ 1593 VectraSpcNWMgtD "Vectra Specific Network Management Data";
BA_ "VNSigDiagnostic" SG_ 1589 VectraSpcNWMgtD 1;
BA_ "VNSigUnused_4" SG_ 1589 VectraSpcNWMgtD 1;
BA_ "VNSigIntermediate" SG_ 1589 VectraSpcNWMgtD 1;
BA_ "VNSigParkedVehicle" SG_ 1589 VectraSpcNWMgtD 1;
BA_ "VNSigRemoteDiagnostics" SG_ 1589 VectraSpcNWMgtD 1;
BA_ "VNSigAllNodes" SG_ 1589 VectraSpcNWMgtD 1;
BA_ "SignalType" SG_ 1589 VectraSpcNWMgtD "UNM";
BA_ "SignalLongName" SG_ 1589 VectraSpcNWMgtD "Vectra Specific Network Management Data";
BA_ "VNSigDiagnostic" SG_ 257 DgnInf 1;
BA_ "GenSigSendType" SG_ 257 DgnInf 12;
BA_ "GenSigDeltaValue" SG_ 257 DgnInf 1;
BA_ "VNSigAllNodes" SG_ 257 DgnInf 1;
BA_ "SignalType" SG_ 257 DgnInf "UNM";
BA_ "SignalLongName" SG_ 257 DgnInf "Diagnostic Information";
BA_ "VNSigDiagnostic" SG_ 1587 VectraSpcNWMgtD 1;
BA_ "VNSigUnused_4" SG_ 1587 VectraSpcNWMgtD 1;
BA_ "VNSigIntermediate" SG_ 1587 VectraSpcNWMgtD 1;
BA_ "VNSigParkedVehicle" SG_ 1587 VectraSpcNWMgtD 1;
BA_ "VNSigRemoteDiagnostics" SG_ 1587 VectraSpcNWMgtD 1;
BA_ "VNSigAllNodes" SG_ 1587 VectraSpcNWMgtD 1;
BA_ "SignalType" SG_ 1587 VectraSpcNWMgtD "UNM";
BA_ "SignalLongName" SG_ 1587 VectraSpcNWMgtD "Vectra Specific Network Management Data";
BA_ "VNSigDiagnostic" SG_ 1575 VectraSpcNWMgtD 1;
BA_ "VNSigUnused_4" SG_ 1575 VectraSpcNWMgtD 1;
BA_ "VNSigIntermediate" SG_ 1575 VectraSpcNWMgtD 1;
BA_ "VNSigParkedVehicle" SG_ 1575 VectraSpcNWMgtD 1;
BA_ "VNSigRemoteDiagnostics" SG_ 1575 VectraSpcNWMgtD 1;
BA_ "VNSigAllNodes" SG_ 1575 VectraSpcNWMgtD 1;
BA_ "SignalType" SG_ 1575 VectraSpcNWMgtD "UNM";
BA_ "SignalLongName" SG_ 1575 VectraSpcNWMgtD "Vectra Specific Network Management Data";
BA_ "VNSigDiagnostic" SG_ 1581 VectraSpcNWMgtD 1;
BA_ "VNSigUnused_4" SG_ 1581 VectraSpcNWMgtD 1;
BA_ "VNSigIntermediate" SG_ 1581 VectraSpcNWMgtD 1;
BA_ "VNSigParkedVehicle" SG_ 1581 VectraSpcNWMgtD 1;
BA_ "VNSigRemoteDiagnostics" SG_ 1581 VectraSpcNWMgtD 1;
BA_ "VNSigAllNodes" SG_ 1581 VectraSpcNWMgtD 1;
BA_ "SignalType" SG_ 1581 VectraSpcNWMgtD "UNM";
BA_ "SignalLongName" SG_ 1581 VectraSpcNWMgtD "Vectra Specific Network Management Data";
BA_ "VNSigDiagnostic" SG_ 1580 VectraSpcNWMgtD 1;
BA_ "VNSigUnused_4" SG_ 1580 VectraSpcNWMgtD 1;
BA_ "VNSigIntermediate" SG_ 1580 VectraSpcNWMgtD 1;
BA_ "VNSigParkedVehicle" SG_ 1580 VectraSpcNWMgtD 1;
BA_ "VNSigRemoteDiagnostics" SG_ 1580 VectraSpcNWMgtD 1;
BA_ "VNSigAllNodes" SG_ 1580 VectraSpcNWMgtD 1;
BA_ "SignalType" SG_ 1580 VectraSpcNWMgtD "UNM";
BA_ "SignalLongName" SG_ 1580 VectraSpcNWMgtD "Vectra Specific Network Management Data";
BA_ "VNSigDiagnostic" SG_ 1584 VectraSpcNWMgtD 1;
BA_ "VNSigUnused_4" SG_ 1584 VectraSpcNWMgtD 1;
BA_ "VNSigIntermediate" SG_ 1584 VectraSpcNWMgtD 1;
BA_ "VNSigParkedVehicle" SG_ 1584 VectraSpcNWMgtD 1;
BA_ "VNSigRemoteDiagnostics" SG_ 1584 VectraSpcNWMgtD 1;
BA_ "VNSigAllNodes" SG_ 1584 VectraSpcNWMgtD 1;
BA_ "SignalType" SG_ 1584 VectraSpcNWMgtD "UNM";
BA_ "SignalLongName" SG_ 1584 VectraSpcNWMgtD "Vectra Specific Network Management Data";
BA_ "VNSigDiagnostic" SG_ 1569 VectraSpcNWMgtD 1;
BA_ "VNSigUnused_4" SG_ 1569 VectraSpcNWMgtD 1;
BA_ "VNSigIntermediate" SG_ 1569 VectraSpcNWMgtD 1;
BA_ "VNSigParkedVehicle" SG_ 1569 VectraSpcNWMgtD 1;
BA_ "VNSigRemoteDiagnostics" SG_ 1569 VectraSpcNWMgtD 1;
BA_ "VNSigAllNodes" SG_ 1569 VectraSpcNWMgtD 1;
BA_ "SignalType" SG_ 1569 VectraSpcNWMgtD "UNM";
BA_ "SignalLongName" SG_ 1569 VectraSpcNWMgtD "Vectra Specific Network Management Data";
BA_ "VNSigDiagnostic" SG_ 1573 VectraSpcNWMgtD 1;
BA_ "VNSigUnused_4" SG_ 1573 VectraSpcNWMgtD 1;
BA_ "VNSigIntermediate" SG_ 1573 VectraSpcNWMgtD 1;
BA_ "VNSigParkedVehicle" SG_ 1573 VectraSpcNWMgtD 1;
BA_ "VNSigRemoteDiagnostics" SG_ 1573 VectraSpcNWMgtD 1;
BA_ "VNSigAllNodes" SG_ 1573 VectraSpcNWMgtD 1;
BA_ "SignalType" SG_ 1573 VectraSpcNWMgtD "UNM";
BA_ "SignalLongName" SG_ 1573 VectraSpcNWMgtD "Vectra Specific Network Management Data";
BA_ "VNSigIntermediate" SG_ 2151677952 SndLocRtRr 1;
BA_ "GenSigSendType" SG_ 2151677952 SndLocRtRr 10;
BA_ "VNSigAllNodes" SG_ 2151677952 SndLocRtRr 1;
BA_ "SignalType" SG_ 2151677952 SndLocRtRr "BLN";
BA_ "PacketOrder" SG_ 2151677952 SndLocRtRr 4;
BA_ "SignalLongName" SG_ 2151677952 SndLocRtRr "Sound Location : Right Rear";
BA_ "VNSigIntermediate" SG_ 2151677952 SndLocLftRr 1;
BA_ "GenSigSendType" SG_ 2151677952 SndLocLftRr 10;
BA_ "VNSigAllNodes" SG_ 2151677952 SndLocLftRr 1;
BA_ "SignalType" SG_ 2151677952 SndLocLftRr "BLN";
BA_ "PacketOrder" SG_ 2151677952 SndLocLftRr 3;
BA_ "SignalLongName" SG_ 2151677952 SndLocLftRr "Sound Location : Left Rear";
BA_ "VNSigIntermediate" SG_ 2151677952 SndLocPasFr 1;
BA_ "GenSigSendType" SG_ 2151677952 SndLocPasFr 10;
BA_ "VNSigAllNodes" SG_ 2151677952 SndLocPasFr 1;
BA_ "SignalType" SG_ 2151677952 SndLocPasFr "BLN";
BA_ "PacketOrder" SG_ 2151677952 SndLocPasFr 2;
BA_ "SignalLongName" SG_ 2151677952 SndLocPasFr "Sound Location : Passenger Front";
BA_ "VNSigIntermediate" SG_ 2151677952 SndLocDrFr 1;
BA_ "GenSigSendType" SG_ 2151677952 SndLocDrFr 10;
BA_ "VNSigAllNodes" SG_ 2151677952 SndLocDrFr 1;
BA_ "SignalType" SG_ 2151677952 SndLocDrFr "BLN";
BA_ "PacketOrder" SG_ 2151677952 SndLocDrFr 1;
BA_ "SignalLongName" SG_ 2151677952 SndLocDrFr "Sound Location : Driver Front";
BA_ "VNSigIntermediate" SG_ 2151677952 SC_SndDutCyc 1;
BA_ "GenSigSendType" SG_ 2151677952 SC_SndDutCyc 12;
BA_ "GenSigDeltaValue" SG_ 2151677952 SC_SndDutCyc 1;
BA_ "VNSigAllNodes" SG_ 2151677952 SC_SndDutCyc 1;
BA_ "SignalType" SG_ 2151677952 SC_SndDutCyc "UNM";
BA_ "PacketOrder" SG_ 2151677952 SC_SndDutCyc 4;
BA_ "SignalLongName" SG_ 2151677952 SC_SndDutCyc "Sound Characteristics : Sound Duty Cycle";
BA_ "VNSigIntermediate" SG_ 2151677952 SC_NmofRp 1;
BA_ "GenSigSendType" SG_ 2151677952 SC_NmofRp 12;
BA_ "GenSigDeltaValue" SG_ 2151677952 SC_NmofRp 1;
BA_ "VNSigAllNodes" SG_ 2151677952 SC_NmofRp 1;
BA_ "SignalType" SG_ 2151677952 SC_NmofRp "UNM";
BA_ "PacketOrder" SG_ 2151677952 SC_NmofRp 3;
BA_ "SignalLongName" SG_ 2151677952 SC_NmofRp "Sound Characteristics : Number of Repetitions";
BA_ "VNSigIntermediate" SG_ 2151677952 SC_SndCdnPrd 1;
BA_ "GenSigSendType" SG_ 2151677952 SC_SndCdnPrd 12;
BA_ "GenSigDeltaValue" SG_ 2151677952 SC_SndCdnPrd 1;
BA_ "VNSigAllNodes" SG_ 2151677952 SC_SndCdnPrd 1;
BA_ "SignalType" SG_ 2151677952 SC_SndCdnPrd "UNM";
BA_ "PacketOrder" SG_ 2151677952 SC_SndCdnPrd 2;
BA_ "SignalLongName" SG_ 2151677952 SC_SndCdnPrd "Sound Characteristics : Sound Cadence Period";
BA_ "VNSigIntermediate" SG_ 2151677952 SC_SndTne 1;
BA_ "GenSigSendType" SG_ 2151677952 SC_SndTne 10;
BA_ "VNSigAllNodes" SG_ 2151677952 SC_SndTne 1;
BA_ "SignalType" SG_ 2151677952 SC_SndTne "ENM";
BA_ "PacketOrder" SG_ 2151677952 SC_SndTne 1;
BA_ "SignalLongName" SG_ 2151677952 SC_SndTne "Sound Characteristics : Sound Tone";
BA_ "VNSigIntermediate" SG_ 2151677952 SndPriority 1;
BA_ "GenSigSendType" SG_ 2151677952 SndPriority 12;
BA_ "GenSigDeltaValue" SG_ 2151677952 SndPriority 1;
BA_ "VNSigAllNodes" SG_ 2151677952 SndPriority 1;
BA_ "SignalType" SG_ 2151677952 SndPriority "UNM";
BA_ "SignalLongName" SG_ 2151677952 SndPriority "Sound Priority";
BA_ "VNSigIntermediate" SG_ 2149859328 SysBkUpPwrMdV 1;
BA_ "VNSigParkedVehicle" SG_ 2149859328 SysBkUpPwrMdV 1;
BA_ "GenSigSendType" SG_ 2149859328 SysBkUpPwrMdV 10;
BA_ "VNSigAllNodes" SG_ 2149859328 SysBkUpPwrMdV 1;
BA_ "SignalType" SG_ 2149859328 SysBkUpPwrMdV "ENM";
BA_ "SignalLongName" SG_ 2149859328 SysBkUpPwrMdV "System Backup Power Mode Validity";
BA_ "VNSigIntermediate" SG_ 2149859328 SysBkupPwrMdEn 1;
BA_ "VNSigParkedVehicle" SG_ 2149859328 SysBkupPwrMdEn 1;
BA_ "GenSigSendOnInit" SG_ 2149859328 SysBkupPwrMdEn 1;
BA_ "GenSigSendType" SG_ 2149859328 SysBkupPwrMdEn 10;
BA_ "VNSigAllNodes" SG_ 2149859328 SysBkupPwrMdEn 1;
BA_ "SignalType" SG_ 2149859328 SysBkupPwrMdEn "BLN";
BA_ "SignalLongName" SG_ 2149859328 SysBkupPwrMdEn "System Backup Power Mode Enabled";
BA_ "VNSigIntermediate" SG_ 2149859328 SysBkUpPwrMd 1;
BA_ "VNSigParkedVehicle" SG_ 2149859328 SysBkUpPwrMd 1;
BA_ "GenSigSendOnInit" SG_ 2149859328 SysBkUpPwrMd 1;
BA_ "GenSigSendType" SG_ 2149859328 SysBkUpPwrMd 10;
BA_ "VNSigAllNodes" SG_ 2149859328 SysBkUpPwrMd 1;
BA_ "SignalType" SG_ 2149859328 SysBkUpPwrMd "ENM";
BA_ "SignalLongName" SG_ 2149859328 SysBkUpPwrMd "System Backup Power Mode";
BA_ "GenSigSendOnInit" SG_ 2150604800 RRDoorAjarSwAct 2;
BA_ "GenSigSendType" SG_ 2150604800 RRDoorAjarSwAct 10;
BA_ "VNSigAllNodes" SG_ 2150604800 RRDoorAjarSwAct 1;
BA_ "SignalType" SG_ 2150604800 RRDoorAjarSwAct "BLN";
BA_ "SignalLongName" SG_ 2150604800 RRDoorAjarSwAct "Rear Right Door Ajar Switch Active";
BA_ "GenSigSendOnInit" SG_ 2150588416 PDAjrSwAtv 2;
BA_ "GenSigSendType" SG_ 2150588416 PDAjrSwAtv 10;
BA_ "VNSigAllNodes" SG_ 2150588416 PDAjrSwAtv 1;
BA_ "SignalType" SG_ 2150588416 PDAjrSwAtv "BLN";
BA_ "SignalLongName" SG_ 2150588416 PDAjrSwAtv "Passenger Door Ajar Switch Active";
BA_ "GenSigSendOnInit" SG_ 2150596608 RLDoorAjarSwAct 2;
BA_ "GenSigSendType" SG_ 2150596608 RLDoorAjarSwAct 10;
BA_ "VNSigAllNodes" SG_ 2150596608 RLDoorAjarSwAct 1;
BA_ "SignalType" SG_ 2150596608 RLDoorAjarSwAct "BLN";
BA_ "SignalLongName" SG_ 2150596608 RLDoorAjarSwAct "Rear Left Door Ajar Switch Active";
BA_ "VNSigAllNodes" SG_ 2150416384 PTWrmgWtToShftIO 1;
BA_ "SignalType" SG_ 2150416384 PTWrmgWtToShftIO "BLN";
BA_ "SignalLongName" SG_ 2150416384 PTWrmgWtToShftIO "Powertrain Warming Wait To Shift Indication On";
BA_ "VNSigAllNodes" SG_ 2150416384 EngTrqActExtRngV 1;
BA_ "SignalType" SG_ 2150416384 EngTrqActExtRngV "ENM";
BA_ "SignalLongName" SG_ 2150416384 EngTrqActExtRngV "Engine Torque Actual Extended Range Validity";
BA_ "VNSigAllNodes" SG_ 2150416384 VehTopSpdLmtMdAct 1;
BA_ "SignalType" SG_ 2150416384 VehTopSpdLmtMdAct "BLN";
BA_ "SignalLongName" SG_ 2150416384 VehTopSpdLmtMdAct "Vehicle Top Speed Limit Mode Active";
BA_ "VNSigAllNodes" SG_ 2150416384 EngTrqActExtRng 1;
BA_ "SignalType" SG_ 2150416384 EngTrqActExtRng "UNM";
BA_ "SignalLongName" SG_ 2150416384 EngTrqActExtRng "Engine Torque Actual Extended Range";
BA_ "GenSigStartValue" SG_ 2150416384 EngTrqActExtRng 1696;
BA_ "VNSigAllNodes" SG_ 2150416384 EngIdlAtv 1;
BA_ "SignalType" SG_ 2150416384 EngIdlAtv "BLN";
BA_ "SignalLongName" SG_ 2150416384 EngIdlAtv "Engine Idle Active";
BA_ "VNSigAllNodes" SG_ 2150416384 EngSpdStat 1;
BA_ "SignalType" SG_ 2150416384 EngSpdStat "ENM";
BA_ "SignalLongName" SG_ 2150416384 EngSpdStat "Engine Speed Status";
BA_ "VNSigAllNodes" SG_ 2150416384 VaccBoostFailure 1;
BA_ "SignalType" SG_ 2150416384 VaccBoostFailure "BLN";
BA_ "SignalLongName" SG_ 2150416384 VaccBoostFailure "Vaccum Boost Failure";
BA_ "VNSigAllNodes" SG_ 2150416384 RmVhStrtEngRng 1;
BA_ "SignalType" SG_ 2150416384 RmVhStrtEngRng "BLN";
BA_ "SignalLongName" SG_ 2150416384 RmVhStrtEngRng "Remote Vehicle Start Engine Running";
BA_ "VNSigAllNodes" SG_ 2150416384 EngCoolFanSpd 1;
BA_ "SignalType" SG_ 2150416384 EngCoolFanSpd "UNM";
BA_ "SignalLongName" SG_ 2150416384 EngCoolFanSpd "Engine Cooling Fan Speed";
BA_ "VNSigAllNodes" SG_ 2150416384 GenFld 1;
BA_ "SignalType" SG_ 2150416384 GenFld "BLN";
BA_ "SignalLongName" SG_ 2150416384 GenFld "Generator Failed";
BA_ "VNSigAllNodes" SG_ 2150416384 EngSpdLmtnMdAct 1;
BA_ "SignalType" SG_ 2150416384 EngSpdLmtnMdAct "BLN";
BA_ "SignalLongName" SG_ 2150416384 EngSpdLmtnMdAct "Engine Speed Limitation Mode Active";
BA_ "VNSigAllNodes" SG_ 2150416384 EngNEmsnsRelMalfAct 1;
BA_ "SignalType" SG_ 2150416384 EngNEmsnsRelMalfAct "BLN";
BA_ "SignalLongName" SG_ 2150416384 EngNEmsnsRelMalfAct "Engine Non Emissions Related Malfunction Active";
BA_ "VNSigAllNodes" SG_ 2150416384 EngCstFlCutAct 1;
BA_ "SignalType" SG_ 2150416384 EngCstFlCutAct "BLN";
BA_ "SignalLongName" SG_ 2150416384 EngCstFlCutAct "Engine Coast Fuel Cut Off Active";
BA_ "VNSigAllNodes" SG_ 2150416384 EngBstPrsIndV 1;
BA_ "SignalType" SG_ 2150416384 EngBstPrsIndV "ENM";
BA_ "SignalLongName" SG_ 2150416384 EngBstPrsIndV "Engine Boost Pressure Indication Validity";
BA_ "VNSigAllNodes" SG_ 2150416384 EngBstPrsInd 1;
BA_ "SignalType" SG_ 2150416384 EngBstPrsInd "UNM";
BA_ "SignalLongName" SG_ 2150416384 EngBstPrsInd "Engine Boost Pressure Indication";
BA_ "VNSigAllNodes" SG_ 2150416384 TrnCrpMdAtv 1;
BA_ "SignalType" SG_ 2150416384 TrnCrpMdAtv "BLN";
BA_ "SignalLongName" SG_ 2150416384 TrnCrpMdAtv "Transmission Creep Mode Active";
BA_ "VNSigAllNodes" SG_ 2150416384 VehTopSpdLmtArbVal 1;
BA_ "SignalType" SG_ 2150416384 VehTopSpdLmtArbVal "UNM";
BA_ "SignalLongName" SG_ 2150416384 VehTopSpdLmtArbVal "Vehicle Top Speed Limit Arbitrated Value";
BA_ "VNSigAllNodes" SG_ 2150416384 TrnsVDA 1;
BA_ "SignalType" SG_ 2150416384 TrnsVDA "ENM";
BA_ "SignalLongName" SG_ 2150416384 TrnsVDA "Transmission Virtual Device Availability";
BA_ "GenSigStartValue" SG_ 2150416384 TrnsVDA 1;
BA_ "VNSigAllNodes" SG_ 2150416384 TransEstGear 1;
BA_ "SignalType" SG_ 2150416384 TransEstGear "ENM";
BA_ "SignalLongName" SG_ 2150416384 TransEstGear "Transmission Estimated Gear";
BA_ "GenSigStartValue" SG_ 2150416384 TransEstGear 15;
BA_ "VNSigAllNodes" SG_ 2150416384 TransEstGearV 1;
BA_ "SignalType" SG_ 2150416384 TransEstGearV "ENM";
BA_ "SignalLongName" SG_ 2150416384 TransEstGearV "Transmission Estimated Gear Validity";
BA_ "VNSigAllNodes" SG_ 2150416384 EngVDA 1;
BA_ "SignalType" SG_ 2150416384 EngVDA "ENM";
BA_ "SignalLongName" SG_ 2150416384 EngVDA "Engine Virtual Device Availability";
BA_ "GenSigStartValue" SG_ 2150416384 EngVDA 1;
BA_ "GenSigSendType" SG_ 2150416384 EngRunAtv 10;
BA_ "VNSigAllNodes" SG_ 2150416384 EngRunAtv 1;
BA_ "SignalType" SG_ 2150416384 EngRunAtv "BLN";
BA_ "SignalLongName" SG_ 2150416384 EngRunAtv "Engine Run Active";
BA_ "VNSigAllNodes" SG_ 2150416384 EngCylDeactMd 1;
BA_ "SignalType" SG_ 2150416384 EngCylDeactMd "ENM";
BA_ "SignalLongName" SG_ 2150416384 EngCylDeactMd "Engine Cylinder Deactivation Mode";
BA_ "VNSigAllNodes" SG_ 2150408192 ElcRngSelDrvAct 1;
BA_ "SignalType" SG_ 2150408192 ElcRngSelDrvAct "BLN";
BA_ "SignalLongName" SG_ 2150408192 ElcRngSelDrvAct "Electronic Range Selection In Drive Active";
BA_ "VNSigAllNodes" SG_ 2150408192 TmpDrvrShftCtlAct 1;
BA_ "SignalType" SG_ 2150408192 TmpDrvrShftCtlAct "BLN";
BA_ "SignalLongName" SG_ 2150408192 TmpDrvrShftCtlAct "Temporary Driver Shift Control Active";
BA_ "VNSigAllNodes" SG_ 2150408192 AdptPsngrSeatStng 1;
BA_ "SignalType" SG_ 2150408192 AdptPsngrSeatStng "ENM";
BA_ "SignalLongName" SG_ 2150408192 AdptPsngrSeatStng "Adaptive Passenger Seat Setting";
BA_ "VNSigAllNodes" SG_ 2150408192 EngRunng 1;
BA_ "SignalType" SG_ 2150408192 EngRunng "BLN";
BA_ "SignalLongName" SG_ 2150408192 EngRunng "Engine Running";
BA_ "VNSigAllNodes" SG_ 2150408192 Eng12vStrtrMtrCmmdOn 1;
BA_ "SignalType" SG_ 2150408192 Eng12vStrtrMtrCmmdOn "BLN";
BA_ "SignalLongName" SG_ 2150408192 Eng12vStrtrMtrCmmdOn "Engine 12 Volt Starter Motor Commanded On";
BA_ "VNSigAllNodes" SG_ 2150408192 AccPdlOvrrdAtv 1;
BA_ "SignalType" SG_ 2150408192 AccPdlOvrrdAtv "BLN";
BA_ "SignalLongName" SG_ 2150408192 AccPdlOvrrdAtv "Accelerator Pedal Override Active";
BA_ "VNSigAllNodes" SG_ 2150408192 TopTrvlCltchSwActV 1;
BA_ "SignalType" SG_ 2150408192 TopTrvlCltchSwActV "ENM";
BA_ "SignalLongName" SG_ 2150408192 TopTrvlCltchSwActV "Top of Travel Clutch Switch Active Validity";
BA_ "VNSigAllNodes" SG_ 2150408192 TopTrvlCltchSwAct 1;
BA_ "SignalType" SG_ 2150408192 TopTrvlCltchSwAct "BLN";
BA_ "SignalLongName" SG_ 2150408192 TopTrvlCltchSwAct "Top of Travel Clutch Switch Active";
BA_ "VNSigAllNodes" SG_ 2150408192 CltStartSwAtvV 1;
BA_ "SignalType" SG_ 2150408192 CltStartSwAtvV "ENM";
BA_ "SignalLongName" SG_ 2150408192 CltStartSwAtvV "Clutch Start Switch Active Validity";
BA_ "VNSigAllNodes" SG_ 2150408192 CltStartSwAtv 1;
BA_ "SignalType" SG_ 2150408192 CltStartSwAtv "BLN";
BA_ "SignalLongName" SG_ 2150408192 CltStartSwAtv "Clutch Start Switch Active";
BA_ "GenSigStartValue" SG_ 2150408192 CltStartSwAtv 1;
BA_ "GenSigSendOnInit" SG_ 2150408192 CrsCntEnbld 1;
BA_ "VNSigAllNodes" SG_ 2150408192 CrsCntEnbld 1;
BA_ "SignalType" SG_ 2150408192 CrsCntEnbld "BLN";
BA_ "SignalLongName" SG_ 2150408192 CrsCntEnbld "Cruise Control Enabled";
BA_ "VNSigAllNodes" SG_ 2150408192 AccActPosV 1;
BA_ "SignalType" SG_ 2150408192 AccActPosV "ENM";
BA_ "SignalLongName" SG_ 2150408192 AccActPosV "Accelerator Actual Position Validity";
BA_ "VNSigAllNodes" SG_ 2150408192 TrnsSftMdStat 1;
BA_ "SignalType" SG_ 2150408192 TrnsSftMdStat "ENM";
BA_ "SignalLongName" SG_ 2150408192 TrnsSftMdStat "Transmission Shift Mode Status";
BA_ "VNSigAllNodes" SG_ 2150408192 AutoTransComndGear 1;
BA_ "SignalType" SG_ 2150408192 AutoTransComndGear "ENM";
BA_ "SignalLongName" SG_ 2150408192 AutoTransComndGear "Automatic Transmission Commanded Gear";
BA_ "GenSigStartValue" SG_ 2150408192 AutoTransComndGear 15;
BA_ "VNSigAllNodes" SG_ 2150408192 TrnShftPtrnActStat 1;
BA_ "SignalType" SG_ 2150408192 TrnShftPtrnActStat "ENM";
BA_ "SignalLongName" SG_ 2150408192 TrnShftPtrnActStat "Transmission Shift Pattern Active Status";
BA_ "VNSigAllNodes" SG_ 2150408192 AccActPos 1;
BA_ "SignalType" SG_ 2150408192 AccActPos "UNM";
BA_ "SignalLongName" SG_ 2150408192 AccActPos "Accelerator Actual Position";
BA_ "VNSigAllNodes" SG_ 2150408192 ThrPosV 1;
BA_ "SignalType" SG_ 2150408192 ThrPosV "ENM";
BA_ "SignalLongName" SG_ 2150408192 ThrPosV "Throttle Position Validity";
BA_ "VNSigAllNodes" SG_ 2150408192 TransTUDMdStat 1;
BA_ "SignalType" SG_ 2150408192 TransTUDMdStat "ENM";
BA_ "SignalLongName" SG_ 2150408192 TransTUDMdStat "Transmission Tap Up/Tap Down Mode Status";
BA_ "VNSigAllNodes" SG_ 2150408192 ThrPos 1;
BA_ "SignalType" SG_ 2150408192 ThrPos "UNM";
BA_ "SignalLongName" SG_ 2150408192 ThrPos "Throttle Position";
BA_ "VNSigAllNodes" SG_ 2150408192 TrnsShftLvrPosV 1;
BA_ "SignalType" SG_ 2150408192 TrnsShftLvrPosV "ENM";
BA_ "SignalLongName" SG_ 2150408192 TrnsShftLvrPosV "Transmission Shift Lever Position Validity";
BA_ "VNSigAllNodes" SG_ 2150408192 TrnsShftLvrPos 1;
BA_ "SignalType" SG_ 2150408192 TrnsShftLvrPos "ENM";
BA_ "SignalLongName" SG_ 2150408192 TrnsShftLvrPos "Transmission Shift Lever Position";
BA_ "VNSigAllNodes" SG_ 2150408192 EngSpd 1;
BA_ "SignalType" SG_ 2150408192 EngSpd "UNM";
BA_ "SignalLongName" SG_ 2150408192 EngSpd "Engine Speed";
BA_ "GenSigSendOnInit" SG_ 2153971712 LftglsRelSwAct 2;
BA_ "GenSigSendType" SG_ 2153971712 LftglsRelSwAct 10;
BA_ "VNSigAllNodes" SG_ 2153971712 LftglsRelSwAct 1;
BA_ "SignalType" SG_ 2153971712 LftglsRelSwAct "BLN";
BA_ "SignalLongName" SG_ 2153971712 LftglsRelSwAct "Liftglass Release Switch Active";
BA_ "GenSigSendOnInit" SG_ 2153971712 LftglsAjrSwAct 2;
BA_ "GenSigSendType" SG_ 2153971712 LftglsAjrSwAct 10;
BA_ "VNSigAllNodes" SG_ 2153971712 LftglsAjrSwAct 1;
BA_ "SignalType" SG_ 2153971712 LftglsAjrSwAct "BLN";
BA_ "SignalLongName" SG_ 2153971712 LftglsAjrSwAct "Liftglass Ajar Switch Active";
BA_ "GenSigSendType" SG_ 2153971712 DDAjrSwAtvM 10;
BA_ "VNSigAllNodes" SG_ 2153971712 DDAjrSwAtvM 1;
BA_ "SignalType" SG_ 2153971712 DDAjrSwAtvM "ENM";
BA_ "SignalLongName" SG_ 2153971712 DDAjrSwAtvM "Driver Door Ajar Switch Active Mask";
BA_ "VNSigIntermediate" SG_ 2153971712 DDAjrSwAtv 1;
BA_ "GenSigSendOnInit" SG_ 2153971712 DDAjrSwAtv 2;
BA_ "GenSigSendType" SG_ 2153971712 DDAjrSwAtv 10;
BA_ "VNSigAllNodes" SG_ 2153971712 DDAjrSwAtv 1;
BA_ "SignalType" SG_ 2153971712 DDAjrSwAtv "BLN";
BA_ "SignalLongName" SG_ 2153971712 DDAjrSwAtv "Driver Door Ajar Switch Active";
BA_ "GenSigSendType" SG_ 2151792640 RCTARIC_Indctr1Act 10;
BA_ "VNSigAllNodes" SG_ 2151792640 RCTARIC_Indctr1Act 1;
BA_ "SignalType" SG_ 2151792640 RCTARIC_Indctr1Act "BLN";
BA_ "PacketOrder" SG_ 2151792640 RCTARIC_Indctr1Act 1;
BA_ "SignalLongName" SG_ 2151792640 RCTARIC_Indctr1Act "Rear Cross Traffic Alert Right Indication Control : Indicator 1 Active";
BA_ "GenSigSendType" SG_ 2151792640 RCTARIC_IndReq 10;
BA_ "VNSigAllNodes" SG_ 2151792640 RCTARIC_IndReq 1;
BA_ "SignalType" SG_ 2151792640 RCTARIC_IndReq "ENM";
BA_ "PacketOrder" SG_ 2151792640 RCTARIC_IndReq 2;
BA_ "SignalLongName" SG_ 2151792640 RCTARIC_IndReq "Rear Cross Traffic Alert Right Indication Control : Indication Request";
BA_ "GenSigSendType" SG_ 2151792640 RrCTfcRHptcStRqSqN 12;
BA_ "GenSigDeltaValue" SG_ 2151792640 RrCTfcRHptcStRqSqN 1;
BA_ "VNSigAllNodes" SG_ 2151792640 RrCTfcRHptcStRqSqN 1;
BA_ "SignalType" SG_ 2151792640 RrCTfcRHptcStRqSqN "UNM";
BA_ "SignalLongName" SG_ 2151792640 RrCTfcRHptcStRqSqN "Rear Cross Traffic Alert Right Haptic Seat Request Sequence Number";
BA_ "GenSigSendType" SG_ 2151792640 RrCTfcRHptcStReq 12;
BA_ "GenSigDeltaValue" SG_ 2151792640 RrCTfcRHptcStReq 1;
BA_ "VNSigAllNodes" SG_ 2151792640 RrCTfcRHptcStReq 1;
BA_ "SignalType" SG_ 2151792640 RrCTfcRHptcStReq "UNM";
BA_ "SignalLongName" SG_ 2151792640 RrCTfcRHptcStReq "Rear Cross Traffic Alert Right Haptic Seat Request";
BA_ "GenSigSendType" SG_ 2151776256 RCTALIC_Indctr1Act 10;
BA_ "VNSigAllNodes" SG_ 2151776256 RCTALIC_Indctr1Act 1;
BA_ "SignalType" SG_ 2151776256 RCTALIC_Indctr1Act "BLN";
BA_ "PacketOrder" SG_ 2151776256 RCTALIC_Indctr1Act 1;
BA_ "SignalLongName" SG_ 2151776256 RCTALIC_Indctr1Act "Rear Cross Traffic Alert Left Indication Control : Indicator 1 Active";
BA_ "GenSigSendType" SG_ 2151776256 RCTALIC_IndReq 10;
BA_ "VNSigAllNodes" SG_ 2151776256 RCTALIC_IndReq 1;
BA_ "SignalType" SG_ 2151776256 RCTALIC_IndReq "ENM";
BA_ "PacketOrder" SG_ 2151776256 RCTALIC_IndReq 2;
BA_ "SignalLongName" SG_ 2151776256 RCTALIC_IndReq "Rear Cross Traffic Alert Left Indication Control : Indication Request";
BA_ "GenSigSendType" SG_ 2151776256 RrCTfcLHptcStRqSeqN 12;
BA_ "GenSigDeltaValue" SG_ 2151776256 RrCTfcLHptcStRqSeqN 1;
BA_ "VNSigAllNodes" SG_ 2151776256 RrCTfcLHptcStRqSeqN 1;
BA_ "SignalType" SG_ 2151776256 RrCTfcLHptcStRqSeqN "UNM";
BA_ "SignalLongName" SG_ 2151776256 RrCTfcLHptcStRqSeqN "Rear Cross Traffic Alert Left Haptic Seat Request Sequence Number";
BA_ "GenSigSendType" SG_ 2151776256 RrCTfcLHptcStReq 12;
BA_ "GenSigDeltaValue" SG_ 2151776256 RrCTfcLHptcStReq 1;
BA_ "VNSigAllNodes" SG_ 2151776256 RrCTfcLHptcStReq 1;
BA_ "SignalType" SG_ 2151776256 RrCTfcLHptcStReq "UNM";
BA_ "SignalLongName" SG_ 2151776256 RrCTfcLHptcStReq "Rear Cross Traffic Alert Left Haptic Seat Request";
BA_ "VNSigAllNodes" SG_ 2149646336 VehSpdAvgDrvnSrc 1;
BA_ "SignalType" SG_ 2149646336 VehSpdAvgDrvnSrc "ENM";
BA_ "SignalLongName" SG_ 2149646336 VehSpdAvgDrvnSrc "Vehicle Speed Average Driven Source";
BA_ "VNSigAllNodes" SG_ 2149646336 DstRolCntAvgNonDrvnV 1;
BA_ "SignalType" SG_ 2149646336 DstRolCntAvgNonDrvnV "ENM";
BA_ "SignalLongName" SG_ 2149646336 DstRolCntAvgNonDrvnV "Distance Rolling Count Average Non Driven Validity";
BA_ "VNSigAllNodes" SG_ 2149646336 DstRolCntAvNDrRstOc 1;
BA_ "SignalType" SG_ 2149646336 DstRolCntAvNDrRstOc "BLN";
BA_ "SignalLongName" SG_ 2149646336 DstRolCntAvNDrRstOc "Distance Rolling Count Average Non Driven Reset Occurred";
BA_ "VNSigAllNodes" SG_ 2149646336 DstRolCntAvgNonDrvn 1;
BA_ "SignalType" SG_ 2149646336 DstRolCntAvgNonDrvn "UNM";
BA_ "SignalLongName" SG_ 2149646336 DstRolCntAvgNonDrvn "Distance Rolling Count Average Non Driven";
BA_ "VNSigAllNodes" SG_ 2149646336 DstRolCntAvgDrnRstOc 1;
BA_ "SignalType" SG_ 2149646336 DstRolCntAvgDrnRstOc "BLN";
BA_ "SignalLongName" SG_ 2149646336 DstRolCntAvgDrnRstOc "Distance Rolling Count Average Driven Reset Occurred";
BA_ "VNSigAllNodes" SG_ 2149646336 DistRollCntAvgDrvnSrc 1;
BA_ "SignalType" SG_ 2149646336 DistRollCntAvgDrvnSrc "ENM";
BA_ "SignalLongName" SG_ 2149646336 DistRollCntAvgDrvnSrc "Distance Rolling Count Average Driven Source";
BA_ "VNSigAllNodes" SG_ 2149646336 VehSpdAvgNDrvnV 1;
BA_ "SignalType" SG_ 2149646336 VehSpdAvgNDrvnV "ENM";
BA_ "SignalLongName" SG_ 2149646336 VehSpdAvgNDrvnV "Vehicle Speed Average Non Driven Validity";
BA_ "GenSigSendOnInit" SG_ 2149646336 VehSpdAvgNDrvn 1;
BA_ "VNSigAllNodes" SG_ 2149646336 VehSpdAvgNDrvn 1;
BA_ "SignalType" SG_ 2149646336 VehSpdAvgNDrvn "UNM";
BA_ "SignalLongName" SG_ 2149646336 VehSpdAvgNDrvn "Vehicle Speed Average Non Driven";
BA_ "VNSigAllNodes" SG_ 2149646336 DistRollCntAvgDrvnV 1;
BA_ "SignalType" SG_ 2149646336 DistRollCntAvgDrvnV "ENM";
BA_ "SignalLongName" SG_ 2149646336 DistRollCntAvgDrvnV "Distance Rolling Count Average Driven Validity";
BA_ "VNSigAllNodes" SG_ 2149646336 DistRollCntAvgDrvn 1;
BA_ "SignalType" SG_ 2149646336 DistRollCntAvgDrvn "UNM";
BA_ "SignalLongName" SG_ 2149646336 DistRollCntAvgDrvn "Distance Rolling Count Average Driven";
BA_ "VNSigAllNodes" SG_ 2149646336 VehSpdAvgDrvnV 1;
BA_ "SignalType" SG_ 2149646336 VehSpdAvgDrvnV "ENM";
BA_ "SignalLongName" SG_ 2149646336 VehSpdAvgDrvnV "Vehicle Speed Average Driven Validity";
BA_ "VNSigAllNodes" SG_ 2149646336 VehSpdAvgDrvn 1;
BA_ "SignalType" SG_ 2149646336 VehSpdAvgDrvn "UNM";
BA_ "SignalLongName" SG_ 2149646336 VehSpdAvgDrvn "Vehicle Speed Average Driven";
BA_ "GenSigSendType" SG_ 2149851136 KylsStrtAuthRq 10;
BA_ "VNSigAllNodes" SG_ 2149851136 KylsStrtAuthRq 1;
BA_ "SignalType" SG_ 2149851136 KylsStrtAuthRq "BLN";
BA_ "SignalLongName" SG_ 2149851136 KylsStrtAuthRq "Keyless Start Authentication Requested";
BA_ "VNSigIntermediate" SG_ 2149851136 SysPwrMd 1;
BA_ "VNSigParkedVehicle" SG_ 2149851136 SysPwrMd 1;
BA_ "GenSigSendOnInit" SG_ 2149851136 SysPwrMd 2;
BA_ "GenSigSendType" SG_ 2149851136 SysPwrMd 10;
BA_ "VNSigAllNodes" SG_ 2149851136 SysPwrMd 1;
BA_ "SignalType" SG_ 2149851136 SysPwrMd "ENM";
BA_ "SignalLongName" SG_ 2149851136 SysPwrMd "System Power Mode";
BA_ "VNSigIntermediate" SG_ 2149851136 SysPwrMdV 1;
BA_ "VNSigParkedVehicle" SG_ 2149851136 SysPwrMdV 1;
BA_ "GenSigSendType" SG_ 2149851136 SysPwrMdV 10;
BA_ "VNSigAllNodes" SG_ 2149851136 SysPwrMdV 1;
BA_ "SignalType" SG_ 2149851136 SysPwrMdV "ENM";
BA_ "SignalLongName" SG_ 2149851136 SysPwrMdV "System Power Mode Validity";
BA_ "GenSigSendType" SG_ 2151718912 ChmVolSt 10;
BA_ "VNSigAllNodes" SG_ 2151718912 ChmVolSt 1;
BA_ "SignalType" SG_ 2151718912 ChmVolSt "ENM";
BA_ "SignalLongName" SG_ 2151718912 ChmVolSt "Chime Volume Status";
BA_ "VNSigIntermediate" SG_ 2151718912 ChmAct 1;
BA_ "GenSigSendOnInit" SG_ 2151718912 ChmAct 1;
BA_ "GenSigSendType" SG_ 2151718912 ChmAct 10;
BA_ "VNSigAllNodes" SG_ 2151718912 ChmAct 1;
BA_ "SignalType" SG_ 2151718912 ChmAct "BLN";
BA_ "SignalLongName" SG_ 2151718912 ChmAct "Chime Active";
BA_ "GenSigSendType" SG_ 2153775104 DTCI_DTCFaultType 10;
BA_ "VNSigAllNodes" SG_ 2153775104 DTCI_DTCFaultType 1;
BA_ "SignalType" SG_ 2153775104 DTCI_DTCFaultType "ENM";
BA_ "PacketOrder" SG_ 2153775104 DTCI_DTCFaultType 20;
BA_ "SignalLongName" SG_ 2153775104 DTCI_DTCFaultType "Diagnostic Trouble Code Information Extended : Diagnostic Trouble Code Fault Type";
BA_ "GenSigSendType" SG_ 2153775104 DTCI_CodeSupported 10;
BA_ "VNSigAllNodes" SG_ 2153775104 DTCI_CodeSupported 1;
BA_ "SignalType" SG_ 2153775104 DTCI_CodeSupported "BLN";
BA_ "PacketOrder" SG_ 2153775104 DTCI_CodeSupported 19;
BA_ "SignalLongName" SG_ 2153775104 DTCI_CodeSupported "Diagnostic Trouble Code Information Extended : Code Supported";
BA_ "GenSigSendType" SG_ 2153775104 DTCI_CurrentStatus 10;
BA_ "VNSigAllNodes" SG_ 2153775104 DTCI_CurrentStatus 1;
BA_ "SignalType" SG_ 2153775104 DTCI_CurrentStatus "BLN";
BA_ "PacketOrder" SG_ 2153775104 DTCI_CurrentStatus 18;
BA_ "SignalLongName" SG_ 2153775104 DTCI_CurrentStatus "Diagnostic Trouble Code Information Extended : Current Status";
BA_ "GenSigSendType" SG_ 2153775104 DTCI_TstNPsdCdClrdSt 10;
BA_ "VNSigAllNodes" SG_ 2153775104 DTCI_TstNPsdCdClrdSt 1;
BA_ "SignalType" SG_ 2153775104 DTCI_TstNPsdCdClrdSt "BLN";
BA_ "PacketOrder" SG_ 2153775104 DTCI_TstNPsdCdClrdSt 17;
BA_ "SignalLongName" SG_ 2153775104 DTCI_TstNPsdCdClrdSt "Diagnostic Trouble Code Information Extended : Test Not Passed Since Code Cleared Status";
BA_ "GenSigSendType" SG_ 2153775104 DTCI_TstFldCdClrdStat 10;
BA_ "VNSigAllNodes" SG_ 2153775104 DTCI_TstFldCdClrdStat 1;
BA_ "SignalType" SG_ 2153775104 DTCI_TstFldCdClrdStat "BLN";
BA_ "PacketOrder" SG_ 2153775104 DTCI_TstFldCdClrdStat 16;
BA_ "SignalLongName" SG_ 2153775104 DTCI_TstFldCdClrdStat "Diagnostic Trouble Code Information Extended : Test Failed Since Code Cleared Status";
BA_ "GenSigSendType" SG_ 2153775104 DTCI_HistStat 10;
BA_ "VNSigAllNodes" SG_ 2153775104 DTCI_HistStat 1;
BA_ "SignalType" SG_ 2153775104 DTCI_HistStat "BLN";
BA_ "PacketOrder" SG_ 2153775104 DTCI_HistStat 15;
BA_ "SignalLongName" SG_ 2153775104 DTCI_HistStat "Diagnostic Trouble Code Information Extended : History Status";
BA_ "GenSigSendType" SG_ 2153775104 DTCI_TstNPsdPwrUpSt 10;
BA_ "VNSigAllNodes" SG_ 2153775104 DTCI_TstNPsdPwrUpSt 1;
BA_ "SignalType" SG_ 2153775104 DTCI_TstNPsdPwrUpSt "BLN";
BA_ "PacketOrder" SG_ 2153775104 DTCI_TstNPsdPwrUpSt 14;
BA_ "SignalLongName" SG_ 2153775104 DTCI_TstNPsdPwrUpSt "Diagnostic Trouble Code Information Extended : Test Not Passed Since Power Up Status";
BA_ "GenSigSendType" SG_ 2153775104 DTCI_TstFldPwrUpSt 10;
BA_ "VNSigAllNodes" SG_ 2153775104 DTCI_TstFldPwrUpSt 1;
BA_ "SignalType" SG_ 2153775104 DTCI_TstFldPwrUpSt "BLN";
BA_ "PacketOrder" SG_ 2153775104 DTCI_TstFldPwrUpSt 13;
BA_ "SignalLongName" SG_ 2153775104 DTCI_TstFldPwrUpSt "Diagnostic Trouble Code Information Extended : Test Failed Since Power Up Status";
BA_ "GenSigSendType" SG_ 2153775104 DTCI_WrnIndRqdSt 10;
BA_ "VNSigAllNodes" SG_ 2153775104 DTCI_WrnIndRqdSt 1;
BA_ "SignalType" SG_ 2153775104 DTCI_WrnIndRqdSt "BLN";
BA_ "PacketOrder" SG_ 2153775104 DTCI_WrnIndRqdSt 12;
BA_ "SignalLongName" SG_ 2153775104 DTCI_WrnIndRqdSt "Diagnostic Trouble Code Information Extended : Warning Indicator Requested Status";
BA_ "GenSigSendType" SG_ 2153775104 DTCI_DTCFailType 12;
BA_ "GenSigDeltaValue" SG_ 2153775104 DTCI_DTCFailType 1;
BA_ "VNSigAllNodes" SG_ 2153775104 DTCI_DTCFailType 1;
BA_ "SignalType" SG_ 2153775104 DTCI_DTCFailType "UNM";
BA_ "PacketOrder" SG_ 2153775104 DTCI_DTCFailType 11;
BA_ "SignalLongName" SG_ 2153775104 DTCI_DTCFailType "Diagnostic Trouble Code Information Extended : Diagnostic Trouble Code Failure Type";
BA_ "GenSigSendType" SG_ 2153775104 DTCI_DTCNumber 12;
BA_ "GenSigDeltaValue" SG_ 2153775104 DTCI_DTCNumber 1;
BA_ "VNSigAllNodes" SG_ 2153775104 DTCI_DTCNumber 1;
BA_ "SignalType" SG_ 2153775104 DTCI_DTCNumber "UNM";
BA_ "PacketOrder" SG_ 2153775104 DTCI_DTCNumber 10;
BA_ "SignalLongName" SG_ 2153775104 DTCI_DTCNumber "Diagnostic Trouble Code Information Extended : Diagnostic Trouble Code Number";
BA_ "GenSigSendType" SG_ 2153775104 DTCI_DTCSource 12;
BA_ "GenSigDeltaValue" SG_ 2153775104 DTCI_DTCSource 1;
BA_ "VNSigAllNodes" SG_ 2153775104 DTCI_DTCSource 1;
BA_ "SignalType" SG_ 2153775104 DTCI_DTCSource "UNM";
BA_ "PacketOrder" SG_ 2153775104 DTCI_DTCSource 9;
BA_ "SignalLongName" SG_ 2153775104 DTCI_DTCSource "Diagnostic Trouble Code Information Extended : Diagnostic Trouble Code Source";
BA_ "GenSigSendType" SG_ 2153775104 DTCI_DTCTriggered 10;
BA_ "VNSigAllNodes" SG_ 2153775104 DTCI_DTCTriggered 1;
BA_ "SignalType" SG_ 2153775104 DTCI_DTCTriggered "BLN";
BA_ "PacketOrder" SG_ 2153775104 DTCI_DTCTriggered 8;
BA_ "SignalLongName" SG_ 2153775104 DTCI_DTCTriggered "Diagnostic Trouble Code Information Extended : Diagnostic Trouble Code Triggered";
BA_ "GenSigSendType" SG_ 2153775104 DTCIUnused7 10;
BA_ "VNSigAllNodes" SG_ 2153775104 DTCIUnused7 1;
BA_ "SignalType" SG_ 2153775104 DTCIUnused7 "BLN";
BA_ "PacketOrder" SG_ 2153775104 DTCIUnused7 1;
BA_ "SignalLongName" SG_ 2153775104 DTCIUnused7 "Diagnostic Trouble Code Information Extended : Unused 7";
BA_ "GenSigSendType" SG_ 2153775104 DTCIUnused6 10;
BA_ "VNSigAllNodes" SG_ 2153775104 DTCIUnused6 1;
BA_ "SignalType" SG_ 2153775104 DTCIUnused6 "BLN";
BA_ "PacketOrder" SG_ 2153775104 DTCIUnused6 2;
BA_ "SignalLongName" SG_ 2153775104 DTCIUnused6 "Diagnostic Trouble Code Information Extended : Unused 6";
BA_ "GenSigSendType" SG_ 2153775104 DTCIUnused5 10;
BA_ "VNSigAllNodes" SG_ 2153775104 DTCIUnused5 1;
BA_ "SignalType" SG_ 2153775104 DTCIUnused5 "BLN";
BA_ "PacketOrder" SG_ 2153775104 DTCIUnused5 3;
BA_ "SignalLongName" SG_ 2153775104 DTCIUnused5 "Diagnostic Trouble Code Information Extended : Unused 5";
BA_ "GenSigSendType" SG_ 2153775104 DTCIUnused4 10;
BA_ "VNSigAllNodes" SG_ 2153775104 DTCIUnused4 1;
BA_ "SignalType" SG_ 2153775104 DTCIUnused4 "BLN";
BA_ "PacketOrder" SG_ 2153775104 DTCIUnused4 4;
BA_ "SignalLongName" SG_ 2153775104 DTCIUnused4 "Diagnostic Trouble Code Information Extended : Unused 4";
BA_ "GenSigSendType" SG_ 2153775104 DTCIUnused3 10;
BA_ "VNSigAllNodes" SG_ 2153775104 DTCIUnused3 1;
BA_ "SignalType" SG_ 2153775104 DTCIUnused3 "BLN";
BA_ "PacketOrder" SG_ 2153775104 DTCIUnused3 5;
BA_ "SignalLongName" SG_ 2153775104 DTCIUnused3 "Diagnostic Trouble Code Information Extended : Unused 3";
BA_ "GenSigSendType" SG_ 2153775104 DTCIUnused2 10;
BA_ "VNSigAllNodes" SG_ 2153775104 DTCIUnused2 1;
BA_ "SignalType" SG_ 2153775104 DTCIUnused2 "BLN";
BA_ "PacketOrder" SG_ 2153775104 DTCIUnused2 6;
BA_ "SignalLongName" SG_ 2153775104 DTCIUnused2 "Diagnostic Trouble Code Information Extended : Unused 2";
BA_ "GenSigSendType" SG_ 2153775104 DTCIUnused1 10;
BA_ "VNSigAllNodes" SG_ 2153775104 DTCIUnused1 1;
BA_ "SignalType" SG_ 2153775104 DTCIUnused1 "BLN";
BA_ "PacketOrder" SG_ 2153775104 DTCIUnused1 7;
BA_ "SignalLongName" SG_ 2153775104 DTCIUnused1 "Diagnostic Trouble Code Information Extended : Unused 1";
BA_ "VNSigDiagnostic" SG_ 1364 DgnInf_LS554 1;
BA_ "GenSigSendType" SG_ 1364 DgnInf_LS554 12;
BA_ "GenSigDeltaValue" SG_ 1364 DgnInf_LS554 1;
BA_ "VNSigAllNodes" SG_ 1364 DgnInf_LS554 1;
BA_ "SignalType" SG_ 1364 DgnInf_LS554 "UNM";
BA_ "SignalLongName" SG_ 1364 DgnInf_LS554 "Diagnostic Information LS554";
BA_ "VNSigDiagnostic" SG_ 1588 VectraSpcNWMgtD 1;
BA_ "VNSigUnused_4" SG_ 1588 VectraSpcNWMgtD 1;
BA_ "VNSigIntermediate" SG_ 1588 VectraSpcNWMgtD 1;
BA_ "VNSigParkedVehicle" SG_ 1588 VectraSpcNWMgtD 1;
BA_ "VNSigRemoteDiagnostics" SG_ 1588 VectraSpcNWMgtD 1;
BA_ "VNSigAllNodes" SG_ 1588 VectraSpcNWMgtD 1;
BA_ "SignalType" SG_ 1588 VectraSpcNWMgtD "UNM";
BA_ "SignalLongName" SG_ 1588 VectraSpcNWMgtD "Vectra Specific Network Management Data";
BA_ "VNSigDiagnostic" SG_ 1594 VectraSpcNWMgtD 1;
BA_ "VNSigUnused_4" SG_ 1594 VectraSpcNWMgtD 1;
BA_ "VNSigIntermediate" SG_ 1594 VectraSpcNWMgtD 1;
BA_ "VNSigParkedVehicle" SG_ 1594 VectraSpcNWMgtD 1;
BA_ "VNSigRemoteDiagnostics" SG_ 1594 VectraSpcNWMgtD 1;
BA_ "VNSigAllNodes" SG_ 1594 VectraSpcNWMgtD 1;
BA_ "SignalType" SG_ 1594 VectraSpcNWMgtD "UNM";
BA_ "SignalLongName" SG_ 1594 VectraSpcNWMgtD "Vectra Specific Network Management Data";
BA_ "VNSigDiagnostic" SG_ 1370 DgnInf_LS55A 1;
BA_ "VNSigAllNodes" SG_ 1370 DgnInf_LS55A 1;
BA_ "SignalType" SG_ 1370 DgnInf_LS55A "UNM";
BA_ "SignalLongName" SG_ 1370 DgnInf_LS55A "Diagnostic Information LS55A";
BA_ "VNSigDiagnostic" SG_ 872 DgnInf 1;
BA_ "GenSigSendType" SG_ 872 DgnInf 12;
BA_ "GenSigDeltaValue" SG_ 872 DgnInf 1;
BA_ "VNSigAllNodes" SG_ 872 DgnInf 1;
BA_ "SignalType" SG_ 872 DgnInf "UNM";
BA_ "SignalLongName" SG_ 872 DgnInf "Diagnostic Information";
BA_ "VNSigDiagnostic" SG_ 1626 DgnInf 1;
BA_ "GenSigSendType" SG_ 1626 DgnInf 12;
BA_ "GenSigDeltaValue" SG_ 1626 DgnInf 1;
BA_ "VNSigAllNodes" SG_ 1626 DgnInf 1;
BA_ "SignalType" SG_ 1626 DgnInf "UNM";
BA_ "SignalLongName" SG_ 1626 DgnInf "Diagnostic Information";
BA_ "VNSigDiagnostic" SG_ 1583 VectraSpcNWMgtD 1;
BA_ "VNSigUnused_4" SG_ 1583 VectraSpcNWMgtD 1;
BA_ "VNSigIntermediate" SG_ 1583 VectraSpcNWMgtD 1;
BA_ "VNSigParkedVehicle" SG_ 1583 VectraSpcNWMgtD 1;
BA_ "VNSigRemoteDiagnostics" SG_ 1583 VectraSpcNWMgtD 1;
BA_ "VNSigAllNodes" SG_ 1583 VectraSpcNWMgtD 1;
BA_ "SignalType" SG_ 1583 VectraSpcNWMgtD "UNM";
BA_ "SignalLongName" SG_ 1583 VectraSpcNWMgtD "Vectra Specific Network Management Data";
BA_ "VNSigDiagnostic" SG_ 1615 DgnInf 1;
BA_ "GenSigSendType" SG_ 1615 DgnInf 12;
BA_ "GenSigDeltaValue" SG_ 1615 DgnInf 1;
BA_ "VNSigAllNodes" SG_ 1615 DgnInf 1;
BA_ "SignalType" SG_ 1615 DgnInf "UNM";
BA_ "SignalLongName" SG_ 1615 DgnInf "Diagnostic Information";
BA_ "VNSigDiagnostic" SG_ 1359 DgnInf_LS54F 1;
BA_ "VNSigAllNodes" SG_ 1359 DgnInf_LS54F 1;
BA_ "SignalType" SG_ 1359 DgnInf_LS54F "UNM";
BA_ "SignalLongName" SG_ 1359 DgnInf_LS54F "Diagnostic Information LS54F";
BA_REL_ "GenSigSuprvResp" BU_SG_REL_ SBZA_R_LS SG_ 2151284736 PrkAstOprtrDsrdStat_1D0 1;
BA_REL_ "GenSigSuprvResp" BU_SG_REL_ SBZA_L_LS SG_ 2151284736 PrkAstOprtrDsrdStat_1D0 1;
BA_REL_ "GenSigSuprvResp" BU_SG_REL_ EOCM_F_LS SG_ 2151301120 PrkAstAdvSysAct 1;
BA_REL_ "GenSigSuprvResp" BU_SG_REL_ BCM_LS SG_ 2151301120 PrkAstAdvSysAct 1;
BA_REL_ "GenSigSuprvResp" BU_SG_REL_ VIS2_LS SG_ 2155003904 LftLnChgThrt 1;
BA_REL_ "GenSigSuprvResp" BU_SG_REL_ EOCM_F_LS SG_ 2155003904 LftLnChgThrt 1;
BA_REL_ "GenSigSuprvResp" BU_SG_REL_ EOCM_F_LS SG_ 2150850560 DrSbltAtc 1;
BA_REL_ "GenSigSuprvResp" BU_SG_REL_ ECC_LS SG_ 2150850560 PsSbltAtc 1;
BA_REL_ "GenSigSuprvResp" BU_SG_REL_ AOS_LS SG_ 2150850560 PsSbltAtc 1;
BA_REL_ "GenSigVBitResp" BU_SG_REL_ AOS_LS SG_ 2150850560 PsSbltAtc 1;
BA_REL_ "GenSigSuprvResp" BU_SG_REL_ SBZA_R_LS SG_ 2151735296 RtSdDetSysServDsbld 1;
BA_REL_ "GenSigSuprvResp" BU_SG_REL_ SBZA_R_LS SG_ 2151735296 RtSdDetSysTmpDsbld 1;
BA_REL_ "GenSigSuprvResp" BU_SG_REL_ SBZA_R_LS SG_ 2151735296 RtLnChgAlrtEnbld 1;
BA_REL_ "GenSigSuprvResp" BU_SG_REL_ SBZA_R_LS SG_ 2151735296 RtSBZAlrtEnbld 1;
BA_REL_ "GenSigSuprvResp" BU_SG_REL_ SBZA_R_LS SG_ 2151735296 RtRrCrsTrfcAlrtEnbld 1;
BA_REL_ "GenSigSuprvResp" BU_SG_REL_ SBZA_R_LS SG_ 2151735296 LnChgAlrtOffIndOn 1;
BA_REL_ "GenSigSuprvResp" BU_SG_REL_ SBZA_R_LS SG_ 2151735296 RrCrsTrfcAlrtOffIO 1;
BA_REL_ "GenSigSuprvResp" BU_SG_REL_ CGM_LS SG_ 2150776832 HybImpSnsDsbld 1;
BA_REL_ "GenSigSuprvResp" BU_SG_REL_ BSM_LS SG_ 2150776832 HybImpSnsDsbld 1;
BA_REL_ "GenSigSuprvResp" BU_SG_REL_ BCM_LS SG_ 2150776832 HybImpSnsDsbld 1;
BA_REL_ "GenSigSuprvResp" BU_SG_REL_ MSM_LS SG_ 2150776832 MmryRclImpctDisRq 1;
BA_REL_ "GenSigSuprvResp" BU_SG_REL_ EOCM_F_LS SG_ 2150776832 SIREvntSychCntr 1;
BA_REL_ "GenSigSuprvResp" BU_SG_REL_ EOCM_F_LS SG_ 2150760448 NotEventStat 1;
BA_REL_ "GenSigSuprvResp" BU_SG_REL_ PTM_LS SG_ 2150760448 SIRDpl 1;
BA_REL_ "GenSigSuprvResp" BU_SG_REL_ PEPS_LS SG_ 2150760448 SIRDpl 1;
BA_REL_ "GenSigSuprvResp" BU_SG_REL_ EOCM_F_LS SG_ 2150760448 SIRDpl 1;
BA_REL_ "GenSigSuprvResp" BU_SG_REL_ ECC_LS SG_ 2150760448 SIRDpl 1;
BA_REL_ "GenSigSuprvResp" BU_SG_REL_ BCM_LS SG_ 2150760448 SIRDpl 1;
BA_REL_ "GenSigSuprvResp" BU_SG_REL_ EOCM_F_LS SG_ 2150760448 NotiEventCount 1;
BA_REL_ "GenSigSuprvResp" BU_SG_REL_ EOCM_F_LS SG_ 2150760448 NESSRoSevSt 1;
BA_REL_ "GenSigSuprvResp" BU_SG_REL_ EOCM_F_LS SG_ 2150760448 NESSRiSiSevSt 1;
BA_REL_ "GenSigSuprvResp" BU_SG_REL_ EOCM_F_LS SG_ 2150760448 NESSReImpSevSt 1;
BA_REL_ "GenSigSuprvResp" BU_SG_REL_ EOCM_F_LS SG_ 2150760448 NESSLeSiSevSt 1;
BA_REL_ "GenSigSuprvResp" BU_SG_REL_ EOCM_F_LS SG_ 2150760448 NESSFrImpSt2SevSt 1;
BA_REL_ "GenSigSuprvResp" BU_SG_REL_ EOCM_F_LS SG_ 2150760448 NESSFrImpSt1SevSt 1;
BA_REL_ "GenSigSuprvResp" BU_SG_REL_ EOCM_F_LS SG_ 2150760448 NESSFrImpPreSevSt 1;
BA_REL_ "GenSigSuprvResp" BU_SG_REL_ SDM_LS SG_ 2151112704 FrPasSeatbltRemOccSt 1;
BA_REL_ "GenSigSuprvResp" BU_SG_REL_ BCM_LS SG_ 2151112704 FrPasSeatbltRemOccSt 1;
BA_REL_ "GenSigSuprvResp" BU_SG_REL_ SDM_LS SG_ 2151112704 FrPasSeatResCtrlOccStV 1;
BA_REL_ "GenSigSuprvResp" BU_SG_REL_ SDM_LS SG_ 2151112704 FrPasSeatResCtrlOccSt 1;
BA_REL_ "GenSigVBitResp" BU_SG_REL_ SDM_LS SG_ 2151112704 FrPasSeatResCtrlOccSt 1;
BA_REL_ "GenSigSuprvResp" BU_SG_REL_ SDM_LS SG_ 2151112704 FrPsSeatOccSnsOpMd 1;
BA_REL_ "GenSigSuprvResp" BU_SG_REL_ SDM_LS SG_ 2151112704 FrPsSeatOccFltSt 1;
BA_REL_ "GenSigSuprvResp" BU_SG_REL_ MSM_LS SG_ 2151112704 FrPsSeatOccFltSt 1;
BA_REL_ "GenSigSuprvResp" BU_SG_REL_ SDM_LS SG_ 2151112704 FrntPassClass 1;
BA_REL_ "GenSigSuprvResp" BU_SG_REL_ MSM_LS SG_ 2151112704 FrntPassClass 1;
BA_REL_ "GenSigSuprvResp" BU_SG_REL_ PEPS_LS SG_ 2154471424 RrClosAjarSwAct 2;
BA_REL_ "GenSigSuprvResp" BU_SG_REL_ ECC_LS SG_ 2154471424 RrClosAjarSwAct 2;
BA_REL_ "GenSigSuprvResp" BU_SG_REL_ BCM_LS SG_ 2154471424 RrClosAjarSwAct 1;
BA_REL_ "GenSigSuprvResp" BU_SG_REL_ PTM_LS SG_ 2151063552 ValetMdAct 1;
BA_REL_ "GenSigSuprvResp" BU_SG_REL_ BCM_LS SG_ 2151063552 ValetMdAct 1;
BA_REL_ "GenSigSuprvResp" BU_SG_REL_ PTM_LS SG_ 2151063552 InftnOprAlwd 1;
BA_REL_ "GenSigSuprvResp" BU_SG_REL_ BCM_LS SG_ 2151063552 InftnOprAlwd 1;
BA_REL_ "GenSigSuprvResp" BU_SG_REL_ UPA_LS SG_ 2155167744 VehMovState 1;
BA_REL_ "GenSigSuprvResp" BU_SG_REL_ VIS2_LS SG_ 2155167744 VehMovState 1;
BA_REL_ "GenSigSuprvResp" BU_SG_REL_ PEPS_LS SG_ 2155167744 VehMovState 1;
BA_REL_ "GenSigSuprvResp" BU_SG_REL_ MSM_LS SG_ 2155167744 VehMovState 1;
BA_REL_ "GenSigRxStartValue" BU_SG_REL_ SBZA_R_LS SG_ 2149859328 SysBkUpPwrMdV "1";
BA_REL_ "GenSigRxStartValue" BU_SG_REL_ SBZA_L_LS SG_ 2149859328 SysBkUpPwrMdV "1";
BA_REL_ "GenSigRxStartValue" BU_SG_REL_ UPA_LS SG_ 2149859328 SysBkUpPwrMdV "1";
BA_REL_ "GenSigRxStartValue" BU_SG_REL_ PTM_LS SG_ 2149859328 SysBkUpPwrMdV "1";
BA_REL_ "GenSigRxStartValue" BU_SG_REL_ PEPS_LS SG_ 2149859328 SysBkUpPwrMdV "1";
BA_REL_ "GenSigRxStartValue" BU_SG_REL_ VIS2_LS SG_ 2149859328 SysBkUpPwrMdV "1";
BA_REL_ "GenSigRxStartValue" BU_SG_REL_ SDM_LS SG_ 2149859328 SysBkUpPwrMdV "1";
BA_REL_ "GenSigRxStartValue" BU_SG_REL_ MSM_LS SG_ 2149859328 SysBkUpPwrMdV "1";
BA_REL_ "GenSigRxStartValue" BU_SG_REL_ HFP_LS SG_ 2149859328 SysBkUpPwrMdV "1";
BA_REL_ "GenSigRxStartValue" BU_SG_REL_ DCAC_LS SG_ 2149859328 SysBkUpPwrMdV "1";
BA_REL_ "GenSigRxStartValue" BU_SG_REL_ ECC_LS SG_ 2149859328 SysBkUpPwrMdV "1";
BA_REL_ "GenSigRxStartValue" BU_SG_REL_ AOS_LS SG_ 2149859328 SysBkUpPwrMdV "1";
BA_REL_ "GenSigSuprvResp" BU_SG_REL_ SBZA_R_LS SG_ 2149859328 SysBkupPwrMdEn 1;
BA_REL_ "GenSigRxStartValue" BU_SG_REL_ SBZA_R_LS SG_ 2149859328 SysBkupPwrMdEn "0";
BA_REL_ "GenSigSuprvResp" BU_SG_REL_ UPA_LS SG_ 2149859328 SysBkupPwrMdEn 1;
BA_REL_ "GenSigRxStartValue" BU_SG_REL_ UPA_LS SG_ 2149859328 SysBkupPwrMdEn "0";
BA_REL_ "GenSigSuprvResp" BU_SG_REL_ PTM_LS SG_ 2149859328 SysBkupPwrMdEn 1;
BA_REL_ "GenSigRxStartValue" BU_SG_REL_ PTM_LS SG_ 2149859328 SysBkupPwrMdEn "0";
BA_REL_ "GenSigSuprvResp" BU_SG_REL_ PEPS_LS SG_ 2149859328 SysBkupPwrMdEn 1;
BA_REL_ "GenSigRxStartValue" BU_SG_REL_ PEPS_LS SG_ 2149859328 SysBkupPwrMdEn "0";
BA_REL_ "GenSigSuprvResp" BU_SG_REL_ VIS2_LS SG_ 2149859328 SysBkupPwrMdEn 1;
BA_REL_ "GenSigRxStartValue" BU_SG_REL_ VIS2_LS SG_ 2149859328 SysBkupPwrMdEn "0";
BA_REL_ "GenSigSuprvResp" BU_SG_REL_ SDM_LS SG_ 2149859328 SysBkupPwrMdEn 1;
BA_REL_ "GenSigRxStartValue" BU_SG_REL_ SDM_LS SG_ 2149859328 SysBkupPwrMdEn "0";
BA_REL_ "GenSigSuprvResp" BU_SG_REL_ MSM_LS SG_ 2149859328 SysBkupPwrMdEn 1;
BA_REL_ "GenSigRxStartValue" BU_SG_REL_ MSM_LS SG_ 2149859328 SysBkupPwrMdEn "0";
BA_REL_ "GenSigSuprvResp" BU_SG_REL_ HFP_LS SG_ 2149859328 SysBkupPwrMdEn 1;
BA_REL_ "GenSigRxStartValue" BU_SG_REL_ HFP_LS SG_ 2149859328 SysBkupPwrMdEn "0";
BA_REL_ "GenSigSuprvResp" BU_SG_REL_ SBZA_L_LS SG_ 2149859328 SysBkupPwrMdEn 1;
BA_REL_ "GenSigRxStartValue" BU_SG_REL_ SBZA_L_LS SG_ 2149859328 SysBkupPwrMdEn "0";
BA_REL_ "GenSigSuprvResp" BU_SG_REL_ DCAC_LS SG_ 2149859328 SysBkupPwrMdEn 1;
BA_REL_ "GenSigRxStartValue" BU_SG_REL_ DCAC_LS SG_ 2149859328 SysBkupPwrMdEn "0";
BA_REL_ "GenSigSuprvResp" BU_SG_REL_ ECC_LS SG_ 2149859328 SysBkupPwrMdEn 1;
BA_REL_ "GenSigRxStartValue" BU_SG_REL_ ECC_LS SG_ 2149859328 SysBkupPwrMdEn "0";
BA_REL_ "GenSigSuprvResp" BU_SG_REL_ BSM_LS SG_ 2149859328 SysBkupPwrMdEn 1;
BA_REL_ "GenSigSuprvResp" BU_SG_REL_ BCM_LS SG_ 2149859328 SysBkupPwrMdEn 1;
BA_REL_ "GenSigSuprvResp" BU_SG_REL_ AOS_LS SG_ 2149859328 SysBkupPwrMdEn 1;
BA_REL_ "GenSigRxStartValue" BU_SG_REL_ AOS_LS SG_ 2149859328 SysBkupPwrMdEn "0";
BA_REL_ "GenSigSuprvResp" BU_SG_REL_ SBZA_R_LS SG_ 2149859328 SysBkUpPwrMd 1;
BA_REL_ "GenSigVBitResp" BU_SG_REL_ SBZA_R_LS SG_ 2149859328 SysBkUpPwrMd 1;
BA_REL_ "GenSigSuprvResp" BU_SG_REL_ UPA_LS SG_ 2149859328 SysBkUpPwrMd 1;
BA_REL_ "GenSigVBitResp" BU_SG_REL_ UPA_LS SG_ 2149859328 SysBkUpPwrMd 1;
BA_REL_ "GenSigSuprvResp" BU_SG_REL_ PTM_LS SG_ 2149859328 SysBkUpPwrMd 1;
BA_REL_ "GenSigVBitResp" BU_SG_REL_ PTM_LS SG_ 2149859328 SysBkUpPwrMd 1;
BA_REL_ "GenSigSuprvResp" BU_SG_REL_ PEPS_LS SG_ 2149859328 SysBkUpPwrMd 1;
BA_REL_ "GenSigVBitResp" BU_SG_REL_ PEPS_LS SG_ 2149859328 SysBkUpPwrMd 1;
BA_REL_ "GenSigSuprvResp" BU_SG_REL_ VIS2_LS SG_ 2149859328 SysBkUpPwrMd 1;
BA_REL_ "GenSigVBitResp" BU_SG_REL_ VIS2_LS SG_ 2149859328 SysBkUpPwrMd 1;
BA_REL_ "GenSigSuprvResp" BU_SG_REL_ SDM_LS SG_ 2149859328 SysBkUpPwrMd 1;
BA_REL_ "GenSigVBitResp" BU_SG_REL_ SDM_LS SG_ 2149859328 SysBkUpPwrMd 1;
BA_REL_ "GenSigSuprvResp" BU_SG_REL_ MSM_LS SG_ 2149859328 SysBkUpPwrMd 1;
BA_REL_ "GenSigVBitResp" BU_SG_REL_ MSM_LS SG_ 2149859328 SysBkUpPwrMd 1;
BA_REL_ "GenSigSuprvResp" BU_SG_REL_ HFP_LS SG_ 2149859328 SysBkUpPwrMd 1;
BA_REL_ "GenSigVBitResp" BU_SG_REL_ HFP_LS SG_ 2149859328 SysBkUpPwrMd 1;
BA_REL_ "GenSigSuprvResp" BU_SG_REL_ SBZA_L_LS SG_ 2149859328 SysBkUpPwrMd 1;
BA_REL_ "GenSigVBitResp" BU_SG_REL_ SBZA_L_LS SG_ 2149859328 SysBkUpPwrMd 1;
BA_REL_ "GenSigSuprvResp" BU_SG_REL_ DCAC_LS SG_ 2149859328 SysBkUpPwrMd 1;
BA_REL_ "GenSigVBitResp" BU_SG_REL_ DCAC_LS SG_ 2149859328 SysBkUpPwrMd 1;
BA_REL_ "GenSigSuprvResp" BU_SG_REL_ ECC_LS SG_ 2149859328 SysBkUpPwrMd 1;
BA_REL_ "GenSigVBitResp" BU_SG_REL_ ECC_LS SG_ 2149859328 SysBkUpPwrMd 1;
BA_REL_ "GenSigSuprvResp" BU_SG_REL_ BSM_LS SG_ 2149859328 SysBkUpPwrMd 1;
BA_REL_ "GenSigSuprvResp" BU_SG_REL_ BCM_LS SG_ 2149859328 SysBkUpPwrMd 1;
BA_REL_ "GenSigVBitResp" BU_SG_REL_ BCM_LS SG_ 2149859328 SysBkUpPwrMd 1;
BA_REL_ "GenSigSuprvResp" BU_SG_REL_ AOS_LS SG_ 2149859328 SysBkUpPwrMd 1;
BA_REL_ "GenSigVBitResp" BU_SG_REL_ AOS_LS SG_ 2149859328 SysBkUpPwrMd 1;
BA_REL_ "GenSigSuprvResp" BU_SG_REL_ PTM_LS SG_ 2150604800 RRDoorAjarSwAct 1;
BA_REL_ "GenSigSuprvResp" BU_SG_REL_ PEPS_LS SG_ 2150604800 RRDoorAjarSwAct 2;
BA_REL_ "GenSigSuprvResp" BU_SG_REL_ SDM_LS SG_ 2150604800 RRDoorAjarSwAct 1;
BA_REL_ "GenSigRxStartValue" BU_SG_REL_ SDM_LS SG_ 2150604800 RRDoorAjarSwAct "0";
BA_REL_ "GenSigSuprvResp" BU_SG_REL_ ECC_LS SG_ 2150604800 RRDoorAjarSwAct 1;
BA_REL_ "GenSigSuprvResp" BU_SG_REL_ PTM_LS SG_ 2150588416 PDAjrSwAtv 1;
BA_REL_ "GenSigSuprvResp" BU_SG_REL_ PEPS_LS SG_ 2150588416 PDAjrSwAtv 2;
BA_REL_ "GenSigSuprvResp" BU_SG_REL_ SDM_LS SG_ 2150588416 PDAjrSwAtv 1;
BA_REL_ "GenSigRxStartValue" BU_SG_REL_ SDM_LS SG_ 2150588416 PDAjrSwAtv "0";
BA_REL_ "GenSigSuprvResp" BU_SG_REL_ ECC_LS SG_ 2150588416 PDAjrSwAtv 1;
BA_REL_ "GenSigSuprvResp" BU_SG_REL_ PEPS_LS SG_ 2150596608 RLDoorAjarSwAct 2;
BA_REL_ "GenSigSuprvResp" BU_SG_REL_ SDM_LS SG_ 2150596608 RLDoorAjarSwAct 1;
BA_REL_ "GenSigRxStartValue" BU_SG_REL_ SDM_LS SG_ 2150596608 RLDoorAjarSwAct "0";
BA_REL_ "GenSigSuprvResp" BU_SG_REL_ ECC_LS SG_ 2150596608 RLDoorAjarSwAct 1;
BA_REL_ "GenSigSuprvResp" BU_SG_REL_ PTM_LS SG_ 2150596608 RLDoorAjarSwAct 1;
BA_REL_ "GenSigVDAFailResp" BU_SG_REL_ SDM_LS SG_ 2150416384 EngTrqActExtRngV 1;
BA_REL_ "GenSigVDAFailComment" BU_SG_REL_ SDM_LS SG_ 2150416384 EngTrqActExtRngV "Engine Virtual Device Availability";
BA_REL_ "GenSigSuprvResp" BU_SG_REL_ SDM_LS SG_ 2150416384 EngTrqActExtRng 1;
BA_REL_ "GenSigVDAFailResp" BU_SG_REL_ SDM_LS SG_ 2150416384 EngTrqActExtRng 1;
BA_REL_ "GenSigVDAFailComment" BU_SG_REL_ SDM_LS SG_ 2150416384 EngTrqActExtRng "Engine Virtual Device Availability";
BA_REL_ "GenSigVBitResp" BU_SG_REL_ SDM_LS SG_ 2150416384 EngTrqActExtRng 1;
BA_REL_ "GenSigSuprvResp" BU_SG_REL_ SDM_LS SG_ 2150416384 EngSpdStat 1;
BA_REL_ "GenSigVDAFailResp" BU_SG_REL_ SDM_LS SG_ 2150416384 EngSpdStat 1;
BA_REL_ "GenSigVDAFailComment" BU_SG_REL_ SDM_LS SG_ 2150416384 EngSpdStat "EngVDA";
BA_REL_ "GenSigSuprvResp" BU_SG_REL_ SDM_LS SG_ 2150416384 TrnsVDA 1;
BA_REL_ "GenSigRxStartValue" BU_SG_REL_ SDM_LS SG_ 2150416384 TrnsVDA "1";
BA_REL_ "GenSigSuprvResp" BU_SG_REL_ UPA_LS SG_ 2150416384 TransEstGear 1;
BA_REL_ "GenSigSuprvResp" BU_SG_REL_ SDM_LS SG_ 2150416384 TransEstGear 1;
BA_REL_ "GenSigSuprvResp" BU_SG_REL_ PTM_LS SG_ 2150416384 TransEstGear 1;
BA_REL_ "GenSigVDAFailResp" BU_SG_REL_ PTM_LS SG_ 2150416384 TransEstGear 1;
BA_REL_ "GenSigVDAFailComment" BU_SG_REL_ PTM_LS SG_ 2150416384 TransEstGear "Transmission Virtual Device Availability";
BA_REL_ "GenSigSuprvResp" BU_SG_REL_ SDM_LS SG_ 2150416384 EngVDA 1;
BA_REL_ "GenSigRxStartValue" BU_SG_REL_ SDM_LS SG_ 2150416384 EngVDA "1";
BA_REL_ "GenSigSuprvResp" BU_SG_REL_ UPA_LS SG_ 2150416384 EngRunAtv 1;
BA_REL_ "GenSigSuprvResp" BU_SG_REL_ SDM_LS SG_ 2150416384 EngRunAtv 1;
BA_REL_ "GenSigVDAFailResp" BU_SG_REL_ SDM_LS SG_ 2150416384 EngRunAtv 1;
BA_REL_ "GenSigVDAFailComment" BU_SG_REL_ SDM_LS SG_ 2150416384 EngRunAtv "Engine Virtual Device Availability";
BA_REL_ "GenSigSuprvResp" BU_SG_REL_ MSM_LS SG_ 2150416384 EngRunAtv 1;
BA_REL_ "GenSigSuprvResp" BU_SG_REL_ DCAC_LS SG_ 2150416384 EngRunAtv 1;
BA_REL_ "GenSigSuprvResp" BU_SG_REL_ ECC_LS SG_ 2150416384 EngRunAtv 1;
BA_REL_ "GenSigSuprvResp" BU_SG_REL_ DCAC_LS SG_ 2150408192 EngRunng 1;
BA_REL_ "GenSigSuprvResp" BU_SG_REL_ DCAC_LS SG_ 2150408192 Eng12vStrtrMtrCmmdOn 1;
BA_REL_ "GenSigSuprvResp" BU_SG_REL_ VIS2_LS SG_ 2150408192 CrsCntEnbld 1;
BA_REL_ "GenSigVDAFailResp" BU_SG_REL_ SDM_LS SG_ 2150408192 AccActPosV 1;
BA_REL_ "GenSigVDAFailComment" BU_SG_REL_ SDM_LS SG_ 2150408192 AccActPosV "Engine Virtual Device Availability";
BA_REL_ "GenSigSuprvResp" BU_SG_REL_ SDM_LS SG_ 2150408192 AccActPos 1;
BA_REL_ "GenSigVDAFailResp" BU_SG_REL_ SDM_LS SG_ 2150408192 AccActPos 1;
BA_REL_ "GenSigVDAFailComment" BU_SG_REL_ SDM_LS SG_ 2150408192 AccActPos "Engine Virtual Device Availability";
BA_REL_ "GenSigVBitResp" BU_SG_REL_ SDM_LS SG_ 2150408192 AccActPos 1;
BA_REL_ "GenSigRxStartValue" BU_SG_REL_ SDM_LS SG_ 2150408192 ThrPosV "0";
BA_REL_ "GenSigVDAFailResp" BU_SG_REL_ SDM_LS SG_ 2150408192 ThrPosV 1;
BA_REL_ "GenSigVDAFailComment" BU_SG_REL_ SDM_LS SG_ 2150408192 ThrPosV "Engine Virtual Device Availability";
BA_REL_ "GenSigSuprvResp" BU_SG_REL_ SDM_LS SG_ 2150408192 ThrPos 1;
BA_REL_ "GenSigVDAFailResp" BU_SG_REL_ SDM_LS SG_ 2150408192 ThrPos 1;
BA_REL_ "GenSigVDAFailComment" BU_SG_REL_ SDM_LS SG_ 2150408192 ThrPos "Engine Virtual Device Availability";
BA_REL_ "GenSigVBitResp" BU_SG_REL_ SDM_LS SG_ 2150408192 ThrPos 1;
BA_REL_ "GenSigSuprvResp" BU_SG_REL_ UPA_LS SG_ 2150408192 TrnsShftLvrPos 1;
BA_REL_ "GenSigVDAFailResp" BU_SG_REL_ UPA_LS SG_ 2150408192 TrnsShftLvrPos 1;
BA_REL_ "GenSigVDAFailComment" BU_SG_REL_ UPA_LS SG_ 2150408192 TrnsShftLvrPos "Transmission Virtual Device Availability";
BA_REL_ "GenSigVBitResp" BU_SG_REL_ UPA_LS SG_ 2150408192 TrnsShftLvrPos 1;
BA_REL_ "GenSigSuprvResp" BU_SG_REL_ SDM_LS SG_ 2150408192 TrnsShftLvrPos 1;
BA_REL_ "GenSigVDAFailResp" BU_SG_REL_ SDM_LS SG_ 2150408192 TrnsShftLvrPos 1;
BA_REL_ "GenSigVDAFailComment" BU_SG_REL_ SDM_LS SG_ 2150408192 TrnsShftLvrPos "Transmission Virtual Device Availability";
BA_REL_ "GenSigVBitResp" BU_SG_REL_ SDM_LS SG_ 2150408192 TrnsShftLvrPos 1;
BA_REL_ "GenSigSuprvResp" BU_SG_REL_ SDM_LS SG_ 2150408192 EngSpd 1;
BA_REL_ "GenSigVDAFailResp" BU_SG_REL_ SDM_LS SG_ 2150408192 EngSpd 1;
BA_REL_ "GenSigVDAFailComment" BU_SG_REL_ SDM_LS SG_ 2150408192 EngSpd "Engine Virtual Device Availability";
BA_REL_ "GenSigSuprvResp" BU_SG_REL_ DCAC_LS SG_ 2150408192 EngSpd 1;
BA_REL_ "GenSigSuprvResp" BU_SG_REL_ ECC_LS SG_ 2150408192 EngSpd 1;
BA_REL_ "GenSigSuprvResp" BU_SG_REL_ PEPS_LS SG_ 2153971712 LftglsRelSwAct 1;
BA_REL_ "GenSigSuprvResp" BU_SG_REL_ PTM_LS SG_ 2153971712 LftglsAjrSwAct 1;
BA_REL_ "GenSigSuprvResp" BU_SG_REL_ SDM_LS SG_ 2153971712 DDAjrSwAtv 1;
BA_REL_ "GenSigSuprvResp" BU_SG_REL_ PEPS_LS SG_ 2153971712 DDAjrSwAtv 1;
BA_REL_ "GenSigSuprvResp" BU_SG_REL_ MSM_LS SG_ 2153971712 DDAjrSwAtv 1;
BA_REL_ "GenSigSuprvResp" BU_SG_REL_ VIS2_LS SG_ 2153971712 DDAjrSwAtv 1;
BA_REL_ "GenSigSuprvResp" BU_SG_REL_ EOCM_F_LS SG_ 2153971712 DDAjrSwAtv 1;
BA_REL_ "GenSigSuprvResp" BU_SG_REL_ ECC_LS SG_ 2153971712 DDAjrSwAtv 1;
BA_REL_ "GenSigSuprvResp" BU_SG_REL_ PTM_LS SG_ 2153971712 DDAjrSwAtv 1;
BA_REL_ "GenSigSuprvResp" BU_SG_REL_ UPA_LS SG_ 2149646336 VehSpdAvgNDrvn 1;
BA_REL_ "GenSigVDAFailResp" BU_SG_REL_ UPA_LS SG_ 2149646336 VehSpdAvgNDrvn 1;
BA_REL_ "GenSigVDAFailComment" BU_SG_REL_ UPA_LS SG_ 2149646336 VehSpdAvgNDrvn "EngVDA";
BA_REL_ "GenSigSuprvResp" BU_SG_REL_ SDM_LS SG_ 2149646336 VehSpdAvgNDrvn 1;
BA_REL_ "GenSigSuprvResp" BU_SG_REL_ EOCM_F_LS SG_ 2149646336 VehSpdAvgNDrvn 1;
BA_REL_ "GenSigRxStartValue" BU_SG_REL_ SDM_LS SG_ 2149646336 DistRollCntAvgDrvnV "0";
BA_REL_ "GenSigVDAFailResp" BU_SG_REL_ SDM_LS SG_ 2149646336 DistRollCntAvgDrvnV 1;
BA_REL_ "GenSigVDAFailComment" BU_SG_REL_ SDM_LS SG_ 2149646336 DistRollCntAvgDrvnV "Engine Virtual Device Availability";
BA_REL_ "GenSigSuprvResp" BU_SG_REL_ SBZA_R_LS SG_ 2149646336 DistRollCntAvgDrvn 1;
BA_REL_ "GenSigSuprvResp" BU_SG_REL_ SDM_LS SG_ 2149646336 DistRollCntAvgDrvn 1;
BA_REL_ "GenSigVDAFailResp" BU_SG_REL_ SDM_LS SG_ 2149646336 DistRollCntAvgDrvn 1;
BA_REL_ "GenSigVDAFailComment" BU_SG_REL_ SDM_LS SG_ 2149646336 DistRollCntAvgDrvn "Engine Virtual Device Availability";
BA_REL_ "GenSigVBitResp" BU_SG_REL_ SDM_LS SG_ 2149646336 DistRollCntAvgDrvn 1;
BA_REL_ "GenSigSuprvResp" BU_SG_REL_ SBZA_L_LS SG_ 2149646336 DistRollCntAvgDrvn 1;
BA_REL_ "GenSigVDAFailResp" BU_SG_REL_ SDM_LS SG_ 2149646336 VehSpdAvgDrvnV 1;
BA_REL_ "GenSigVDAFailComment" BU_SG_REL_ SDM_LS SG_ 2149646336 VehSpdAvgDrvnV "Engine Virtual Device Availability";
BA_REL_ "GenSigSuprvResp" BU_SG_REL_ UPA_LS SG_ 2149646336 VehSpdAvgDrvn 1;
BA_REL_ "GenSigVDAFailResp" BU_SG_REL_ UPA_LS SG_ 2149646336 VehSpdAvgDrvn 1;
BA_REL_ "GenSigVDAFailComment" BU_SG_REL_ UPA_LS SG_ 2149646336 VehSpdAvgDrvn "EngVDA";
BA_REL_ "GenSigSuprvResp" BU_SG_REL_ SDM_LS SG_ 2149646336 VehSpdAvgDrvn 1;
BA_REL_ "GenSigVDAFailResp" BU_SG_REL_ SDM_LS SG_ 2149646336 VehSpdAvgDrvn 1;
BA_REL_ "GenSigVDAFailComment" BU_SG_REL_ SDM_LS SG_ 2149646336 VehSpdAvgDrvn "Engine Virtual Device Availability";
BA_REL_ "GenSigVBitResp" BU_SG_REL_ SDM_LS SG_ 2149646336 VehSpdAvgDrvn 1;
BA_REL_ "GenSigSuprvResp" BU_SG_REL_ EOCM_F_LS SG_ 2149646336 VehSpdAvgDrvn 1;
BA_REL_ "GenSigSuprvResp" BU_SG_REL_ SBZA_L_LS SG_ 2149646336 VehSpdAvgDrvn 1;
BA_REL_ "GenSigSuprvResp" BU_SG_REL_ VIS2_LS SG_ 2149646336 VehSpdAvgDrvn 1;
BA_REL_ "GenSigSuprvResp" BU_SG_REL_ PTM_LS SG_ 2149646336 VehSpdAvgDrvn 1;
BA_REL_ "GenSigVDAFailResp" BU_SG_REL_ PTM_LS SG_ 2149646336 VehSpdAvgDrvn 1;
BA_REL_ "GenSigVDAFailComment" BU_SG_REL_ PTM_LS SG_ 2149646336 VehSpdAvgDrvn "Engine Virtual Device Availability";
BA_REL_ "GenSigVBitResp" BU_SG_REL_ PTM_LS SG_ 2149646336 VehSpdAvgDrvn 1;
BA_REL_ "GenSigSuprvResp" BU_SG_REL_ SBZA_R_LS SG_ 2149851136 SysPwrMd 1;
BA_REL_ "GenSigVBitResp" BU_SG_REL_ SBZA_R_LS SG_ 2149851136 SysPwrMd 1;
BA_REL_ "GenSigSuprvResp" BU_SG_REL_ UPA_LS SG_ 2149851136 SysPwrMd 1;
BA_REL_ "GenSigVBitResp" BU_SG_REL_ UPA_LS SG_ 2149851136 SysPwrMd 1;
BA_REL_ "GenSigSuprvResp" BU_SG_REL_ SDM_LS SG_ 2149851136 SysPwrMd 1;
BA_REL_ "GenSigVBitResp" BU_SG_REL_ SDM_LS SG_ 2149851136 SysPwrMd 1;
BA_REL_ "GenSigSuprvResp" BU_SG_REL_ PEPS_LS SG_ 2149851136 SysPwrMd 1;
BA_REL_ "GenSigVBitResp" BU_SG_REL_ PEPS_LS SG_ 2149851136 SysPwrMd 1;
BA_REL_ "GenSigSuprvResp" BU_SG_REL_ MSM_LS SG_ 2149851136 SysPwrMd 1;
BA_REL_ "GenSigVBitResp" BU_SG_REL_ MSM_LS SG_ 2149851136 SysPwrMd 1;
BA_REL_ "GenSigSuprvResp" BU_SG_REL_ HFP_LS SG_ 2149851136 SysPwrMd 1;
BA_REL_ "GenSigVBitResp" BU_SG_REL_ HFP_LS SG_ 2149851136 SysPwrMd 1;
BA_REL_ "GenSigSuprvResp" BU_SG_REL_ ECC_LS SG_ 2149851136 SysPwrMd 1;
BA_REL_ "GenSigVBitResp" BU_SG_REL_ ECC_LS SG_ 2149851136 SysPwrMd 1;
BA_REL_ "GenSigSuprvResp" BU_SG_REL_ DCAC_LS SG_ 2149851136 SysPwrMd 1;
BA_REL_ "GenSigVBitResp" BU_SG_REL_ DCAC_LS SG_ 2149851136 SysPwrMd 1;
BA_REL_ "GenSigSuprvResp" BU_SG_REL_ SBZA_L_LS SG_ 2149851136 SysPwrMd 1;
BA_REL_ "GenSigVBitResp" BU_SG_REL_ SBZA_L_LS SG_ 2149851136 SysPwrMd 1;
BA_REL_ "GenSigSuprvResp" BU_SG_REL_ VIS2_LS SG_ 2149851136 SysPwrMd 1;
BA_REL_ "GenSigVBitResp" BU_SG_REL_ VIS2_LS SG_ 2149851136 SysPwrMd 1;
BA_REL_ "GenSigSuprvResp" BU_SG_REL_ AOS_LS SG_ 2149851136 SysPwrMd 1;
BA_REL_ "GenSigVBitResp" BU_SG_REL_ AOS_LS SG_ 2149851136 SysPwrMd 1;
BA_REL_ "GenSigSuprvResp" BU_SG_REL_ PTM_LS SG_ 2149851136 SysPwrMd 1;
BA_REL_ "GenSigVBitResp" BU_SG_REL_ PTM_LS SG_ 2149851136 SysPwrMd 1;
BA_REL_ "GenSigRxStartValue" BU_SG_REL_ SBZA_R_LS SG_ 2149851136 SysPwrMdV "1";
BA_REL_ "GenSigRxStartValue" BU_SG_REL_ UPA_LS SG_ 2149851136 SysPwrMdV "1";
BA_REL_ "GenSigRxStartValue" BU_SG_REL_ SDM_LS SG_ 2149851136 SysPwrMdV "1";
BA_REL_ "GenSigRxStartValue" BU_SG_REL_ PEPS_LS SG_ 2149851136 SysPwrMdV "1";
BA_REL_ "GenSigRxStartValue" BU_SG_REL_ MSM_LS SG_ 2149851136 SysPwrMdV "1";
BA_REL_ "GenSigRxStartValue" BU_SG_REL_ HFP_LS SG_ 2149851136 SysPwrMdV "1";
BA_REL_ "GenSigRxStartValue" BU_SG_REL_ ECC_LS SG_ 2149851136 SysPwrMdV "1";
BA_REL_ "GenSigRxStartValue" BU_SG_REL_ DCAC_LS SG_ 2149851136 SysPwrMdV "1";
BA_REL_ "GenSigRxStartValue" BU_SG_REL_ SBZA_L_LS SG_ 2149851136 SysPwrMdV "1";
BA_REL_ "GenSigRxStartValue" BU_SG_REL_ AOS_LS SG_ 2149851136 SysPwrMdV "1";
BA_REL_ "GenSigRxStartValue" BU_SG_REL_ VIS2_LS SG_ 2149851136 SysPwrMdV "1";
BA_REL_ "GenSigRxStartValue" BU_SG_REL_ PTM_LS SG_ 2149851136 SysPwrMdV "1";
BA_REL_ "GenSigSuprvResp" BU_SG_REL_ UPA_LS SG_ 2151718912 ChmAct 1;
BA_REL_ "GenSigSuprvResp" BU_SG_REL_ PTM_LS SG_ 2151718912 ChmAct 1;
BA_REL_ "GenSigSuprvResp" BU_SG_REL_ SDM_LS SG_ 2151718912 ChmAct 1;
BA_REL_ "GenSigRxStartValue" BU_SG_REL_ SDM_LS SG_ 2151718912 ChmAct "0";
BA_REL_ "GenSigSuprvResp" BU_SG_REL_ EOCM_F_LS SG_ 2151718912 ChmAct 1;
BA_REL_ "GenSigSuprvResp" BU_SG_REL_ BCM_LS SG_ 2151718912 ChmAct 1;
VAL_ 2151284736 PrkAstOprtrDsrdStat_1D0 0 "Off" 1 "On" 2 "Tow Bar Attached" ;
VAL_ 2151284736 TnDrvPrkAstOffUnbIO 1 "true" 0 "false" ;
VAL_ 2151284736 PrkAstFld 1 "true" 0 "false" ;
VAL_ 2151284736 PrkAstSnsDistrbdIO 1 "true" 0 "false" ;
VAL_ 2151284736 PrkAsstDisablIO 1 "true" 0 "false" ;
VAL_ 2151284736 PrkAstSnrsBlk 1 "true" 0 "false" ;
VAL_ 2151284736 PrkAsstClnPrkAstIO 1 "true" 0 "false" ;
VAL_ 2159026176 ODD_InvldData 1 "true" 0 "false" ;
VAL_ 2159026176 ODD_DataType 21 "Bitmap" 20 "DecimalShort" 19 "HoursOfDay" 18 "Character" 17 "Fuel Consumption Inverted" 16 "Fuel Consumption" 15 "Pressure" 14 "Temperature" 13 "Volume" 12 "DistanceShort" 11 "DistanceLong" 10 "BitmapId" 9 "TextId" 8 "Pictogram" 7 "List " 6 "Date" 5 "Time " 4 "Decimal" 3 "EnumerationValue" 2 "Integer" 1 "String" 0 "Speed" ;
VAL_ 2151317504 PrkAstRrSysStat 3 "Failed" 2 "Inhibited" 1 "Enabled" 0 "Disabled" ;
VAL_ 2151317504 PARrRgn4ObjStat 15 "Zone 15" 14 "Zone 14" 13 "Zone 13" 12 "Zone 12" 11 "Zone 11" 10 "Zone 10" 9 "Zone 9" 8 "Zone 8" 7 "Zone 7" 6 "Zone 6" 5 "Zone 5" 4 "Zone 4" 3 "Zone 3" 2 "Zone 2" 1 "Zone 1" 0 "No Object" ;
VAL_ 2151317504 PARrRgn3ObjStat 15 "Zone 15" 14 "Zone 14" 13 "Zone 13" 12 "Zone 12" 11 "Zone 11" 10 "Zone 10" 9 "Zone 9" 8 "Zone 8" 7 "Zone 7" 6 "Zone 6" 5 "Zone 5" 4 "Zone 4" 3 "Zone 3" 2 "Zone 2" 1 "Zone 1" 0 "No Object" ;
VAL_ 2151317504 PARrRgn2ObjStat 15 "Zone 15" 14 "Zone 14" 13 "Zone 13" 12 "Zone 12" 11 "Zone 11" 10 "Zone 10" 9 "Zone 9" 8 "Zone 8" 7 "Zone 7" 6 "Zone 6" 5 "Zone 5" 4 "Zone 4" 3 "Zone 3" 2 "Zone 2" 1 "Zone 1" 0 "No Object" ;
VAL_ 2151317504 PARrRgn1ObjStat 15 "Zone 15" 14 "Zone 14" 13 "Zone 13" 12 "Zone 12" 11 "Zone 11" 10 "Zone 10" 9 "Zone 9" 8 "Zone 8" 7 "Zone 7" 6 "Zone 6" 5 "Zone 5" 4 "Zone 4" 3 "Zone 3" 2 "Zone 2" 1 "Zone 1" 0 "No Object" ;
VAL_ 2151301120 PrkAsstRrOffIO 1 "true" 0 "false" ;
VAL_ 2151301120 PrkAstAdvSysAct 1 "true" 0 "false" ;
VAL_ 2151301120 PrkAstFrSysStat 3 "Failed" 2 "Inhibited" 1 "Enabled" 0 "Disabled" ;
VAL_ 2151301120 PAFrtRgn4ObjStat 15 "Zone 15" 14 "Zone 14" 13 "Zone 13" 12 "Zone 12" 11 "Zone 11" 10 "Zone 10" 9 "Zone 9" 8 "Zone 8" 7 "Zone 7" 6 "Zone 6" 5 "Zone 5" 4 "Zone 4" 3 "Zone 3" 2 "Zone 2" 1 "Zone 1" 0 "No Object" ;
VAL_ 2151301120 PAFrtRgn3ObjStat 15 "Zone 15" 14 "Zone 14" 13 "Zone 13" 12 "Zone 12" 11 "Zone 11" 10 "Zone 10" 9 "Zone 9" 8 "Zone 8" 7 "Zone 7" 6 "Zone 6" 5 "Zone 5" 4 "Zone 4" 3 "Zone 3" 2 "Zone 2" 1 "Zone 1" 0 "No Object" ;
VAL_ 2151301120 PAFrtRgn2ObjStat 15 "Zone 15" 14 "Zone 14" 13 "Zone 13" 12 "Zone 12" 11 "Zone 11" 10 "Zone 10" 9 "Zone 9" 8 "Zone 8" 7 "Zone 7" 6 "Zone 6" 5 "Zone 5" 4 "Zone 4" 3 "Zone 3" 2 "Zone 2" 1 "Zone 1" 0 "No Object" ;
VAL_ 2151301120 PAFrtRgn1ObjStat 15 "Zone 15" 14 "Zone 14" 13 "Zone 13" 12 "Zone 12" 11 "Zone 11" 10 "Zone 10" 9 "Zone 9" 8 "Zone 8" 7 "Zone 7" 6 "Zone 6" 5 "Zone 5" 4 "Zone 4" 3 "Zone 3" 2 "Zone 2" 1 "Zone 1" 0 "No Object" ;
VAL_ 2155003904 LftLnChgThrt 1 "true" 0 "false" ;
VAL_ 2155003904 SBZATmpUnvIndOn 1 "true" 0 "false" ;
VAL_ 2155003904 SBZASysSrvIndOn 1 "true" 0 "false" ;
VAL_ 2155003904 SBZASysOffIndOn 1 "true" 0 "false" ;
VAL_ 2155003904 SBZASysClnIndOn 1 "true" 0 "false" ;
VAL_ 2150850560 DrSbltAtcV 1 "Invalid" 0 "Valid" ;
VAL_ 2150850560 DrSbltAtc 1 "true" 0 "false" ;
VAL_ 2150850560 PsSbltAtcV 1 "Invalid" 0 "Valid" ;
VAL_ 2150850560 PsSbltAtc 1 "true" 0 "false" ;
VAL_ 2151735296 RtSdDetSysServDsbld 1 "true" 0 "false" ;
VAL_ 2151735296 RtSdDetSysTmpDsbld 1 "true" 0 "false" ;
VAL_ 2151735296 RtLnChgAlrtEnbld 1 "true" 0 "false" ;
VAL_ 2151735296 RtSBZAlrtEnbld 1 "true" 0 "false" ;
VAL_ 2151735296 RtRrCrsTrfcAlrtEnbld 1 "true" 0 "false" ;
VAL_ 2151735296 LnChgAlrtOffIndOn 1 "true" 0 "false" ;
VAL_ 2151735296 RrCrsTrfcAlrtOffIO 1 "true" 0 "false" ;
VAL_ 2150776832 SftyMuteRd 1 "true" 0 "false" ;
VAL_ 2150776832 ShfUlkBrToShftIndCtrl 1 "true" 0 "false" ;
VAL_ 2150776832 ShftLkdBuStbltIndCtrl 1 "true" 0 "false" ;
VAL_ 2150776832 HybImpSnsDsbld 1 "true" 0 "false" ;
VAL_ 2150776832 HybVehHiVltInvDisRqd 1 "true" 0 "false" ;
VAL_ 2150776832 SbItlkTrnsShftLvLkRd 1 "true" 0 "false" ;
VAL_ 2150776832 MmryRclImpctDisRq 1 "Disable Recall" 0 "Enable Recall" ;
VAL_ 2150776832 EvntEnbld 1 "true" 0 "false" ;
VAL_ 2150760448 NotSndRwRtSeatStat 0 "Unknown" 1 "Unfastened" 2 "Fastened" ;
VAL_ 2150760448 NotSndRwMdlSeatStat 0 "Unknown" 1 "Unfastened" 2 "Fastened" ;
VAL_ 2150760448 NotSndRwLtSeatStat 0 "Unknown" 1 "Unfastened" 2 "Fastened" ;
VAL_ 2150760448 NotPsSeatStat 0 "Unknown" 1 "Unfastened" 2 "Fastened" ;
VAL_ 2150760448 NotDrvSeatStat 0 "Unknown" 1 "Unfastened" 2 "Fastened" ;
VAL_ 2150760448 NotSecRowRtSeaOccStat 2 "Occupied" 1 "Empty" 0 "Unknown" ;
VAL_ 2150760448 NotSecRowLeSeaOccStat 2 "Occupied" 1 "Empty" 0 "Unknown" ;
VAL_ 2150760448 NotSecRowCtSeaOccStat 2 "Occupied" 1 "Empty" 0 "Unknown" ;
VAL_ 2150760448 NotiFrntPasSeatOccSta 5 "OccupiedLarge" 4 "OccupiedSmall" 3 "OccupiedChildseat" 2 "OccupiedUnknown" 1 "Empty" 0 "Unknown" ;
VAL_ 2150760448 NEDLSRtSdArbgDld 1 "true" 0 "false" ;
VAL_ 2150760448 NEDLSLtSdArbgDld 1 "true" 0 "false" ;
VAL_ 2150760448 NEDLSSdCrtnArbgDpld 1 "true" 0 "false" ;
VAL_ 2150760448 NEDLSPaFrSt2De 1 "true" 0 "false" ;
VAL_ 2150760448 NEDLSPaFrSt1De 1 "true" 0 "false" ;
VAL_ 2150760448 NEDLSDrFrSt2De 1 "true" 0 "false" ;
VAL_ 2150760448 NEDLSDrFrSt1De 1 "true" 0 "false" ;
VAL_ 2150760448 NotEventStat 2 "Pretensioner Deployment Event" 1 "Near Deployment Event" 0 "No Event" 3 "Airbag Deployment Event" ;
VAL_ 2150760448 SIRDpl 1 "true" 0 "false" ;
VAL_ 2150760448 NESSRoSevSt 1 "true" 0 "false" ;
VAL_ 2150760448 NESSRiSiSevSt 1 "true" 0 "false" ;
VAL_ 2150760448 NESSReImpSevSt 1 "true" 0 "false" ;
VAL_ 2150760448 NESSLeSiSevSt 1 "true" 0 "false" ;
VAL_ 2150760448 NESSFrImpSt2SevSt 1 "true" 0 "false" ;
VAL_ 2150760448 NESSFrImpSt1SevSt 1 "true" 0 "false" ;
VAL_ 2150760448 NESSFrImpPreSevSt 1 "true" 0 "false" ;
VAL_ 2151112704 FrPasSeatbltRemOccSt 1 "Occupied" 0 "Empty" ;
VAL_ 2151112704 FrPasSeatResCtrlOccStV 1 "Invalid" 0 "Valid" ;
VAL_ 2151112704 FrPasSeatResCtrlOccSt 2 "Occupied" 1 "Empty" 0 "Unknown" ;
VAL_ 2151112704 FrPsSeatOccSnsOpMd 3 "SystemInitMod" 2 "BarrierMod" 1 "ZeroSetCheckMod" 0 "FieldMod" ;
VAL_ 2151112704 FrPsSeatOccFltSt 2 "Fault Present - Vehicle Mismatch" 1 "Fault Present" 0 "No Faults Present" ;
VAL_ 2151112704 FrntPassClass 7 "Large Adult" 6 "Small Adult" 5 "Large Child" 4 "Small Child" 3 "Child Seat Unknown" 2 "Child Seat Forward" 1 "Child Seat Rearward" 0 "Classification Not Applicable" ;
VAL_ 2154496000 ShftrUnlkdBrkToShftIO 1 "true" 0 "false" ;
VAL_ 2154496000 ShftrLkdBklPsnStbltIO 1 "true" 0 "false" ;
VAL_ 2154496000 ShftrLkdBklDrvStbltIO 1 "true" 0 "false" ;
VAL_ 2154496000 CmpSftTopMotBfrOpTrnkIO 1 "true" 0 "false" ;
VAL_ 2154496000 TargaTopStateV 1 "Invalid" 0 "Valid" ;
VAL_ 2154496000 TargaTopState 0 "Open" 1 "Closed" ;
VAL_ 2154471424 RrClsrSnwLdIO 1 "true" 0 "false" ;
VAL_ 2154471424 RrClosAjarSwAct 1 "true" 0 "false" ;
VAL_ 2151063552 TrfRdsdInfCsStReq 7 "Reserved5" 6 "Reserved4" 5 "Reserved3" 4 "Reserved2" 3 "Reserved1" 2 "On" 1 "Off" 0 "No Action" ;
VAL_ 2151063552 IntrStopAlrtCsSetReq 7 "Reserved4" 6 "Reserved3" 5 "Reserved2" 4 "Reserved1" 3 "Alert and Brake" 2 "Alert " 1 "Off" 0 "No Action" ;
VAL_ 2151063552 CntdVehBrAltCsStReq 7 "Reserved5" 6 "Reserved4" 5 "Reserved3" 4 "Reserved2" 3 "Reserved1" 2 "On" 1 "Off" 0 "No Action" ;
VAL_ 2151063552 ICSTS_TchPrxmty 2 "Touch" 1 "Near" 0 "Far" ;
VAL_ 2151063552 TrgdVidRecSwAct 1 "true" 0 "false" ;
VAL_ 2151063552 RrPedDetCstStReq 7 "Reserved3" 6 "Reserved2" 5 "Reserved1" 4 "Alert and Brake" 3 "Alert" 2 "On" 1 "Off" 0 "No Action" ;
VAL_ 2151063552 CamVideoICSDispAct 1 "true" 0 "false" ;
VAL_ 2151063552 Frnt360CamSwAct 1 "true" 0 "false" ;
VAL_ 2151063552 ValetMdAct 1 "true" 0 "false" ;
VAL_ 2151063552 InftnOprAlwd 1 "true" 0 "false" ;
VAL_ 2155167744 ClsEngCmprtmtToStrtVehIO 1 "true" 0 "false" ;
VAL_ 2155167744 PrsCltchPrsStrtAgnIO 1 "true" 0 "false" ;
VAL_ 2155167744 PrsStrtAgnIO 1 "true" 0 "false" ;
VAL_ 2155167744 AutoShtdwnDsblIO 1 "true" 0 "false" ;
VAL_ 2155167744 ShftToNtrlIO 1 "true" 0 "false" ;
VAL_ 2155167744 AppPrkBrkIO 1 "true" 0 "false" ;
VAL_ 2155167744 NRmtDtctdRstrtAllwd 1 "true" 0 "false" ;
VAL_ 2155167744 NRmtDtdPsCluRstIO 1 "true" 0 "false" ;
VAL_ 2155167744 SecPwrMdPshBtnAtv 1 "true" 0 "false" ;
VAL_ 2155167744 TSLgMdPwrCtOWAtv 1 "true" 0 "false" ;
VAL_ 2155167744 PrsBtnAgnTTrnEngOffIO 1 "true" 0 "false" ;
VAL_ 2155167744 NRmtDtdPsBrkRstIO 1 "true" 0 "false" ;
VAL_ 2155167744 NoReDetInOn 1 "true" 0 "false" ;
VAL_ 2155167744 ApplyCltPdlIO 1 "true" 0 "false" ;
VAL_ 2155167744 TransModInactIO 1 "true" 0 "false" ;
VAL_ 2155167744 TransModActIO 1 "true" 0 "false" ;
VAL_ 2155167744 ApplyBrkPdlIO 1 "true" 0 "false" ;
VAL_ 2155167744 Ky_IdDevPr 1 "true" 0 "false" ;
VAL_ 2155167744 KylsStrtUseTxPckIO 1 "true" 0 "false" ;
VAL_ 2155167744 ShftPrkIO 1 "true" 0 "false" ;
VAL_ 2155167744 VehMovState 4 "Invalid" 3 "Reverse" 2 "Forward" 1 "Neutral" 0 "Parked" ;
VAL_ 2155167744 TrStLgMdAtv 1 "true" 0 "false" ;
VAL_ 2151677952 SndLocRtRr 1 "true" 0 "false" ;
VAL_ 2151677952 SndLocLftRr 1 "true" 0 "false" ;
VAL_ 2151677952 SndLocPasFr 1 "true" 0 "false" ;
VAL_ 2151677952 SndLocDrFr 1 "true" 0 "false" ;
VAL_ 2151677952 SC_SndTne 10 "Beep (750 Hz) Radio Source Muted" 9 "High Frequency Broadband" 8 "Harp" 7 "Gong (2000 Hz)" 6 "Gong (750 Hz)" 5 "Beep (2000 Hz)" 4 "Beep (750 Hz)" 3 "Click-Clack" 2 "Click" 1 "Clack" 0 "Clock" 14 "No Chime with Radio Source Muted" 13 "Gong (2000 Hz) Radio Source Muted" 12 "Gong (750 Hz) Radio Source Muted" 11 "Beep (2000 Hz) Radio Source Muted" ;
VAL_ 2149859328 SysBkUpPwrMdV 1 "Invalid" 0 "Valid" ;
VAL_ 2149859328 SysBkupPwrMdEn 1 "true" 0 "false" ;
VAL_ 2149859328 SysBkUpPwrMd 3 "Crank Request" 2 "Run" 1 "Accessory" 0 "Off" ;
VAL_ 2150604800 RRDoorAjarSwAct 1 "true" 0 "false" ;
VAL_ 2150588416 PDAjrSwAtv 1 "true" 0 "false" ;
VAL_ 2150596608 RLDoorAjarSwAct 1 "true" 0 "false" ;
VAL_ 2150416384 PTWrmgWtToShftIO 1 "true" 0 "false" ;
VAL_ 2150416384 EngTrqActExtRngV 1 "Invalid" 0 "Valid" ;
VAL_ 2150416384 VehTopSpdLmtMdAct 1 "true" 0 "false" ;
VAL_ 2150416384 EngIdlAtv 1 "true" 0 "false" ;
VAL_ 2150416384 EngSpdStat 3 "Invalid" 1 "Degraded Operation" 0 "Normal Operation" ;
VAL_ 2150416384 VaccBoostFailure 1 "true" 0 "false" ;
VAL_ 2150416384 RmVhStrtEngRng 1 "true" 0 "false" ;
VAL_ 2150416384 GenFld 1 "true" 0 "false" ;
VAL_ 2150416384 EngSpdLmtnMdAct 1 "true" 0 "false" ;
VAL_ 2150416384 EngNEmsnsRelMalfAct 1 "true" 0 "false" ;
VAL_ 2150416384 EngCstFlCutAct 1 "true" 0 "false" ;
VAL_ 2150416384 EngBstPrsIndV 1 "Invalid" 0 "Valid" ;
VAL_ 2150416384 TrnCrpMdAtv 1 "true" 0 "false" ;
VAL_ 2150416384 TrnsVDA 1 "VirtualDeviceAvailable" 0 "VirtualDeviceUnavailable" ;
VAL_ 2150416384 TransEstGear 9 "Ninth Gear" 15 "Park Gear" 14 "Reverse Gear" 13 "Neutral Gear" 12 "CVT Forward Gear" 11 "Unused and Reserved" 10 "Tenth Gear" 8 "Eighth Gear" 7 "Seventh Gear" 6 "Sixth Gear" 5 "Fifth Gear" 4 "Fourth Gear" 3 "Third Gear" 2 "Second Gear" 1 "First Gear" 0 "Not Supported" ;
VAL_ 2150416384 TransEstGearV 1 "Invalid" 0 "Valid" ;
VAL_ 2150416384 EngVDA 1 "VirtualDeviceAvailable" 0 "VirtualDeviceUnavailable" ;
VAL_ 2150416384 EngRunAtv 1 "true" 0 "false" ;
VAL_ 2150416384 EngCylDeactMd 3 "Reactivation In Progress" 2 "Half of Total Cylinders Active" 1 "Deactivation In Progress" 0 "All Cylinders Active" ;
VAL_ 2150408192 ElcRngSelDrvAct 1 "true" 0 "false" ;
VAL_ 2150408192 TmpDrvrShftCtlAct 1 "true" 0 "false" ;
VAL_ 2150408192 AdptPsngrSeatStng 7 "Performance Mode 7" 6 "Performance Mode 6" 5 "Performance Mode 5" 4 "Performance Mode 4" 3 "Performance Mode 3" 2 "Performance Mode 2" 1 "Performance Mode 1" 0 "No Action" ;
VAL_ 2150408192 EngRunng 1 "true" 0 "false" ;
VAL_ 2150408192 Eng12vStrtrMtrCmmdOn 1 "true" 0 "false" ;
VAL_ 2150408192 AccPdlOvrrdAtv 1 "true" 0 "false" ;
VAL_ 2150408192 TopTrvlCltchSwActV 1 "Invalid" 0 "Valid" ;
VAL_ 2150408192 TopTrvlCltchSwAct 1 "true" 0 "false" ;
VAL_ 2150408192 CltStartSwAtvV 1 "Invalid" 0 "Valid" ;
VAL_ 2150408192 CltStartSwAtv 1 "true" 0 "false" ;
VAL_ 2150408192 CrsCntEnbld 1 "true" 0 "false" ;
VAL_ 2150408192 AccActPosV 1 "Invalid" 0 "Valid" ;
VAL_ 2150408192 TrnsSftMdStat 3 "Automatic Grade Braking Mode" 2 "Lift-Foot Cornering Mode" 1 "Performance Mode" 0 "No Override Mode" ;
VAL_ 2150408192 AutoTransComndGear 9 "Ninth Gear" 15 "Park Gear" 14 "Reverse Gear" 13 "Neutral Gear" 12 "CVT Forward Gear" 11 "Unused and Reserved" 10 "Tenth Gear" 8 "Eighth Gear" 7 "Seventh Gear" 6 "Sixth Gear" 5 "Fifth Gear" 4 "Fourth Gear" 3 "Third Gear" 2 "Second Gear" 1 "First Gear" 0 "Not Supported" ;
VAL_ 2150408192 TrnShftPtrnActStat 6 "PT Protection Pattern Active" 5 "PT Non-Protection Pattern Active" 4 "Shift Pattern 4 Active" 3 "Shift Pattern 3 Active" 2 "Shift Pattern 2 Active" 1 "Shift Pattern 1 Active" 0 "Default Shift Pattern Active" ;
VAL_ 2150408192 ThrPosV 1 "Invalid" 0 "Valid" ;
VAL_ 2150408192 TransTUDMdStat 2 "Electronic Range Select Active" 1 "Driver Shift Control Active" 0 "No Activation" ;
VAL_ 2150408192 TrnsShftLvrPosV 1 "Invalid" 0 "Valid" ;
VAL_ 2150408192 TrnsShftLvrPos 13 "Forward Range J" 12 "Froward Range I" 15 "Lever Position Unknown" 11 "Forward Range H" 10 "Forward Range G" 9 "Forward Range F" 8 "Forward Range E" 7 "Forward Range D" 6 "Forward Range C" 5 "Forward Range B" 4 "Forward Range A" 3 "Neutral Range" 2 "Reverse Range" 1 "Park Range" 0 "Between Ranges" ;
VAL_ 2153971712 LftglsRelSwAct 1 "true" 0 "false" ;
VAL_ 2153971712 LftglsAjrSwAct 1 "true" 0 "false" ;
VAL_ 2153971712 DDAjrSwAtvM 0 "Don't Use Data" 1 "Use Data" ;
VAL_ 2153971712 DDAjrSwAtv 1 "true" 0 "false" ;
VAL_ 2151792640 RCTARIC_Indctr1Act 1 "true" 0 "false" ;
VAL_ 2151792640 RCTARIC_IndReq 0 "Off" 1 "Continuous Indication" 2 "Flashing Indication" ;
VAL_ 2151776256 RCTALIC_Indctr1Act 1 "true" 0 "false" ;
VAL_ 2151776256 RCTALIC_IndReq 0 "Off" 1 "Continuous Indication" 2 "Flashing Indication" ;
VAL_ 2149646336 VehSpdAvgDrvnSrc 1 "Wheel Speed" 0 "Transmission Output Speed" ;
VAL_ 2149646336 DstRolCntAvgNonDrvnV 1 "Invalid" 0 "Valid" ;
VAL_ 2149646336 DstRolCntAvNDrRstOc 1 "true" 0 "false" ;
VAL_ 2149646336 DstRolCntAvgDrnRstOc 1 "true" 0 "false" ;
VAL_ 2149646336 DistRollCntAvgDrvnSrc 1 "Wheel Speed" 0 "Transmission Output Speed" ;
VAL_ 2149646336 VehSpdAvgNDrvnV 1 "Invalid" 0 "Valid" ;
VAL_ 2149646336 DistRollCntAvgDrvnV 1 "Invalid" 0 "Valid" ;
VAL_ 2149646336 VehSpdAvgDrvnV 1 "Invalid" 0 "Valid" ;
VAL_ 2149851136 KylsStrtAuthRq 1 "true" 0 "false" ;
VAL_ 2149851136 SysPwrMd 3 "Crank Request" 2 "Run" 1 "Accessory" 0 "Off" ;
VAL_ 2149851136 SysPwrMdV 1 "Invalid" 0 "Valid" ;
VAL_ 2151718912 ChmVolSt 0 "Normal" 1 "Loud" ;
VAL_ 2151718912 ChmAct 1 "true" 0 "false" ;
VAL_ 2153775104 DTCI_DTCFaultType 3 "Type C" 2 "Type B" 1 "Type A" 0 "Not Supported" ;
VAL_ 2153775104 DTCI_CodeSupported 1 "true" 0 "false" ;
VAL_ 2153775104 DTCI_CurrentStatus 1 "true" 0 "false" ;
VAL_ 2153775104 DTCI_TstNPsdCdClrdSt 1 "true" 0 "false" ;
VAL_ 2153775104 DTCI_TstFldCdClrdStat 1 "true" 0 "false" ;
VAL_ 2153775104 DTCI_HistStat 1 "true" 0 "false" ;
VAL_ 2153775104 DTCI_TstNPsdPwrUpSt 1 "true" 0 "false" ;
VAL_ 2153775104 DTCI_TstFldPwrUpSt 1 "true" 0 "false" ;
VAL_ 2153775104 DTCI_WrnIndRqdSt 1 "true" 0 "false" ;
VAL_ 2153775104 DTCI_DTCTriggered 1 "true" 0 "false" ;
VAL_ 2153775104 DTCIUnused7 1 "true" 0 "false" ;
VAL_ 2153775104 DTCIUnused6 1 "true" 0 "false" ;
VAL_ 2153775104 DTCIUnused5 1 "true" 0 "false" ;
VAL_ 2153775104 DTCIUnused4 1 "true" 0 "false" ;
VAL_ 2153775104 DTCIUnused3 1 "true" 0 "false" ;
VAL_ 2153775104 DTCIUnused2 1 "true" 0 "false" ;
VAL_ 2153775104 DTCIUnused1 1 "true" 0 "false" ;
SIG_GROUP_ 2158755840 ODIEvntPkt 1 : ODIE_MultiFrRetCh ODIE_FUCID ODIE_EvID;
SIG_GROUP_ 2159026176 ODIDynData 1 : ODD_InvldData ODD_FUCID ODD_DataVal ODD_DataType ODD_DataId;
SIG_GROUP_ 2158936064 ODIEnmDynData 1 : ODIEDD_Data18Value ODIEDD_Data17Value ODIEDD_Data16Value ODIEDD_Data15Value ODIEDD_Data14Value ODIEDD_Data13Value ODIEDD_Data12Value ODIEDD_Data11Value ODIEDD_Data10Value ODIEDD_Data9Value ODIEDD_Data8Value ODIEDD_Data7Value ODIEDD_Data6Value ODIEDD_Data5Value ODIEDD_Data4Value ODIEDD_Data3Value ODIEDD_Data2Value ODIEDD_Data1Value ODIEDD_FUCID;
SIG_GROUP_ 2150760448 NoEvSevSt 1 : NESSRoSevSt NESSRiSiSevSt NESSReImpSevSt NESSLeSiSevSt NESSFrImpSt2SevSt NESSFrImpSt1SevSt NESSFrImpPreSevSt;
SIG_GROUP_ 2150760448 NoEvDeLoSt 1 : NEDLSRtSdArbgDld NEDLSLtSdArbgDld NEDLSSdCrtnArbgDpld NEDLSPaFrSt2De NEDLSPaFrSt1De NEDLSDrFrSt2De NEDLSDrFrSt1De;
SIG_GROUP_ 2151063552 ICSTchStat 1 : ICSTS_Y1TchCrdnt ICSTS_X1TchCrdnt ICSTS_TchPrxmty;
SIG_GROUP_ 2151677952 SndLoc 1 : SndLocRtRr SndLocLftRr SndLocPasFr SndLocDrFr;
SIG_GROUP_ 2151677952 SndChrs 1 : SC_SndDutCyc SC_NmofRp SC_SndCdnPrd SC_SndTne;
SIG_GROUP_ 2151792640 RrCrsTrfAltRgtIndCtrl 1 : RCTARIC_Indctr1Act RCTARIC_IndReq;
SIG_GROUP_ 2151776256 RrCrsTrfAltLftIndCtrl 1 : RCTALIC_Indctr1Act RCTALIC_IndReq;
SIG_GROUP_ 2153775104 DTCInfo 1 : DTCI_DTCFaultType DTCI_CodeSupported DTCI_CurrentStatus DTCI_TstNPsdCdClrdSt DTCI_TstFldCdClrdStat DTCI_HistStat DTCI_TstNPsdPwrUpSt DTCI_TstFldPwrUpSt DTCI_WrnIndRqdSt DTCI_DTCFailType DTCI_DTCNumber DTCI_DTCSource DTCI_DTCTriggered DTCIUnused7 DTCIUnused6 DTCIUnused5 DTCIUnused4 DTCIUnused3 DTCIUnused2 DTCIUnused1;
